VERSION ""

NS_ :

BS_:

BU_: ETH

BO_ 945 DAS_telemetryFurniture: 8 Vector__XXX
 SG_ DAS_TF_multiplexer M : 0|5@1+ (1,0) [0|0] "" Vector__XXX
 SG_ DAS_TF_furnitureIndex0 m0 : 5|8@1+ (1,0) [0|0] "" Vector__XXX
 SG_ DAS_TF_furnitureIndex1 m1 : 5|8@1+ (1,0) [0|0] "" Vector__XXX
 SG_ DAS_TF_furnitureIndex2 m2 : 5|8@1+ (1,0) [0|0] "" Vector__XXX
 SG_ DAS_TF_distTraveled m0 : 13|11@1+ (0.1,0) [0|0] "" Vector__XXX
 SG_ DAS_TF_juncStatus m2 : 13|4@1+ (1,0) [0|0] "" Vector__XXX
 SG_ DAS_TF_longitudinalDist m1 : 13|12@1+ (0.1,0) [0|0] "" Vector__XXX
 SG_ DAS_TF_juncDist m2 : 17|11@1+ (0.2,-20) [0|0] "" Vector__XXX
 SG_ DAS_TF_llType m0 : 24|3@1+ (1,0) [0|0] "" Vector__XXX
 SG_ DAS_TF_lateralDist m1 : 25|12@1+ (0.1,-204.8) [0|0] "" Vector__XXX
 SG_ DAS_TF_rlType m0 : 27|3@1+ (1,0) [0|0] "" Vector__XXX
 SG_ DAS_TF_stopLineDist m2 : 28|11@1+ (0.1,-10) [0|0] "" Vector__XXX
 SG_ DAS_TF_cipvDist m0 : 30|9@1+ (0.1,0) [0|0] "" Vector__XXX
 SG_ DAS_TF_height m1 : 37|12@1+ (0.05,0) [0|0] "" Vector__XXX
 SG_ DAS_TF_timeOfDay m0 : 39|3@1+ (1,0) [0|0] "" Vector__XXX
 SG_ DAS_TF_ttc m2 : 39|7@1+ (0.1,0) [0|0] "" Vector__XXX
 SG_ DAS_TF_furnitureType m0 : 42|3@1+ (1,0) [0|0] "" Vector__XXX
 SG_ DAS_TF_color m1 : 49|3@1+ (1,0) [0|0] "" Vector__XXX
 SG_ DAS_TF_shape m1 : 52|3@1+ (1,0) [0|0] "" Vector__XXX
 SG_ DAS_TF_orientation m1 : 55|2@1+ (1,0) [0|0] "" Vector__XXX
 SG_ DAS_TF_transmissionStatus m1 : 57|2@1+ (1,0) [0|0] "" Vector__XXX
 SG_ DAS_TF_isMain m1 : 59|1@1+ (1,0) [0|0] "" Vector__XXX
 SG_ DAS_TF_isTeslaMain m1 : 60|1@1+ (1,0) [0|0] "" Vector__XXX

BO_ 947 UI_vehicleControl2: 8 Vector__XXX
 SG_ UI_gloveboxRequest : 0|1@1+ (1,0) [0|0] "" Vector__XXX
 SG_ UI_trunkRequest : 1|1@1+ (1,0) [0|0] "" Vector__XXX
 SG_ UI_UMCUpdateInhibit : 2|1@1+ (1,0) [0|0] "" Vector__XXX
 SG_ UI_WCUpdateInhibit : 3|1@1+ (1,0) [0|0] "" Vector__XXX
 SG_ UI_soundHornOnLock : 4|1@1+ (1,0) [0|0] "" Vector__XXX
 SG_ UI_locksPanelActive : 5|1@1+ (1,0) [0|0] "" Vector__XXX
 SG_ UI_PINToDriveEnabled : 6|1@1+ (1,0) [0|0] "" Vector__XXX
 SG_ UI_PINToDrivePassed : 7|1@1+ (1,0) [0|0] "" Vector__XXX
 SG_ UI_disableMirrorAutoDim : 8|1@1+ (1,0) [0|0] "" Vector__XXX
 SG_ UI_lightSwitch : 9|3@1+ (1,0) [0|0] "" Vector__XXX
 SG_ UI_readyToAddKey : 12|1@1+ (1,0) [0|0] "" Vector__XXX
 SG_ UI_alarmTriggerRequest : 13|1@1+ (1,0) [0|0] "" Vector__XXX
 SG_ UI_VCSECFeature1 : 14|1@1+ (1,0) [0|0] "" Vector__XXX
 SG_ UI_VCLEFTFeature1 : 15|1@1+ (1,0) [0|0] "" Vector__XXX
 SG_ UI_summonState : 16|2@1+ (1,0) [0|0] "" Vector__XXX
 SG_ UI_displayOnForUser : 18|1@1+ (1,0) [0|0] "" Vector__XXX
 SG_ UI_freeRollModeRequest : 19|1@1+ (1,0) [0|0] "" Vector__XXX
 SG_ UI_BLEPushNotificationRequest : 20|1@1+ (1,0) [0|0] "" Vector__XXX
 SG_ UI_pairKeyQRCodeDisplaying : 21|1@1+ (1,0) [0|0] "" Vector__XXX
 SG_ UI_keepAutopilotAwake : 22|1@1+ (1,0) [0|0] "" Vector__XXX
 SG_ UI_batteryPreconditioningRequest : 23|1@1+ (1,0) [0|0] "" Vector__XXX
 SG_ UI_coastDownMode : 24|1@1+ (1,0) [0|0] "" Vector__XXX
 SG_ UI_autopilotPowerStateRequest : 25|2@1+ (1,0) [0|0] "" Vector__XXX
 SG_ UI_shorted12VCellTestMode : 27|2@1+ (1,0) [0|0] "" Vector__XXX
 SG_ UI_autoRollWindowsOnLockEnable : 29|1@1+ (1,0) [0|0] "" Vector__XXX
 SG_ UI_virtualPitchSensorOverrideOKForAim : 30|1@1+ (1,0) [0|0] "" Vector__XXX
 SG_ UI_conditionalLoggingEnabledVCSEC : 31|1@1+ (1,0) [0|0] "" Vector__XXX
 SG_ UI_WC3UpdateInhibit : 32|1@1+ (1,0) [0|0] "" Vector__XXX
 SG_ UI_steeringWheelHeatReq : 33|1@1+ (1,0) [0|0] "" Vector__XXX
 SG_ UI_disableHorn : 34|1@1+ (1,0) [0|0] "" Vector__XXX
 SG_ UI_frontRightSeatAutoClimateReq : 39|1@1+ (1,0) [0|0] "" Vector__XXX
 SG_ UI_sleepFeature1 : 51|1@1+ (1,0) [0|0] "" Vector__XXX
 SG_ UI_dcr12VThreshold : 52|4@1+ (1,0) [0|0] "" Vector__XXX
 SG_ UI_frontLeftSeatAutoClimateReq : 56|1@1+ (1,0) [0|0] "" Vector__XXX
 SG_ UI_wiperHeaterReq : 57|1@1+ (1,0) [0|0] "" Vector__XXX
 SG_ UI_tireSeason : 59|1@1+ (1,0) [0|0] "" Vector__XXX
 SG_ UI_saveTireConfigReq : 60|1@1+ (1,0) [0|0] "" Vector__XXX
 SG_ UI_silentAlarm : 61|1@1+ (1,0) [0|0] "" Vector__XXX
 SG_ UI_sleepFeature2 : 63|1@1+ (1,0) [0|0] "" Vector__XXX

BO_ 952 UI_tpmsRCPsetting: 8 Vector__XXX
 SG_ UI_setRCPFront : 16|8@1+ (0.025,0) [0|0] "" Vector__XXX
 SG_ UI_setRCPRear : 24|8@1+ (0.025,0) [0|0] "" Vector__XXX

BO_ 954 USM_alertMatrix: 8 Vector__XXX
 SG_ USM_matrixIndex M : 0|4@1+ (1,0) [0|0] "" Vector__XXX
 SG_ USM_a001_WatchdogReset m0 : 4|1@1+ (1,0) [0|0] "" Vector__XXX
 SG_ USM_a061_XCPConnected m1 : 4|1@1+ (1,0) [0|0] "" Vector__XXX
 SG_ USM_a181_s5Blocked m3 : 4|1@1+ (1,0) [0|0] "" Vector__XXX
 SG_ USM_a241_s2HwComErrDiagnostics m4 : 4|1@1+ (1,0) [0|0] "" Vector__XXX
 SG_ USM_a002_PowerLossReset m0 : 5|1@1+ (1,0) [0|0] "" Vector__XXX
 SG_ USM_a062_XCPWasConnected m1 : 5|1@1+ (1,0) [0|0] "" Vector__XXX
 SG_ USM_a182_s6Blocked m3 : 5|1@1+ (1,0) [0|0] "" Vector__XXX
 SG_ USM_a242_s3HwComErrDiagnostics m4 : 5|1@1+ (1,0) [0|0] "" Vector__XXX
 SG_ USM_a003_SWAssertion m0 : 6|1@1+ (1,0) [0|0] "" Vector__XXX
 SG_ USM_a063_SwitchFault m1 : 6|1@1+ (1,0) [0|0] "" Vector__XXX
 SG_ USM_a183_s7Blocked m3 : 6|1@1+ (1,0) [0|0] "" Vector__XXX
 SG_ USM_a243_s4HwComErrDiagnostics m4 : 6|1@1+ (1,0) [0|0] "" Vector__XXX
 SG_ USM_a064_busSleepReqTimeout m1 : 7|1@1+ (1,0) [0|0] "" Vector__XXX
 SG_ USM_a184_s8Blocked m3 : 7|1@1+ (1,0) [0|0] "" Vector__XXX
 SG_ USM_a244_s5HwComErrDiagnostics m4 : 7|1@1+ (1,0) [0|0] "" Vector__XXX
 SG_ USM_a005_CANTXError m0 : 8|1@1+ (1,0) [0|0] "" Vector__XXX
 SG_ USM_a185_s9Blocked m3 : 8|1@1+ (1,0) [0|0] "" Vector__XXX
 SG_ USM_a245_s6HwComErrDiagnostics m4 : 8|1@1+ (1,0) [0|0] "" Vector__XXX
 SG_ USM_a006_CANTX_cyclicError m0 : 9|1@1+ (1,0) [0|0] "" Vector__XXX
 SG_ USM_a186_s10Blocked m3 : 9|1@1+ (1,0) [0|0] "" Vector__XXX
 SG_ USM_a246_s7HwComErrDiagnostics m4 : 9|1@1+ (1,0) [0|0] "" Vector__XXX
 SG_ USM_a187_s11Blocked m3 : 10|1@1+ (1,0) [0|0] "" Vector__XXX
 SG_ USM_a247_s8HwComErrDiagnostics m4 : 10|1@1+ (1,0) [0|0] "" Vector__XXX
 SG_ USM_a188_s12Blocked m3 : 11|1@1+ (1,0) [0|0] "" Vector__XXX
 SG_ USM_a248_s9HwComErrDiagnostics m4 : 11|1@1+ (1,0) [0|0] "" Vector__XXX
 SG_ USM_a189_s1Disconnected m3 : 12|1@1+ (1,0) [0|0] "" Vector__XXX
 SG_ USM_a249_s10HwComErrDiagnostics m4 : 12|1@1+ (1,0) [0|0] "" Vector__XXX
 SG_ USM_a190_s2Disconnected m3 : 13|1@1+ (1,0) [0|0] "" Vector__XXX
 SG_ USM_a250_s11HwComErrDiagnostics m4 : 13|1@1+ (1,0) [0|0] "" Vector__XXX
 SG_ USM_a131_s1ComError m2 : 14|1@1+ (1,0) [0|0] "" Vector__XXX
 SG_ USM_a191_s3Disconnected m3 : 14|1@1+ (1,0) [0|0] "" Vector__XXX
 SG_ USM_a251_s12HwComErrDiagnostics m4 : 14|1@1+ (1,0) [0|0] "" Vector__XXX
 SG_ USM_a012_CPUReset m0 : 15|1@1+ (1,0) [0|0] "" Vector__XXX
 SG_ USM_a132_s2ComError m2 : 15|1@1+ (1,0) [0|0] "" Vector__XXX
 SG_ USM_a192_s4Disconnected m3 : 15|1@1+ (1,0) [0|0] "" Vector__XXX
 SG_ USM_a252_anyComErrorSet m4 : 15|1@1+ (1,0) [0|0] "" Vector__XXX
 SG_ USM_a013_AlertManagerFault m0 : 16|1@1+ (1,0) [0|0] "" Vector__XXX
 SG_ USM_a133_s3ComError m2 : 16|1@1+ (1,0) [0|0] "" Vector__XXX
 SG_ USM_a193_s5Disconnected m3 : 16|1@1+ (1,0) [0|0] "" Vector__XXX
 SG_ USM_a253_anyHwErrorSet m4 : 16|1@1+ (1,0) [0|0] "" Vector__XXX
 SG_ USM_a134_s4ComError m2 : 17|1@1+ (1,0) [0|0] "" Vector__XXX
 SG_ USM_a194_s6Disconnected m3 : 17|1@1+ (1,0) [0|0] "" Vector__XXX
 SG_ USM_a254_frontSensorsOvercurrent m4 : 17|1@1+ (1,0) [0|0] "" Vector__XXX
 SG_ USM_a015_NVMMError m0 : 18|1@1+ (1,0) [0|0] "" Vector__XXX
 SG_ USM_a135_s5ComError m2 : 18|1@1+ (1,0) [0|0] "" Vector__XXX
 SG_ USM_a195_s7Disconnected m3 : 18|1@1+ (1,0) [0|0] "" Vector__XXX
 SG_ USM_a255_rearSensorsOvercurrent m4 : 18|1@1+ (1,0) [0|0] "" Vector__XXX
 SG_ USM_a016_NVMMRecordError m0 : 19|1@1+ (1,0) [0|0] "" Vector__XXX
 SG_ USM_a136_s6ComError m2 : 19|1@1+ (1,0) [0|0] "" Vector__XXX
 SG_ USM_a196_s8Disconnected m3 : 19|1@1+ (1,0) [0|0] "" Vector__XXX
 SG_ USM_a137_s7ComError m2 : 20|1@1+ (1,0) [0|0] "" Vector__XXX
 SG_ USM_a197_s9Disconnected m3 : 20|1@1+ (1,0) [0|0] "" Vector__XXX
 SG_ USM_a138_s8ComError m2 : 21|1@1+ (1,0) [0|0] "" Vector__XXX
 SG_ USM_a198_s10Disconnected m3 : 21|1@1+ (1,0) [0|0] "" Vector__XXX
 SG_ USM_a139_s9ComError m2 : 22|1@1+ (1,0) [0|0] "" Vector__XXX
 SG_ USM_a199_s11Disconnected m3 : 22|1@1+ (1,0) [0|0] "" Vector__XXX
 SG_ USM_a140_s10ComError m2 : 23|1@1+ (1,0) [0|0] "" Vector__XXX
 SG_ USM_a200_s12Disconnected m3 : 23|1@1+ (1,0) [0|0] "" Vector__XXX
 SG_ USM_a021_TaskSchedulerError m0 : 24|1@1+ (1,0) [0|0] "" Vector__XXX
 SG_ USM_a141_s11ComError m2 : 24|1@1+ (1,0) [0|0] "" Vector__XXX
 SG_ USM_a201_e52142Fault m3 : 24|1@1+ (1,0) [0|0] "" Vector__XXX
 SG_ USM_a022_TaskInitError m0 : 25|1@1+ (1,0) [0|0] "" Vector__XXX
 SG_ USM_a082_VCRIGHT_IPC_MIA m1 : 25|1@1+ (1,0) [0|0] "" Vector__XXX
 SG_ USM_a142_s12ComError m2 : 25|1@1+ (1,0) [0|0] "" Vector__XXX
 SG_ USM_a202_e52417Fault m3 : 25|1@1+ (1,0) [0|0] "" Vector__XXX
 SG_ USM_a083_VCLEFT_IPC_MIA m1 : 26|1@1+ (1,0) [0|0] "" Vector__XXX
 SG_ USM_a143_s1HwError m2 : 26|1@1+ (1,0) [0|0] "" Vector__XXX
 SG_ USM_a203_s1NearFieldDetected m3 : 26|1@1+ (1,0) [0|0] "" Vector__XXX
 SG_ USM_a084_TPMS_MIA m1 : 27|1@1+ (1,0) [0|0] "" Vector__XXX
 SG_ USM_a144_s2HwError m2 : 27|1@1+ (1,0) [0|0] "" Vector__XXX
 SG_ USM_a204_s2NearFieldDetected m3 : 27|1@1+ (1,0) [0|0] "" Vector__XXX
 SG_ USM_a085_CCCM_MIA m1 : 28|1@1+ (1,0) [0|0] "" Vector__XXX
 SG_ USM_a145_s3HwError m2 : 28|1@1+ (1,0) [0|0] "" Vector__XXX
 SG_ USM_a205_s3NearFieldDetected m3 : 28|1@1+ (1,0) [0|0] "" Vector__XXX
 SG_ USM_a086_VCBATT_MIA m1 : 29|1@1+ (1,0) [0|0] "" Vector__XXX
 SG_ USM_a146_s4HwError m2 : 29|1@1+ (1,0) [0|0] "" Vector__XXX
 SG_ USM_a206_s4NearFieldDetected m3 : 29|1@1+ (1,0) [0|0] "" Vector__XXX
 SG_ USM_a087_DIREL_MIA m1 : 30|1@1+ (1,0) [0|0] "" Vector__XXX
 SG_ USM_a147_s5HwError m2 : 30|1@1+ (1,0) [0|0] "" Vector__XXX
 SG_ USM_a207_s5NearFieldDetected m3 : 30|1@1+ (1,0) [0|0] "" Vector__XXX
 SG_ USM_a088_DIRER_MIA m1 : 31|1@1+ (1,0) [0|0] "" Vector__XXX
 SG_ USM_a148_s6HwError m2 : 31|1@1+ (1,0) [0|0] "" Vector__XXX
 SG_ USM_a208_s6NearFieldDetected m3 : 31|1@1+ (1,0) [0|0] "" Vector__XXX
 SG_ USM_a029_CoreDump m0 : 32|1@1+ (1,0) [0|0] "" Vector__XXX
 SG_ USM_a089_IBST_MIA m1 : 32|1@1+ (1,0) [0|0] "" Vector__XXX
 SG_ USM_a149_s7HwError m2 : 32|1@1+ (1,0) [0|0] "" Vector__XXX
 SG_ USM_a209_s7NearFieldDetected m3 : 32|1@1+ (1,0) [0|0] "" Vector__XXX
 SG_ USM_a030_ECULogUploadRequest m0 : 33|1@1+ (1,0) [0|0] "" Vector__XXX
 SG_ USM_a090_APS_MIA m1 : 33|1@1+ (1,0) [0|0] "" Vector__XXX
 SG_ USM_a150_s8HwError m2 : 33|1@1+ (1,0) [0|0] "" Vector__XXX
 SG_ USM_a210_s8NearFieldDetected m3 : 33|1@1+ (1,0) [0|0] "" Vector__XXX
 SG_ USM_a031_UDSActive m0 : 34|1@1+ (1,0) [0|0] "" Vector__XXX
 SG_ USM_a091_CMPD_MIA m1 : 34|1@1+ (1,0) [0|0] "" Vector__XXX
 SG_ USM_a151_s9HwError m2 : 34|1@1+ (1,0) [0|0] "" Vector__XXX
 SG_ USM_a211_s9NearFieldDetected m3 : 34|1@1+ (1,0) [0|0] "" Vector__XXX
 SG_ USM_a092_VCSEATD_MIA m1 : 35|1@1+ (1,0) [0|0] "" Vector__XXX
 SG_ USM_a152_s10HwError m2 : 35|1@1+ (1,0) [0|0] "" Vector__XXX
 SG_ USM_a212_s10NearFieldDetected m3 : 35|1@1+ (1,0) [0|0] "" Vector__XXX
 SG_ USM_a093_VCSEATP_MIA m1 : 36|1@1+ (1,0) [0|0] "" Vector__XXX
 SG_ USM_a153_s11HwError m2 : 36|1@1+ (1,0) [0|0] "" Vector__XXX
 SG_ USM_a213_s11NearFieldDetected m3 : 36|1@1+ (1,0) [0|0] "" Vector__XXX
 SG_ USM_a094_EPAS3P_MIA m1 : 37|1@1+ (1,0) [0|0] "" Vector__XXX
 SG_ USM_a154_s12HwError m2 : 37|1@1+ (1,0) [0|0] "" Vector__XXX
 SG_ USM_a214_s12NearFieldDetected m3 : 37|1@1+ (1,0) [0|0] "" Vector__XXX
 SG_ USM_a095_CHG_MIA m1 : 38|1@1+ (1,0) [0|0] "" Vector__XXX
 SG_ USM_a155_s1OverTemp m2 : 38|1@1+ (1,0) [0|0] "" Vector__XXX
 SG_ USM_a215_s1DebugEepromInvalid m3 : 38|1@1+ (1,0) [0|0] "" Vector__XXX
 SG_ USM_a096_OCS1P_MIA m1 : 39|1@1+ (1,0) [0|0] "" Vector__XXX
 SG_ USM_a156_s2OverTemp m2 : 39|1@1+ (1,0) [0|0] "" Vector__XXX
 SG_ USM_a216_s2DebugEepromInvalid m3 : 39|1@1+ (1,0) [0|0] "" Vector__XXX
 SG_ USM_a097_CMP_MIA m1 : 40|1@1+ (1,0) [0|0] "" Vector__XXX
 SG_ USM_a157_s3OverTemp m2 : 40|1@1+ (1,0) [0|0] "" Vector__XXX
 SG_ USM_a217_s3DebugEepromInvalid m3 : 40|1@1+ (1,0) [0|0] "" Vector__XXX
 SG_ USM_a098_DIR_MIA m1 : 41|1@1+ (1,0) [0|0] "" Vector__XXX
 SG_ USM_a158_s4OverTemp m2 : 41|1@1+ (1,0) [0|0] "" Vector__XXX
 SG_ USM_a218_s4DebugEepromInvalid m3 : 41|1@1+ (1,0) [0|0] "" Vector__XXX
 SG_ USM_a099_PARK_MIA m1 : 42|1@1+ (1,0) [0|0] "" Vector__XXX
 SG_ USM_a159_s5OverTemp m2 : 42|1@1+ (1,0) [0|0] "" Vector__XXX
 SG_ USM_a219_s5DebugEepromInvalid m3 : 42|1@1+ (1,0) [0|0] "" Vector__XXX
 SG_ USM_a100_CANbus_MIA m1 : 43|1@1+ (1,0) [0|0] "" Vector__XXX
 SG_ USM_a160_s6OverTemp m2 : 43|1@1+ (1,0) [0|0] "" Vector__XXX
 SG_ USM_a220_s6DebugEepromInvalid m3 : 43|1@1+ (1,0) [0|0] "" Vector__XXX
 SG_ USM_a041_HighCPULoad m0 : 44|1@1+ (1,0) [0|0] "" Vector__XXX
 SG_ USM_a101_PM_MIA m1 : 44|1@1+ (1,0) [0|0] "" Vector__XXX
 SG_ USM_a161_s7OverTemp m2 : 44|1@1+ (1,0) [0|0] "" Vector__XXX
 SG_ USM_a221_s7DebugEepromInvalid m3 : 44|1@1+ (1,0) [0|0] "" Vector__XXX
 SG_ USM_a042_HighStackUsage m0 : 45|1@1+ (1,0) [0|0] "" Vector__XXX
 SG_ USM_a102_PTC_MIA m1 : 45|1@1+ (1,0) [0|0] "" Vector__XXX
 SG_ USM_a162_s8OverTemp m2 : 45|1@1+ (1,0) [0|0] "" Vector__XXX
 SG_ USM_a222_s8DebugEepromInvalid m3 : 45|1@1+ (1,0) [0|0] "" Vector__XXX
 SG_ USM_a043_Task1msError m0 : 46|1@1+ (1,0) [0|0] "" Vector__XXX
 SG_ USM_a103_CP_MIA m1 : 46|1@1+ (1,0) [0|0] "" Vector__XXX
 SG_ USM_a163_s9OverTemp m2 : 46|1@1+ (1,0) [0|0] "" Vector__XXX
 SG_ USM_a223_s9DebugEepromInvalid m3 : 46|1@1+ (1,0) [0|0] "" Vector__XXX
 SG_ USM_a044_Task10msError m0 : 47|1@1+ (1,0) [0|0] "" Vector__XXX
 SG_ USM_a104_DAS_MIA m1 : 47|1@1+ (1,0) [0|0] "" Vector__XXX
 SG_ USM_a164_s10OverTemp m2 : 47|1@1+ (1,0) [0|0] "" Vector__XXX
 SG_ USM_a224_s10DebugEepromInvalid m3 : 47|1@1+ (1,0) [0|0] "" Vector__XXX
 SG_ USM_a045_Task100msError m0 : 48|1@1+ (1,0) [0|0] "" Vector__XXX
 SG_ USM_a105_TAS_MIA m1 : 48|1@1+ (1,0) [0|0] "" Vector__XXX
 SG_ USM_a165_s11OverTemp m2 : 48|1@1+ (1,0) [0|0] "" Vector__XXX
 SG_ USM_a225_s11DebugEepromInvalid m3 : 48|1@1+ (1,0) [0|0] "" Vector__XXX
 SG_ USM_a046_Task1000msError m0 : 49|1@1+ (1,0) [0|0] "" Vector__XXX
 SG_ USM_a106_PCS_MIA m1 : 49|1@1+ (1,0) [0|0] "" Vector__XXX
 SG_ USM_a166_s12OverTemp m2 : 49|1@1+ (1,0) [0|0] "" Vector__XXX
 SG_ USM_a226_s12DebugEepromInvalid m3 : 49|1@1+ (1,0) [0|0] "" Vector__XXX
 SG_ USM_a107_BMS_MIA m1 : 50|1@1+ (1,0) [0|0] "" Vector__XXX
 SG_ USM_a227_s1InitError m3 : 50|1@1+ (1,0) [0|0] "" Vector__XXX
 SG_ USM_a108_DIF_MIA m1 : 51|1@1+ (1,0) [0|0] "" Vector__XXX
 SG_ USM_a228_s2InitError m3 : 51|1@1+ (1,0) [0|0] "" Vector__XXX
 SG_ USM_a109_RCM_MIA m1 : 52|1@1+ (1,0) [0|0] "" Vector__XXX
 SG_ USM_a229_s3InitError m3 : 52|1@1+ (1,0) [0|0] "" Vector__XXX
 SG_ USM_a110_GTW_MIA m1 : 53|1@1+ (1,0) [0|0] "" Vector__XXX
 SG_ USM_a230_s4InitError m3 : 53|1@1+ (1,0) [0|0] "" Vector__XXX
 SG_ USM_a111_EPBR_MIA m1 : 54|1@1+ (1,0) [0|0] "" Vector__XXX
 SG_ USM_a231_s5InitError m3 : 54|1@1+ (1,0) [0|0] "" Vector__XXX
 SG_ USM_a112_EPBL_MIA m1 : 55|1@1+ (1,0) [0|0] "" Vector__XXX
 SG_ USM_a232_s6InitError m3 : 55|1@1+ (1,0) [0|0] "" Vector__XXX
 SG_ USM_a113_UI_MIA m1 : 56|1@1+ (1,0) [0|0] "" Vector__XXX
 SG_ USM_a233_s7InitError m3 : 56|1@1+ (1,0) [0|0] "" Vector__XXX
 SG_ USM_a114_ESP_MIA m1 : 57|1@1+ (1,0) [0|0] "" Vector__XXX
 SG_ USM_a234_s8InitError m3 : 57|1@1+ (1,0) [0|0] "" Vector__XXX
 SG_ USM_a115_VCSEC_MIA m1 : 58|1@1+ (1,0) [0|0] "" Vector__XXX
 SG_ USM_a235_s9InitError m3 : 58|1@1+ (1,0) [0|0] "" Vector__XXX
 SG_ USM_a116_VCRIGHT_MIA m1 : 59|1@1+ (1,0) [0|0] "" Vector__XXX
 SG_ USM_a236_s10InitError m3 : 59|1@1+ (1,0) [0|0] "" Vector__XXX
 SG_ USM_a057_HVP_MIA m0 : 60|1@1+ (1,0) [0|0] "" Vector__XXX
 SG_ USM_a117_VCLEFT_MIA m1 : 60|1@1+ (1,0) [0|0] "" Vector__XXX
 SG_ USM_a177_s1Blocked m2 : 60|1@1+ (1,0) [0|0] "" Vector__XXX
 SG_ USM_a237_s11InitError m3 : 60|1@1+ (1,0) [0|0] "" Vector__XXX
 SG_ USM_a058_inputRHighSyncDebug m0 : 61|1@1+ (1,0) [0|0] "" Vector__XXX
 SG_ USM_a118_VCFRONT_MIA m1 : 61|1@1+ (1,0) [0|0] "" Vector__XXX
 SG_ USM_a178_s2Blocked m2 : 61|1@1+ (1,0) [0|0] "" Vector__XXX
 SG_ USM_a238_s12InitError m3 : 61|1@1+ (1,0) [0|0] "" Vector__XXX
 SG_ USM_a059_inputResistanceHigh m0 : 62|1@1+ (1,0) [0|0] "" Vector__XXX
 SG_ USM_a119_SCCM_MIA m1 : 62|1@1+ (1,0) [0|0] "" Vector__XXX
 SG_ USM_a179_s3Blocked m2 : 62|1@1+ (1,0) [0|0] "" Vector__XXX
 SG_ USM_a060_engineeringBuild m0 : 63|1@1+ (1,0) [0|0] "" Vector__XXX
 SG_ USM_a120_DI_DRIVE_MIA m1 : 63|1@1+ (1,0) [0|0] "" Vector__XXX
 SG_ USM_a180_s4Blocked m2 : 63|1@1+ (1,0) [0|0] "" Vector__XXX
 SG_ USM_a240_s1HwComErrDiagnostics m3 : 63|1@1+ (1,0) [0|0] "" Vector__XXX

BO_ 962 VCLEFT_switchStatus: 8 Vector__XXX
 SG_ VCLEFT_switchStatusIndex M : 0|1@1+ (1,0) [0|0] "" Vector__XXX
 SG_ VCLEFT_hornSwitchPressed m0 : 2|1@1+ (1,0) [0|0] "" Vector__XXX
 SG_ VCLEFT_isAlcoholInterlockSet m1 : 2|1@1+ (1,0) [0|0] "" Vector__XXX
 SG_ VCLEFT_hazardButtonPressed m0 : 3|1@1+ (1,0) [0|0] "" Vector__XXX
 SG_ VCLEFT_swcLeftTiltRight m1 : 3|2@1+ (1,0) [0|0] "" Vector__XXX
 SG_ VCLEFT_brakeSwitchPressed m0 : 4|1@1+ (1,0) [0|0] "" Vector__XXX
 SG_ VCLEFT_rightMirrorTilt m0 : 5|3@1+ (1,0) [0|0] "" Vector__XXX
 SG_ VCLEFT_swcLeftPressed m1 : 5|2@1+ (1,0) [0|0] "" Vector__XXX
 SG_ VCLEFT_frontSeatTrackBack m0 : 8|2@1+ (1,0) [0|0] "" Vector__XXX
 SG_ VCLEFT_swcRightTiltLeft m1 : 8|2@1+ (1,0) [0|0] "" Vector__XXX
 SG_ VCLEFT_frontSeatTrackForward m0 : 10|2@1+ (1,0) [0|0] "" Vector__XXX
 SG_ VCLEFT_swcRightTiltRight m1 : 10|2@1+ (1,0) [0|0] "" Vector__XXX
 SG_ VCLEFT_frontSeatTiltDown m0 : 12|2@1+ (1,0) [0|0] "" Vector__XXX
 SG_ VCLEFT_swcRightPressed m1 : 12|2@1+ (1,0) [0|0] "" Vector__XXX
 SG_ VCLEFT_frontSeatTiltUp m0 : 14|2@1+ (1,0) [0|0] "" Vector__XXX
 SG_ VCLEFT_swcLeftTiltLeft m1 : 14|2@1+ (1,0) [0|0] "" Vector__XXX
 SG_ VCLEFT_frontSeatLiftDown m0 : 16|2@1+ (1,0) [0|0] "" Vector__XXX
 SG_ VCLEFT_swcLeftScrollTicks m1 : 16|6@1- (1,0) [0|0] "" Vector__XXX
 SG_ VCLEFT_frontSeatLiftUp m0 : 18|2@1+ (1,0) [0|0] "" Vector__XXX
 SG_ VCLEFT_frontSeatBackrestBack m0 : 20|2@1+ (1,0) [0|0] "" Vector__XXX
 SG_ VCLEFT_frontSeatBackrestForward m0 : 22|2@1+ (1,0) [0|0] "" Vector__XXX
 SG_ VCLEFT_frontSeatLumbarDown m0 : 24|2@1+ (1,0) [0|0] "" Vector__XXX
 SG_ VCLEFT_swcRightScrollTicks m1 : 24|6@1- (1,0) [0|0] "" Vector__XXX
 SG_ VCLEFT_frontSeatLumbarUp m0 : 26|2@1+ (1,0) [0|0] "" Vector__XXX
 SG_ VCLEFT_frontSeatLumbarIn m0 : 28|2@1+ (1,0) [0|0] "" Vector__XXX
 SG_ VCLEFT_frontSeatLumbarOut m0 : 30|2@1+ (1,0) [0|0] "" Vector__XXX
 SG_ VCLEFT_btnWindowSwPackUpLF m0 : 32|1@1+ (1,0) [0|0] "" Vector__XXX
 SG_ VCLEFT_btnWindowUpLR m1 : 32|1@1+ (1,0) [0|0] "" Vector__XXX
 SG_ VCLEFT_btnWindowAutoUpLR m1 : 33|1@1+ (1,0) [0|0] "" Vector__XXX
 SG_ VCLEFT_btnWindowSwPackAutoUpLF m0 : 33|1@1+ (1,0) [0|0] "" Vector__XXX
 SG_ VCLEFT_btnWindowDownLR m1 : 34|1@1+ (1,0) [0|0] "" Vector__XXX
 SG_ VCLEFT_btnWindowSwPackDownLF m0 : 34|1@1+ (1,0) [0|0] "" Vector__XXX
 SG_ VCLEFT_btnWindowAutoDownLR m1 : 35|1@1+ (1,0) [0|0] "" Vector__XXX
 SG_ VCLEFT_btnWindowSwPackAutoDownLF m0 : 35|1@1+ (1,0) [0|0] "" Vector__XXX
 SG_ VCLEFT_2RowSeatReclineSwitch m1 : 36|1@1+ (1,0) [0|0] "" Vector__XXX
 SG_ VCLEFT_btnWindowSwPackUpLR m0 : 36|1@1+ (1,0) [0|0] "" Vector__XXX
 SG_ VCLEFT_2RowSeatCenterSwitch m1 : 37|1@1+ (1,0) [0|0] "" Vector__XXX
 SG_ VCLEFT_btnWindowSwPackAutoUpLR m0 : 37|1@1+ (1,0) [0|0] "" Vector__XXX
 SG_ VCLEFT_2RowSeatLeftFoldFlatSwitch m1 : 38|1@1+ (1,0) [0|0] "" Vector__XXX
 SG_ VCLEFT_btnWindowSwPackDownLR m0 : 38|1@1+ (1,0) [0|0] "" Vector__XXX
 SG_ VCLEFT_2RowSeatRightFoldFlatSwitch m1 : 39|1@1+ (1,0) [0|0] "" Vector__XXX
 SG_ VCLEFT_btnWindowSwPackAutoDownLR m0 : 39|1@1+ (1,0) [0|0] "" Vector__XXX
 SG_ VCLEFT_2RowSeatBothFoldFlatSwitch m1 : 40|1@1+ (1,0) [0|0] "" Vector__XXX
 SG_ VCLEFT_btnWindowSwPackUpRF m0 : 40|1@1+ (1,0) [0|0] "" Vector__XXX
 SG_ VCLEFT_btnWindowSwPackAutoUpRF m0 : 41|1@1+ (1,0) [0|0] "" Vector__XXX
 SG_ VCLEFT_swcLeftDoublePress m1 : 41|1@1+ (1,0) [0|0] "" Vector__XXX
 SG_ VCLEFT_btnWindowSwPackDownRF m0 : 42|1@1+ (1,0) [0|0] "" Vector__XXX
 SG_ VCLEFT_swcRightDoublePress m1 : 42|1@1+ (1,0) [0|0] "" Vector__XXX
 SG_ VCLEFT_2RowSeatBackrestFoldSwitch m1 : 43|1@1+ (1,0) [0|0] "" Vector__XXX
 SG_ VCLEFT_btnWindowSwPackAutoDownRF m0 : 43|1@1+ (1,0) [0|0] "" Vector__XXX
 SG_ VCLEFT_btnWindowSwPackUpRR m0 : 44|1@1+ (1,0) [0|0] "" Vector__XXX
 SG_ VCLEFT_btnWindowSwPackAutoUpRR m0 : 45|1@1+ (1,0) [0|0] "" Vector__XXX
 SG_ VCLEFT_btnWindowSwPackDownRR m0 : 46|1@1+ (1,0) [0|0] "" Vector__XXX
 SG_ VCLEFT_btnWindowSwPackAutoDownRR m0 : 47|1@1+ (1,0) [0|0] "" Vector__XXX
 SG_ VCLEFT_frontBuckleSwitch m0 : 48|2@1+ (1,0) [0|0] "" Vector__XXX
 SG_ VCLEFT_frontOccupancySwitch m0 : 50|2@1+ (1,0) [0|0] "" Vector__XXX
 SG_ VCLEFT_rearLeftBuckleSwitch m0 : 52|2@1+ (1,0) [0|0] "" Vector__XXX
 SG_ VCLEFT_rearCenterOccupancySwitch m0 : 54|2@1+ (1,0) [0|0] "" Vector__XXX
 SG_ VCLEFT_rearLeftOccupancySwitch m0 : 56|2@1+ (1,0) [0|0] "" Vector__XXX
 SG_ VCLEFT_rearRightOccupancySwitch m0 : 58|2@1+ (1,0) [0|0] "" Vector__XXX
 SG_ VCLEFT_brakePressed m0 : 60|1@1+ (1,0) [0|0] "" Vector__XXX
 SG_ VCLEFT_rearHVACButtonPressed m0 : 61|1@1+ (1,0) [0|0] "" Vector__XXX
 SG_ VCLEFT_frontSeatResistiveOccupancy m1 : 62|2@1+ (1,0) [0|0] "" Vector__XXX
 SG_ VCLEFT_rearCenterBuckleSwitch m0 : 62|2@1+ (1,0) [0|0] "" Vector__XXX

BO_ 963 VCRIGHT_switchStatus: 8 Vector__XXX
 SG_ VCRIGHT_switchStatusIndex M : 0|1@1+ (1,0) [0|0] "" Vector__XXX
 SG_ VCRIGHT_trunkExtReleasePressedPersist m1 : 1|1@1+ (1,0) [0|0] "" Vector__XXX
 SG_ VCRIGHT_frontSeatTrackBack m1 : 2|2@1+ (1,0) [0|0] "" Vector__XXX
 SG_ VCRIGHT_frontSeatTrackForward m1 : 4|2@1+ (1,0) [0|0] "" Vector__XXX
 SG_ VCRIGHT_frontSeatTiltDown m1 : 6|2@1+ (1,0) [0|0] "" Vector__XXX
 SG_ VCRIGHT_frontSeatTiltUp m1 : 8|2@1+ (1,0) [0|0] "" Vector__XXX
 SG_ VCRIGHT_frontSeatLiftDown m1 : 10|2@1+ (1,0) [0|0] "" Vector__XXX
 SG_ VCRIGHT_frontSeatLiftUp m1 : 12|2@1+ (1,0) [0|0] "" Vector__XXX
 SG_ VCRIGHT_frontSeatBackrestBack m1 : 14|2@1+ (1,0) [0|0] "" Vector__XXX
 SG_ VCRIGHT_frontSeatBackrestForward m1 : 16|2@1+ (1,0) [0|0] "" Vector__XXX
 SG_ VCRIGHT_frontSeatLumbarDown m1 : 18|2@1+ (1,0) [0|0] "" Vector__XXX
 SG_ VCRIGHT_frontSeatLumbarUp m1 : 20|2@1+ (1,0) [0|0] "" Vector__XXX
 SG_ VCRIGHT_frontSeatLumbarIn m1 : 22|2@1+ (1,0) [0|0] "" Vector__XXX
 SG_ VCRIGHT_btnWindowUpRF m0 : 24|1@1+ (1,0) [0|0] "" Vector__XXX
 SG_ VCRIGHT_frontSeatLumbarOut m1 : 24|2@1+ (1,0) [0|0] "" Vector__XXX
 SG_ VCRIGHT_btnWindowAutoUpRF m0 : 25|1@1+ (1,0) [0|0] "" Vector__XXX
 SG_ VCRIGHT_2RowSeatReclineSwitch m1 : 26|1@1+ (1,0) [0|0] "" Vector__XXX
 SG_ VCRIGHT_btnWindowDownRF m0 : 26|1@1+ (1,0) [0|0] "" Vector__XXX
 SG_ VCRIGHT_2RowSeatBackrestFoldSwitch m1 : 27|1@1+ (1,0) [0|0] "" Vector__XXX
 SG_ VCRIGHT_btnWindowAutoDownRF m0 : 27|1@1+ (1,0) [0|0] "" Vector__XXX
 SG_ VCRIGHT_btnWindowUpRR m0 : 28|1@1+ (1,0) [0|0] "" Vector__XXX
 SG_ VCRIGHT_btnWindowAutoUpRR m0 : 29|1@1+ (1,0) [0|0] "" Vector__XXX
 SG_ VCRIGHT_btnWindowDownRR m0 : 30|1@1+ (1,0) [0|0] "" Vector__XXX
 SG_ VCRIGHT_btnWindowAutoDownRR m0 : 31|1@1+ (1,0) [0|0] "" Vector__XXX
 SG_ VCRIGHT_btnWindowSwPackUpLF m0 : 32|1@1+ (1,0) [0|0] "" Vector__XXX
 SG_ VCRIGHT_frontHandlePWM m1 : 32|7@1+ (1,0) [0|0] "" Vector__XXX
 SG_ VCRIGHT_btnWindowSwPackAutoUpLF m0 : 33|1@1+ (1,0) [0|0] "" Vector__XXX
 SG_ VCRIGHT_btnWindowSwPackDownLF m0 : 34|1@1+ (1,0) [0|0] "" Vector__XXX
 SG_ VCRIGHT_btnWindowSwPackAutoDwnLF m0 : 35|1@1+ (1,0) [0|0] "" Vector__XXX
 SG_ VCRIGHT_btnWindowSwPackUpLR m0 : 36|1@1+ (1,0) [0|0] "" Vector__XXX
 SG_ VCRIGHT_btnWindowSwPackAutoUpLR m0 : 37|1@1+ (1,0) [0|0] "" Vector__XXX
 SG_ VCRIGHT_btnWindowSwPackDownLR m0 : 38|1@1+ (1,0) [0|0] "" Vector__XXX
 SG_ VCRIGHT_btnWindowSwPackAutoDwnLR m0 : 39|1@1+ (1,0) [0|0] "" Vector__XXX
 SG_ VCRIGHT_hvacHeatingAllowedLeft m1 : 39|1@1+ (1,0) [0|0] "" Vector__XXX
 SG_ VCRIGHT_frontBuckleSwitch m0 : 40|2@1+ (1,0) [0|0] "" Vector__XXX
 SG_ VCRIGHT_rearHandlePWM m1 : 40|7@1+ (1,0) [0|0] "" Vector__XXX
 SG_ VCRIGHT_frontOccupancySwitch m0 : 42|2@1+ (1,0) [0|0] "" Vector__XXX
 SG_ VCRIGHT_rearCenterBuckleSwitch m0 : 44|2@1+ (1,0) [0|0] "" Vector__XXX
 SG_ VCRIGHT_rearRightBuckleSwitch m0 : 46|2@1+ (1,0) [0|0] "" Vector__XXX
 SG_ VCRIGHT_gloveboxLightCurrent m1 : 47|5@1+ (2,0) [0|0] "" Vector__XXX
 SG_ VCRIGHT_trunkExtReleasePressed m0 : 48|1@1+ (1,0) [0|0] "" Vector__XXX
 SG_ VCRIGHT_btnWindowSwPackUpRR m0 : 49|1@1+ (1,0) [0|0] "" Vector__XXX
 SG_ VCRIGHT_btnWindowSwPackAutoUpRR m0 : 50|1@1+ (1,0) [0|0] "" Vector__XXX
 SG_ VCRIGHT_btnWindowSwPackDownRR m0 : 51|1@1+ (1,0) [0|0] "" Vector__XXX
 SG_ VCRIGHT_btnWindowSwPackAutoDwnRR m0 : 52|1@1+ (1,0) [0|0] "" Vector__XXX
 SG_ VCRIGHT_liftgateShutfaceSwitchPressed m0 : 53|1@1+ (1,0) [0|0] "" Vector__XXX
 SG_ VCRIGHT_frontSeatResistiveOccupancy m1 : 54|2@1+ (1,0) [0|0] "" Vector__XXX
 SG_ VCRIGHT_rearRightOccupancySwitch m0 : 54|2@1+ (1,0) [0|0] "" Vector__XXX
 SG_ VCRIGHT_3RowLeftOccupancySwitch m0 : 56|2@1+ (1,0) [0|0] "" Vector__XXX
 SG_ VCRIGHT_3RowRightOccupancySwitch m0 : 58|2@1+ (1,0) [0|0] "" Vector__XXX
 SG_ VCRIGHT_hvacHeatingAllowedRight m1 : 59|1@1+ (1,0) [0|0] "" Vector__XXX
 SG_ VCRIGHT_3RowLeftBuckleSwitch m0 : 60|2@1+ (1,0) [0|0] "" Vector__XXX
 SG_ VCRIGHT_3RowRightBuckleSwitch m0 : 62|2@1+ (1,0) [0|0] "" Vector__XXX

BO_ 969 APS_status: 8 Vector__XXX
 SG_ APS_appStatusMonitorState : 0|3@1+ (1,0) [0|0] "" Vector__XXX
 SG_ APS_vehBehaviorState : 4|4@1+ (1,0) [0|0] "" Vector__XXX
 SG_ APS_canMaster : 8|2@1+ (1,0) [0|0] "" Vector__XXX
 SG_ APS_appGpioState : 10|2@1+ (1,0) [0|0] "" Vector__XXX
 SG_ APS_eacInternalState : 12|3@1+ (1,0) [0|0] "" Vector__XXX
 SG_ APS_switchState : 15|1@1+ (1,0) [0|0] "" Vector__XXX
 SG_ APS_apbStatusMonitorState : 16|3@1+ (1,0) [0|0] "" Vector__XXX
 SG_ APS_apbGpioState : 20|2@1+ (1,0) [0|0] "" Vector__XXX
 SG_ APS_statusCounter : 22|4@1+ (1,0) [0|0] "" Vector__XXX
 SG_ APS_locLimitReason : 26|3@1+ (1,0) [0|0] "" Vector__XXX
 SG_ APS_appPowerStateRequest : 29|2@1+ (1,0) [0|0] "" Vector__XXX
 SG_ APS_appPowerStateReason : 31|4@1+ (1,0) [0|0] "" Vector__XXX
 SG_ APS_apbPowerStateRequest : 35|2@1+ (1,0) [0|0] "" Vector__XXX
 SG_ APS_apbPowerStateReason : 37|4@1+ (1,0) [0|0] "" Vector__XXX
 SG_ APS_heaterStateDebug : 41|3@1+ (1,0) [0|0] "" Vector__XXX
 SG_ APS_autosummonCounter : 44|3@1+ (1,0) [0|0] "" Vector__XXX
 SG_ APS_autosummonAlert : 47|1@1+ (1,0) [0|0] "" Vector__XXX
 SG_ APS_gpsAntennaState : 48|2@1+ (1,0) [0|0] "" Vector__XXX
 SG_ APS_arbState : 50|3@1+ (1,0) [0|0] "" Vector__XXX
 SG_ APS_socPowerOperatingMode : 53|2@1+ (1,0) [0|0] "" Vector__XXX
 SG_ APS_otherArbState : 55|3@1+ (1,0) [0|0] "" Vector__XXX
 SG_ APS_appActivePlannerType : 58|3@1+ (1,0) [0|0] "" Vector__XXX
 SG_ APS_apbActivePlannerType : 61|3@1+ (1,0) [0|0] "" Vector__XXX

BO_ 970 DAS_gpsStatus: 8 Vector__XXX
 SG_ DAS_gpsStatusMultiplexer M : 0|4@1+ (1,0) [0|0] "" Vector__XXX
 SG_ DAS_gnssMaxInstantaneousCnorGps m2 : 4|6@1+ (1,0) [0|0] "" Vector__XXX
 SG_ DAS_gnssNumSatsGps m3 : 4|4@1+ (1,0) [0|0] "" Vector__XXX
 SG_ DAS_gpsRxmRawxMia m1 : 4|1@1+ (1,0) [0|0] "" Vector__XXX
 SG_ DAS_gpsTransportModeState m0 : 4|1@1+ (1,0) [0|0] "" Vector__XXX
 SG_ DAS_gpsRxmSfrbxMia m1 : 5|1@1+ (1,0) [0|0] "" Vector__XXX
 SG_ DAS_gpsSatsInUseHardware m0 : 5|4@1+ (1,0) [0|0] "" Vector__XXX
 SG_ DAS_gpsEsfMeasMia m1 : 6|1@1+ (1,0) [0|0] "" Vector__XXX
 SG_ DAS_gpsEsfRawMia m1 : 7|1@1+ (1,0) [0|0] "" Vector__XXX
 SG_ DAS_gnssNumSatsGal m3 : 8|4@1+ (1,0) [0|0] "" Vector__XXX
 SG_ DAS_gpsNavStatusMia m1 : 8|1@1+ (1,0) [0|0] "" Vector__XXX
 SG_ DAS_gpsSoftwareConfigured m1 : 9|1@1+ (1,0) [0|0] "" Vector__XXX
 SG_ DAS_gpsWheeltickCounter m0 : 9|16@1+ (1,0) [0|0] "" Vector__XXX
 SG_ DAS_gnssMaxInstantaneousCnorGal m2 : 10|6@1+ (1,0) [0|0] "" Vector__XXX
 SG_ DAS_gpsSoftwareUsed m1 : 10|1@1+ (1,0) [0|0] "" Vector__XXX
 SG_ DAS_gpsSoftwareFastStartReady m1 : 11|1@1+ (1,0) [0|0] "" Vector__XXX
 SG_ DAS_gnssNumSatsBds m3 : 12|4@1+ (1,0) [0|0] "" Vector__XXX
 SG_ DAS_gpsSatsInUseSoftware m1 : 12|4@1+ (1,0) [0|0] "" Vector__XXX
 SG_ DAS_gnssAvgInstantaneousCnorGps m3 : 16|6@1+ (1,0) [0|0] "" Vector__XXX
 SG_ DAS_gnssMaxInstantaneousCnorBds m2 : 16|6@1+ (1,0) [0|0] "" Vector__XXX
 SG_ DAS_gpsFixTypeSoftware m1 : 16|3@1+ (1,0) [0|0] "" Vector__XXX
 SG_ DAS_gpsCWJammingInidcator m1 : 19|5@1+ (8,0) [0|0] "" Vector__XXX
 SG_ DAS_gnssAvgInstantaneousCnorGal m3 : 22|6@1+ (1,0) [0|0] "" Vector__XXX
 SG_ DAS_gpsResetReason m2 : 22|4@1+ (1,0) [0|0] "" Vector__XXX
 SG_ DAS_gpsJammingState m1 : 24|2@1+ (1,0) [0|0] "" Vector__XXX
 SG_ DAS_gpsWheeltickPulsePeriod m0 : 25|32@1+ (1,0) [0|0] "" Vector__XXX
 SG_ DAS_gpsAccuracyHorizontal m2 : 26|6@1+ (1,0) [0|0] "" Vector__XXX
 SG_ DAS_gpsSpoofDetectorState m1 : 26|2@1+ (1,0) [0|0] "" Vector__XXX
 SG_ DAS_gnssAvgInstantaneousCnorBds m3 : 28|6@1+ (1,0) [0|0] "" Vector__XXX
 SG_ DAS_gpsInvalidMsgPercentage m1 : 28|4@1+ (6,0) [0|0] "" Vector__XXX
 SG_ DAS_gnssConstellationsState m1 : 32|2@1+ (1,0) [0|0] "" Vector__XXX
 SG_ DAS_gpsAccuracyVertical m2 : 32|6@1+ (1,0) [0|0] "" Vector__XXX
 SG_ DAS_gnssAvgInstantCnorGpsSocB m3 : 34|6@1+ (1,0) [0|0] "" Vector__XXX
 SG_ DAS_gpsReceiverNoiseLevel m1 : 34|6@1+ (8,0) [0|0] "" Vector__XXX
 SG_ DAS_gpsSolutionFallback m2 : 38|1@1+ (1,0) [0|0] "" Vector__XXX
 SG_ DAS_gpsToMcuSource m2 : 39|3@1+ (1,0) [0|0] "" Vector__XXX
 SG_ DAS_gnssAvgInstantCnorBdsSocB m3 : 40|6@1+ (1,0) [0|0] "" Vector__XXX
 SG_ DAS_gpsAutomaticGainControl m1 : 40|8@1+ (32,0) [0|0] "" Vector__XXX
 SG_ DAS_gpsSolutionSoc m2 : 42|2@1+ (1,0) [0|0] "" Vector__XXX
 SG_ DAS_gpsRedundancyActive m2 : 44|1@1+ (1,0) [0|0] "" Vector__XXX
 SG_ DAS_gpsFixTypeSoftwareSocB m2 : 45|3@1+ (1,0) [0|0] "" Vector__XXX
 SG_ DAS_gnssAvgInstantaneousCnorGpsLowBand m3 : 46|6@1+ (1,0) [0|0] "" Vector__XXX
 SG_ DAS_gpsPreviousPositionDeltaHw m1 : 48|6@1+ (3,0) [0|0] "" Vector__XXX
 SG_ DAS_gpsSatsInUseSoftwareSocB m2 : 48|4@1+ (1,0) [0|0] "" Vector__XXX
 SG_ DAS_gnssAvgInstantaneousCnorGalLowBand m3 : 52|6@1+ (1,0) [0|0] "" Vector__XXX
 SG_ DAS_gpsPreviousPositionDeltaSw m1 : 54|6@1+ (3,0) [0|0] "" Vector__XXX
 SG_ DAS_gpsRejectingSatData m0 : 57|1@1+ (1,0) [0|0] "" Vector__XXX
 SG_ DAS_gnssAvgInstantaneousCnorBdsLowBand m3 : 58|6@1+ (1,0) [0|0] "" Vector__XXX
 SG_ DAS_gpsWheelsOffMotionDetected m0 : 58|1@1+ (1,0) [0|0] "" Vector__XXX
 SG_ DAS_gpsFixTypeHardware m0 : 59|3@1+ (1,0) [0|0] "" Vector__XXX
 SG_ DAS_gpsNmeaDispatchFailureCount m1 : 60|4@1+ (5,0) [0|0] "" Vector__XXX
 SG_ DAS_gpsRawxEnabled m0 : 62|1@1+ (1,0) [0|0] "" Vector__XXX

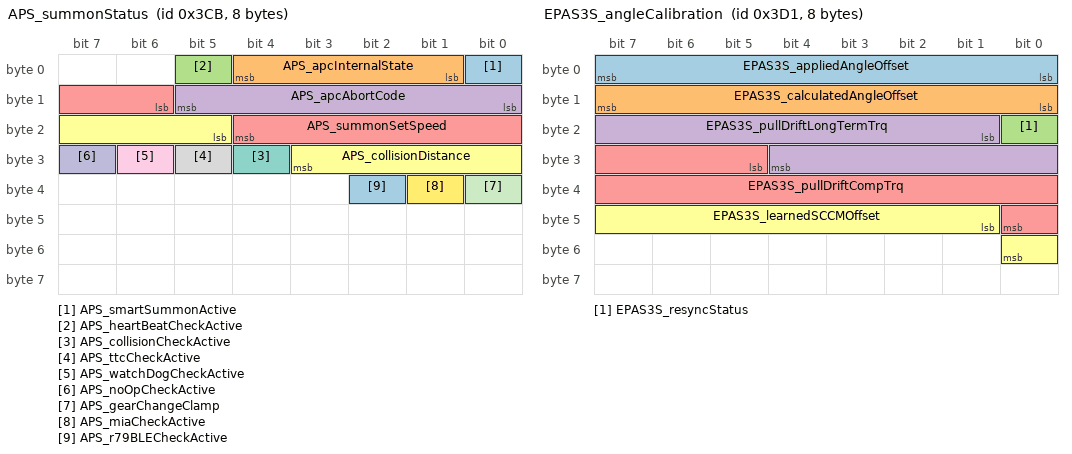
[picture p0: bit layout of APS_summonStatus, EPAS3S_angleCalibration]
BO_ 971 APS_summonStatus: 8 Vector__XXX
 SG_ APS_smartSummonActive : 0|1@1+ (1,0) [0|0] "" Vector__XXX
 SG_ APS_apcInternalState : 1|4@1+ (1,0) [0|0] "" Vector__XXX
 SG_ APS_heartBeatCheckActive : 5|1@1+ (1,0) [0|0] "" Vector__XXX
 SG_ APS_apcAbortCode : 8|6@1+ (1,0) [0|0] "" Vector__XXX
 SG_ APS_summonSetSpeed : 14|7@1+ (0.1,0) [0|0] "" Vector__XXX
 SG_ APS_collisionDistance : 21|7@1+ (0.05,0) [0|0] "" Vector__XXX
 SG_ APS_collisionCheckActive : 28|1@1+ (1,0) [0|0] "" Vector__XXX
 SG_ APS_ttcCheckActive : 29|1@1+ (1,0) [0|0] "" Vector__XXX
 SG_ APS_watchDogCheckActive : 30|1@1+ (1,0) [0|0] "" Vector__XXX
 SG_ APS_noOpCheckActive : 31|1@1+ (1,0) [0|0] "" Vector__XXX
 SG_ APS_gearChangeClamp : 32|1@1+ (1,0) [0|0] "" Vector__XXX
 SG_ APS_miaCheckActive : 33|1@1+ (1,0) [0|0] "" Vector__XXX
 SG_ APS_r79BLECheckActive : 34|1@1+ (1,0) [0|0] "" Vector__XXX

BO_ 977 EPAS3S_angleCalibration: 8 Vector__XXX
 SG_ EPAS3S_appliedAngleOffset : 0|8@1+ (0.1,-12.8) [0|0] "" Vector__XXX
 SG_ EPAS3S_calculatedAngleOffset : 8|8@1+ (0.1,-12.8) [0|0] "" Vector__XXX
 SG_ EPAS3S_resyncStatus : 16|1@1+ (1,0) [0|0] "" Vector__XXX
 SG_ EPAS3S_pullDriftLongTermTrq : 17|12@1+ (0.01,-10) [0|0] "" Vector__XXX
 SG_ EPAS3S_pullDriftCompTrq : 29|12@1+ (0.01,-10) [0|0] "" Vector__XXX
 SG_ EPAS3S_learnedSCCMOffset : 41|8@1+ (0.1,-12.8) [0|0] "" Vector__XXX

BO_ 981 ESP_alertMatrix: 8 Vector__XXX
 SG_ ESP_matrixIndex M : 0|4@1+ (1,0) [0|0] "" Vector__XXX
 SG_ ESP_a001_ecuGenericFault m0 : 4|1@1+ (1,0) [0|0] "" Vector__XXX
 SG_ ESP_a061_ReLWSSSignalNoise m1 : 4|1@1+ (1,0) [0|0] "" Vector__XXX
 SG_ ESP_a121_regenTcActive m2 : 4|1@1+ (1,0) [0|0] "" Vector__XXX
 SG_ ESP_a181_IBSTparty2DLC m3 : 4|1@1+ (1,0) [0|0] "" Vector__XXX
 SG_ ESP_a241_LVPowerStateChecksum m4 : 4|1@1+ (1,0) [0|0] "" Vector__XXX
 SG_ ESP_a301_PEPSstatusCounter m5 : 4|1@1+ (1,0) [0|0] "" Vector__XXX
 SG_ ESP_a002_valvesGenericFault m0 : 5|1@1+ (1,0) [0|0] "" Vector__XXX
 SG_ ESP_a062_ReLWSSVDiffFault m1 : 5|1@1+ (1,0) [0|0] "" Vector__XXX
 SG_ ESP_a122_bdwActive m2 : 5|1@1+ (1,0) [0|0] "" Vector__XXX
 SG_ ESP_a182_IBSTparty2Counter m3 : 5|1@1+ (1,0) [0|0] "" Vector__XXX
 SG_ ESP_a242_LVPowerStateDLC m4 : 5|1@1+ (1,0) [0|0] "" Vector__XXX
 SG_ ESP_a302_rearRoadWheelAngleHealthDegraded m5 : 5|1@1+ (1,0) [0|0] "" Vector__XXX
 SG_ ESP_a003_outletValvesFault m0 : 6|1@1+ (1,0) [0|0] "" Vector__XXX
 SG_ ESP_a063_ReLWSSDirectionFault m1 : 6|1@1+ (1,0) [0|0] "" Vector__XXX
 SG_ ESP_a123_ebrActive m2 : 6|1@1+ (1,0) [0|0] "" Vector__XXX
 SG_ ESP_a183_IBSTStatusOff m3 : 6|1@1+ (1,0) [0|0] "" Vector__XXX
 SG_ ESP_a243_LVPowerStateCounter m4 : 6|1@1+ (1,0) [0|0] "" Vector__XXX
 SG_ ESP_a303_rearRoadWheelAngleHealthFaulted m5 : 6|1@1+ (1,0) [0|0] "" Vector__XXX
 SG_ ESP_a004_inletValvesFault m0 : 7|1@1+ (1,0) [0|0] "" Vector__XXX
 SG_ ESP_a064_ReLWSSLargeAirGap m1 : 7|1@1+ (1,0) [0|0] "" Vector__XXX
 SG_ ESP_a124_ebrSkidActive m2 : 7|1@1+ (1,0) [0|0] "" Vector__XXX
 SG_ ESP_a184_IBSTpRunoutInvalid m3 : 7|1@1+ (1,0) [0|0] "" Vector__XXX
 SG_ ESP_a244_LVOffStateInvalid m4 : 7|1@1+ (1,0) [0|0] "" Vector__XXX
 SG_ ESP_a304_rearVCLVPowerStateTimeout m5 : 7|1@1+ (1,0) [0|0] "" Vector__XXX
 SG_ ESP_a005_HSVValvesFault m0 : 8|1@1+ (1,0) [0|0] "" Vector__XXX
 SG_ ESP_a065_ReLWSSSupplyShortToGnd m1 : 8|1@1+ (1,0) [0|0] "" Vector__XXX
 SG_ ESP_a125_reserved125 m2 : 8|1@1+ (1,0) [0|0] "" Vector__XXX
 SG_ ESP_a185_IBSTFeedforwardBackup m3 : 8|1@1+ (1,0) [0|0] "" Vector__XXX
 SG_ ESP_a245_LVGoingDownStateInvalid m4 : 8|1@1+ (1,0) [0|0] "" Vector__XXX
 SG_ ESP_a305_rearVCLVPowerStateDLC m5 : 8|1@1+ (1,0) [0|0] "" Vector__XXX
 SG_ ESP_a006_USVValvesFault m0 : 9|1@1+ (1,0) [0|0] "" Vector__XXX
 SG_ ESP_a066_ReLWSSGeneralFault m1 : 9|1@1+ (1,0) [0|0] "" Vector__XXX
 SG_ ESP_a126_reserved126 m2 : 9|1@1+ (1,0) [0|0] "" Vector__XXX
 SG_ ESP_a186_IBSTBrakeAppliedInvalid m3 : 9|1@1+ (1,0) [0|0] "" Vector__XXX
 SG_ ESP_a246_VCFRONTsensorTimeout m4 : 9|1@1+ (1,0) [0|0] "" Vector__XXX
 SG_ ESP_a306_rearVCLVPowerStateChecksum m5 : 9|1@1+ (1,0) [0|0] "" Vector__XXX
 SG_ ESP_a007_pumpMotorFault m0 : 10|1@1+ (1,0) [0|0] "" Vector__XXX
 SG_ ESP_a067_ReRWSSOpenOrShortToGnd m1 : 10|1@1+ (1,0) [0|0] "" Vector__XXX
 SG_ ESP_a127_reserved127 m2 : 10|1@1+ (1,0) [0|0] "" Vector__XXX
 SG_ ESP_a187_DIbtcRequestTimeout m3 : 10|1@1+ (1,0) [0|0] "" Vector__XXX
 SG_ ESP_a247_VCFRONTsensorDLC m4 : 10|1@1+ (1,0) [0|0] "" Vector__XXX
 SG_ ESP_a307_rearVCLVPowerStateCounter m5 : 10|1@1+ (1,0) [0|0] "" Vector__XXX
 SG_ ESP_a008_pumpMotor12VsupplyLow m0 : 11|1@1+ (1,0) [0|0] "" Vector__XXX
 SG_ ESP_a068_ReRWSSShortTo12V m1 : 11|1@1+ (1,0) [0|0] "" Vector__XXX
 SG_ ESP_a128_reserved128 m2 : 11|1@1+ (1,0) [0|0] "" Vector__XXX
 SG_ ESP_a188_DIbtcRequestDLC m3 : 11|1@1+ (1,0) [0|0] "" Vector__XXX
 SG_ ESP_a248_vdcBrkeTrqTarFrLInvalid m4 : 11|1@1+ (1,0) [0|0] "" Vector__XXX
 SG_ ESP_a308_evacFillNotComplete m5 : 11|1@1+ (1,0) [0|0] "" Vector__XXX
 SG_ ESP_a009_12VHardUndervoltage m0 : 12|1@1+ (1,0) [0|0] "" Vector__XXX
 SG_ ESP_a069_ReRWSSLineInterruption m1 : 12|1@1+ (1,0) [0|0] "" Vector__XXX
 SG_ ESP_a129_reserved129 m2 : 12|1@1+ (1,0) [0|0] "" Vector__XXX
 SG_ ESP_a189_DIbtcRequestChecksum m3 : 12|1@1+ (1,0) [0|0] "" Vector__XXX
 SG_ ESP_a249_vdcBrkeTrqTarFrRInvalid m4 : 12|1@1+ (1,0) [0|0] "" Vector__XXX
 SG_ ESP_a309_factoryModeActive m5 : 12|1@1+ (1,0) [0|0] "" Vector__XXX
 SG_ ESP_a010_12VUndervoltage m0 : 13|1@1+ (1,0) [0|0] "" Vector__XXX
 SG_ ESP_a070_ReRWSSMaxSpeedExceeded m1 : 13|1@1+ (1,0) [0|0] "" Vector__XXX
 SG_ ESP_a130_EPAS3PsysStatusTimeout m2 : 13|1@1+ (1,0) [0|0] "" Vector__XXX
 SG_ ESP_a190_DIbtcRequestCounter m3 : 13|1@1+ (1,0) [0|0] "" Vector__XXX
 SG_ ESP_a250_vdcBrkeTrqTarReLInvalid m4 : 13|1@1+ (1,0) [0|0] "" Vector__XXX
 SG_ ESP_a310_brakeLatencyReductionActive m5 : 13|1@1+ (1,0) [0|0] "" Vector__XXX
 SG_ ESP_a011_12VSystemUndervoltage m0 : 14|1@1+ (1,0) [0|0] "" Vector__XXX
 SG_ ESP_a071_ReRWSSTooManyPulses m1 : 14|1@1+ (1,0) [0|0] "" Vector__XXX
 SG_ ESP_a131_EPAS3PsysStatusDLC m2 : 14|1@1+ (1,0) [0|0] "" Vector__XXX
 SG_ ESP_a191_DIchassisControlTimeout m3 : 14|1@1+ (1,0) [0|0] "" Vector__XXX
 SG_ ESP_a251_vdcBrkeTrqTarReRInvalid m4 : 14|1@1+ (1,0) [0|0] "" Vector__XXX
 SG_ ESP_a311_aesActive m5 : 14|1@1+ (1,0) [0|0] "" Vector__XXX
 SG_ ESP_a012_netUndervoltage m0 : 15|1@1+ (1,0) [0|0] "" Vector__XXX
 SG_ ESP_a072_ReRWSSLostSignal m1 : 15|1@1+ (1,0) [0|0] "" Vector__XXX
 SG_ ESP_a132_EPAS3PsysStatusChecksum m2 : 15|1@1+ (1,0) [0|0] "" Vector__XXX
 SG_ ESP_a192_DIchassisControlDLC m3 : 15|1@1+ (1,0) [0|0] "" Vector__XXX
 SG_ ESP_a252_vdcWhlSlipLimFrLInvalid m4 : 15|1@1+ (1,0) [0|0] "" Vector__XXX
 SG_ ESP_a312_undefinedAlertDetected m5 : 15|1@1+ (1,0) [0|0] "" Vector__XXX
 SG_ ESP_a013_valveRelayUndervoltage m0 : 16|1@1+ (1,0) [0|0] "" Vector__XXX
 SG_ ESP_a073_ReRWSSNoPulsesDetected m1 : 16|1@1+ (1,0) [0|0] "" Vector__XXX
 SG_ ESP_a133_EPAS3PsysStatusCounter m2 : 16|1@1+ (1,0) [0|0] "" Vector__XXX
 SG_ ESP_a193_DIchassisControlChecksum m3 : 16|1@1+ (1,0) [0|0] "" Vector__XXX
 SG_ ESP_a253_vdcWhlSlipLimFrRInvalid m4 : 16|1@1+ (1,0) [0|0] "" Vector__XXX
 SG_ ESP_a313_cdpRequestStateInvalid m5 : 16|1@1+ (1,0) [0|0] "" Vector__XXX
 SG_ ESP_a014_WSSSupplyUndervoltage m0 : 17|1@1+ (1,0) [0|0] "" Vector__XXX
 SG_ ESP_a074_ReRWSSWrongSensorType m1 : 17|1@1+ (1,0) [0|0] "" Vector__XXX
 SG_ ESP_a134_steeringAngleInvalid m2 : 17|1@1+ (1,0) [0|0] "" Vector__XXX
 SG_ ESP_a194_DIchassisControlCounter m3 : 17|1@1+ (1,0) [0|0] "" Vector__XXX
 SG_ ESP_a254_vdcWhlSlipLimReLInvalid m4 : 17|1@1+ (1,0) [0|0] "" Vector__XXX
 SG_ ESP_a314_aesFault m5 : 17|1@1+ (1,0) [0|0] "" Vector__XXX
 SG_ ESP_a015_12VSupplyOvervoltage m0 : 18|1@1+ (1,0) [0|0] "" Vector__XXX
 SG_ ESP_a075_ReRWSSSignalNoise m1 : 18|1@1+ (1,0) [0|0] "" Vector__XXX
 SG_ ESP_a135_steeringAngleNoCenter m2 : 18|1@1+ (1,0) [0|0] "" Vector__XXX
 SG_ ESP_a195_ptcStateInvalid m3 : 18|1@1+ (1,0) [0|0] "" Vector__XXX
 SG_ ESP_a255_vdcWhlSlipLimReRInvalid m4 : 18|1@1+ (1,0) [0|0] "" Vector__XXX
 SG_ ESP_a315_EMCBackup11Timeout m5 : 18|1@1+ (1,0) [0|0] "" Vector__XXX
 SG_ ESP_a016_12VSystemOvervoltage m0 : 19|1@1+ (1,0) [0|0] "" Vector__XXX
 SG_ ESP_a076_ReRWSSVDiffFault m1 : 19|1@1+ (1,0) [0|0] "" Vector__XXX
 SG_ ESP_a136_steeringAngleFrozen m2 : 19|1@1+ (1,0) [0|0] "" Vector__XXX
 SG_ ESP_a196_DIsystemStatusTimeout m3 : 19|1@1+ (1,0) [0|0] "" Vector__XXX
 SG_ ESP_a256_epbmStatusTimeout m4 : 19|1@1+ (1,0) [0|0] "" Vector__XXX
 SG_ ESP_a316_EMCBackup11DLC m5 : 19|1@1+ (1,0) [0|0] "" Vector__XXX
 SG_ ESP_a017_netOvervoltage m0 : 20|1@1+ (1,0) [0|0] "" Vector__XXX
 SG_ ESP_a077_ReRWSSDirectionFault m1 : 20|1@1+ (1,0) [0|0] "" Vector__XXX
 SG_ ESP_a137_steeringOffsetTooLarge m2 : 20|1@1+ (1,0) [0|0] "" Vector__XXX
 SG_ ESP_a197_DIsystemStatusDLC m3 : 20|1@1+ (1,0) [0|0] "" Vector__XXX
 SG_ ESP_a257_epbmStatusChecksum m4 : 20|1@1+ (1,0) [0|0] "" Vector__XXX
 SG_ ESP_a317_EMCBackup11Checksum m5 : 20|1@1+ (1,0) [0|0] "" Vector__XXX
 SG_ ESP_a018_WSSSignFrontAxle m0 : 21|1@1+ (1,0) [0|0] "" Vector__XXX
 SG_ ESP_a078_ReRWSSLargeAirGap m1 : 21|1@1+ (1,0) [0|0] "" Vector__XXX
 SG_ ESP_a138_steeringAngleImplaus m2 : 21|1@1+ (1,0) [0|0] "" Vector__XXX
 SG_ ESP_a198_DIsystemStatusChecksum m3 : 21|1@1+ (1,0) [0|0] "" Vector__XXX
 SG_ ESP_a258_epbmStatusDLC m4 : 21|1@1+ (1,0) [0|0] "" Vector__XXX
 SG_ ESP_a318_EMCBackup11Counter m5 : 21|1@1+ (1,0) [0|0] "" Vector__XXX
 SG_ ESP_a019_WSSSignRearAxle m0 : 22|1@1+ (1,0) [0|0] "" Vector__XXX
 SG_ ESP_a079_ReRWSSSupplyShortToGnd m1 : 22|1@1+ (1,0) [0|0] "" Vector__XXX
 SG_ ESP_a139_steeringAngleWrongSign m2 : 22|1@1+ (1,0) [0|0] "" Vector__XXX
 SG_ ESP_a199_DIsystemStatusCounter m3 : 22|1@1+ (1,0) [0|0] "" Vector__XXX
 SG_ ESP_a259_epbmStatusCounter m4 : 22|1@1+ (1,0) [0|0] "" Vector__XXX
 SG_ ESP_a319_AES_BackupActuatorActive m5 : 22|1@1+ (1,0) [0|0] "" Vector__XXX
 SG_ ESP_a020_WSSGenericTempFault m0 : 23|1@1+ (1,0) [0|0] "" Vector__XXX
 SG_ ESP_a080_ReRWSSGeneralFault m1 : 23|1@1+ (1,0) [0|0] "" Vector__XXX
 SG_ ESP_a140_RCMInertial1Timeout m2 : 23|1@1+ (1,0) [0|0] "" Vector__XXX
 SG_ ESP_a200_reverseGearStuckHigh m3 : 23|1@1+ (1,0) [0|0] "" Vector__XXX
 SG_ ESP_a260_epblStatusTimeout m4 : 23|1@1+ (1,0) [0|0] "" Vector__XXX
 SG_ ESP_a021_WSSGeneralVDiffFault m0 : 24|1@1+ (1,0) [0|0] "" Vector__XXX
 SG_ ESP_a081_PressureSensorShort m1 : 24|1@1+ (1,0) [0|0] "" Vector__XXX
 SG_ ESP_a141_RCMInertial1DLC m2 : 24|1@1+ (1,0) [0|0] "" Vector__XXX
 SG_ ESP_a201_reverseGearStuckLow m3 : 24|1@1+ (1,0) [0|0] "" Vector__XXX
 SG_ ESP_a261_epblStatusChecksum m4 : 24|1@1+ (1,0) [0|0] "" Vector__XXX
 SG_ ESP_a022_WSSDirectionFault m0 : 25|1@1+ (1,0) [0|0] "" Vector__XXX
 SG_ ESP_a082_PMCSensorOffsetHigh m1 : 25|1@1+ (1,0) [0|0] "" Vector__XXX
 SG_ ESP_a142_RCMInertial1Checksum m2 : 25|1@1+ (1,0) [0|0] "" Vector__XXX
 SG_ ESP_a202_accelPedalInvalid m3 : 25|1@1+ (1,0) [0|0] "" Vector__XXX
 SG_ ESP_a262_epblStatusDLC m4 : 25|1@1+ (1,0) [0|0] "" Vector__XXX
 SG_ ESP_a023_WSSSeveralSuspected m0 : 26|1@1+ (1,0) [0|0] "" Vector__XXX
 SG_ ESP_a083_PMCSensorFault m1 : 26|1@1+ (1,0) [0|0] "" Vector__XXX
 SG_ ESP_a143_RCMInertial1Counter m2 : 26|1@1+ (1,0) [0|0] "" Vector__XXX
 SG_ ESP_a203_DItorqueTimeout m3 : 26|1@1+ (1,0) [0|0] "" Vector__XXX
 SG_ ESP_a263_epblStatusCounter m4 : 26|1@1+ (1,0) [0|0] "" Vector__XXX
 SG_ ESP_a024_WSSReverseCurrent m0 : 27|1@1+ (1,0) [0|0] "" Vector__XXX
 SG_ ESP_a084_BrakeFluidReservoirLow m1 : 27|1@1+ (1,0) [0|0] "" Vector__XXX
 SG_ ESP_a144_yawMaxLatency m2 : 27|1@1+ (1,0) [0|0] "" Vector__XXX
 SG_ ESP_a204_DItorqueDLC m3 : 27|1@1+ (1,0) [0|0] "" Vector__XXX
 SG_ ESP_a264_pumpSpeedLimitInvalid m4 : 27|1@1+ (1,0) [0|0] "" Vector__XXX
 SG_ ESP_a025_FrLWSSOpenOrShortToGnd m0 : 28|1@1+ (1,0) [0|0] "" Vector__XXX
 SG_ ESP_a085_BrakeSwitchStuckHigh m1 : 28|1@1+ (1,0) [0|0] "" Vector__XXX
 SG_ ESP_a145_yawInitFault m2 : 28|1@1+ (1,0) [0|0] "" Vector__XXX
 SG_ ESP_a205_DItorqueChecksum m3 : 28|1@1+ (1,0) [0|0] "" Vector__XXX
 SG_ ESP_a265_DIRELtorqueTimeout m4 : 28|1@1+ (1,0) [0|0] "" Vector__XXX
 SG_ ESP_a026_FrLWSSShortTo12V m0 : 29|1@1+ (1,0) [0|0] "" Vector__XXX
 SG_ ESP_a086_BrakeSwitchImplausible1 m1 : 29|1@1+ (1,0) [0|0] "" Vector__XXX
 SG_ ESP_a146_yawInvalidValue m2 : 29|1@1+ (1,0) [0|0] "" Vector__XXX
 SG_ ESP_a206_DItorqueCounter m3 : 29|1@1+ (1,0) [0|0] "" Vector__XXX
 SG_ ESP_a266_DIRELtorqueDLC m4 : 29|1@1+ (1,0) [0|0] "" Vector__XXX
 SG_ ESP_a027_FrLWSSLineInterruption m0 : 30|1@1+ (1,0) [0|0] "" Vector__XXX
 SG_ ESP_a087_BrakeSwitchImplausible3 m1 : 30|1@1+ (1,0) [0|0] "" Vector__XXX
 SG_ ESP_a147_yawSensorNotAvailable m2 : 30|1@1+ (1,0) [0|0] "" Vector__XXX
 SG_ ESP_a207_DITorqueCommandInvalid m3 : 30|1@1+ (1,0) [0|0] "" Vector__XXX
 SG_ ESP_a267_DIRELtorqueChecksum m4 : 30|1@1+ (1,0) [0|0] "" Vector__XXX
 SG_ ESP_a028_FrLWSSMaxSpeedExceeded m0 : 31|1@1+ (1,0) [0|0] "" Vector__XXX
 SG_ ESP_a088_absContinuousControl m1 : 31|1@1+ (1,0) [0|0] "" Vector__XXX
 SG_ ESP_a148_yawSignalFault m2 : 31|1@1+ (1,0) [0|0] "" Vector__XXX
 SG_ ESP_a208_DIRPMInvalid m3 : 31|1@1+ (1,0) [0|0] "" Vector__XXX
 SG_ ESP_a268_DIRELtorqueCounter m4 : 31|1@1+ (1,0) [0|0] "" Vector__XXX
 SG_ ESP_a029_FrLWSSTooManyPulses m0 : 32|1@1+ (1,0) [0|0] "" Vector__XXX
 SG_ ESP_a089_absNoPressureIncrease m1 : 32|1@1+ (1,0) [0|0] "" Vector__XXX
 SG_ ESP_a149_yawInvalidSign m2 : 32|1@1+ (1,0) [0|0] "" Vector__XXX
 SG_ ESP_a209_DITorqueActualInvalid m3 : 32|1@1+ (1,0) [0|0] "" Vector__XXX
 SG_ ESP_a269_DIRELTorqueCommandInvalid m4 : 32|1@1+ (1,0) [0|0] "" Vector__XXX
 SG_ ESP_a030_FrLWSSLostSignal m0 : 33|1@1+ (1,0) [0|0] "" Vector__XXX
 SG_ ESP_a090_vdcContinuousControl m1 : 33|1@1+ (1,0) [0|0] "" Vector__XXX
 SG_ ESP_a150_yawImplausible m2 : 33|1@1+ (1,0) [0|0] "" Vector__XXX
 SG_ ESP_a210_DIStorqueTimeout m3 : 33|1@1+ (1,0) [0|0] "" Vector__XXX
 SG_ ESP_a270_DIRELRPMInvalid m4 : 33|1@1+ (1,0) [0|0] "" Vector__XXX
 SG_ ESP_a031_FrLWSSNoPulsesDetected m0 : 34|1@1+ (1,0) [0|0] "" Vector__XXX
 SG_ ESP_a091_CANUndervoltage m1 : 34|1@1+ (1,0) [0|0] "" Vector__XXX
 SG_ ESP_a151_RCMInertial2Timeout m2 : 34|1@1+ (1,0) [0|0] "" Vector__XXX
 SG_ ESP_a211_DIStorqueDLC m3 : 34|1@1+ (1,0) [0|0] "" Vector__XXX
 SG_ ESP_a271_DIRELTorqueActualInvalid m4 : 34|1@1+ (1,0) [0|0] "" Vector__XXX
 SG_ ESP_a032_FrLWSSWrongSensorType m0 : 35|1@1+ (1,0) [0|0] "" Vector__XXX
 SG_ ESP_a092_CANOvervoltage m1 : 35|1@1+ (1,0) [0|0] "" Vector__XXX
 SG_ ESP_a152_RCMInertial2DLC m2 : 35|1@1+ (1,0) [0|0] "" Vector__XXX
 SG_ ESP_a212_DIStorqueChecksum m3 : 35|1@1+ (1,0) [0|0] "" Vector__XXX
 SG_ ESP_a272_DIRERtorqueTimeout m4 : 35|1@1+ (1,0) [0|0] "" Vector__XXX
 SG_ ESP_a033_FrLWSSSignalNoise m0 : 36|1@1+ (1,0) [0|0] "" Vector__XXX
 SG_ ESP_a093_partyBusOff m1 : 36|1@1+ (1,0) [0|0] "" Vector__XXX
 SG_ ESP_a153_RCMInertial2Checksum m2 : 36|1@1+ (1,0) [0|0] "" Vector__XXX
 SG_ ESP_a213_DIStorqueCounter m3 : 36|1@1+ (1,0) [0|0] "" Vector__XXX
 SG_ ESP_a273_DIRERtorqueDLC m4 : 36|1@1+ (1,0) [0|0] "" Vector__XXX
 SG_ ESP_a034_FrLWSSVDiffFault m0 : 37|1@1+ (1,0) [0|0] "" Vector__XXX
 SG_ ESP_a094_partyBusPassive m1 : 37|1@1+ (1,0) [0|0] "" Vector__XXX
 SG_ ESP_a154_RCMInertial2Counter m2 : 37|1@1+ (1,0) [0|0] "" Vector__XXX
 SG_ ESP_a214_DISTorqueCommandInvalid m3 : 37|1@1+ (1,0) [0|0] "" Vector__XXX
 SG_ ESP_a274_DIRERtorqueChecksum m4 : 37|1@1+ (1,0) [0|0] "" Vector__XXX
 SG_ ESP_a035_FrLWSSDirectionFault m0 : 38|1@1+ (1,0) [0|0] "" Vector__XXX
 SG_ ESP_a095_chassisBusOff m1 : 38|1@1+ (1,0) [0|0] "" Vector__XXX
 SG_ ESP_a155_ayMaxLatency m2 : 38|1@1+ (1,0) [0|0] "" Vector__XXX
 SG_ ESP_a215_DISRPMInvalid m3 : 38|1@1+ (1,0) [0|0] "" Vector__XXX
 SG_ ESP_a275_DIRERtorqueCounter m4 : 38|1@1+ (1,0) [0|0] "" Vector__XXX
 SG_ ESP_a036_FrLWSSLargeAirGap m0 : 39|1@1+ (1,0) [0|0] "" Vector__XXX
 SG_ ESP_a096_chassisBusPassive m1 : 39|1@1+ (1,0) [0|0] "" Vector__XXX
 SG_ ESP_a156_ayInitFault m2 : 39|1@1+ (1,0) [0|0] "" Vector__XXX
 SG_ ESP_a216_DISTorqueActualInvalid m3 : 39|1@1+ (1,0) [0|0] "" Vector__XXX
 SG_ ESP_a276_DIRERTorqueCommandInvalid m4 : 39|1@1+ (1,0) [0|0] "" Vector__XXX
 SG_ ESP_a037_FrLWSSSupplyShortToGnd m0 : 40|1@1+ (1,0) [0|0] "" Vector__XXX
 SG_ ESP_a097_tcsRefSpeedNotInit m1 : 40|1@1+ (1,0) [0|0] "" Vector__XXX
 SG_ ESP_a157_ayInvalidValue m2 : 40|1@1+ (1,0) [0|0] "" Vector__XXX
 SG_ ESP_a217_DIvdcLeftTimeout m3 : 40|1@1+ (1,0) [0|0] "" Vector__XXX
 SG_ ESP_a277_DIRERRPMInvalid m4 : 40|1@1+ (1,0) [0|0] "" Vector__XXX
 SG_ ESP_a038_FrLWSSGeneralFault m0 : 41|1@1+ (1,0) [0|0] "" Vector__XXX
 SG_ ESP_a098_vdcRefSpeedNotInit m1 : 41|1@1+ (1,0) [0|0] "" Vector__XXX
 SG_ ESP_a158_aySensorNotAvailable m2 : 41|1@1+ (1,0) [0|0] "" Vector__XXX
 SG_ ESP_a218_DIvdcLeftDLC m3 : 41|1@1+ (1,0) [0|0] "" Vector__XXX
 SG_ ESP_a278_DIRERTorqueActualInvalid m4 : 41|1@1+ (1,0) [0|0] "" Vector__XXX
 SG_ ESP_a039_FrRWSSOpenOrShortToGnd m0 : 42|1@1+ (1,0) [0|0] "" Vector__XXX
 SG_ ESP_a099_brakeTempModelOverheat m1 : 42|1@1+ (1,0) [0|0] "" Vector__XXX
 SG_ ESP_a159_aySignalFault m2 : 42|1@1+ (1,0) [0|0] "" Vector__XXX
 SG_ ESP_a219_DIvdcLeftChecksum m3 : 42|1@1+ (1,0) [0|0] "" Vector__XXX
 SG_ ESP_a279_lifetimeManagementOverrun m4 : 42|1@1+ (1,0) [0|0] "" Vector__XXX
 SG_ ESP_a040_FrRWSSShortTo12V m0 : 43|1@1+ (1,0) [0|0] "" Vector__XXX
 SG_ ESP_a100_brakeTempModelDisabled m1 : 43|1@1+ (1,0) [0|0] "" Vector__XXX
 SG_ ESP_a160_ayRangeExceeded m2 : 43|1@1+ (1,0) [0|0] "" Vector__XXX
 SG_ ESP_a220_DIvdcLeftCounter m3 : 43|1@1+ (1,0) [0|0] "" Vector__XXX
 SG_ ESP_a280_trackModeABSEnabled m4 : 43|1@1+ (1,0) [0|0] "" Vector__XXX
 SG_ ESP_a041_FrRWSSLineInterruption m0 : 44|1@1+ (1,0) [0|0] "" Vector__XXX
 SG_ ESP_a101_ebdFault m1 : 44|1@1+ (1,0) [0|0] "" Vector__XXX
 SG_ ESP_a161_ayOffsetExceeded m2 : 44|1@1+ (1,0) [0|0] "" Vector__XXX
 SG_ ESP_a221_DIvdcRightTimeout m3 : 44|1@1+ (1,0) [0|0] "" Vector__XXX
 SG_ ESP_a281_trackModeABSdisabled m4 : 44|1@1+ (1,0) [0|0] "" Vector__XXX
 SG_ ESP_a042_FrRWSSMaxSpeedExceeded m0 : 45|1@1+ (1,0) [0|0] "" Vector__XXX
 SG_ ESP_a102_absFault m1 : 45|1@1+ (1,0) [0|0] "" Vector__XXX
 SG_ ESP_a162_ayImplausible m2 : 45|1@1+ (1,0) [0|0] "" Vector__XXX
 SG_ ESP_a222_DIvdcRightDLC m3 : 45|1@1+ (1,0) [0|0] "" Vector__XXX
 SG_ ESP_a282_trackModeABSRequestInvalid m4 : 45|1@1+ (1,0) [0|0] "" Vector__XXX
 SG_ ESP_a043_FrRWSSTooManyPulses m0 : 46|1@1+ (1,0) [0|0] "" Vector__XXX
 SG_ ESP_a103_stabilityControlFault m1 : 46|1@1+ (1,0) [0|0] "" Vector__XXX
 SG_ ESP_a163_axMaxLatency m2 : 46|1@1+ (1,0) [0|0] "" Vector__XXX
 SG_ ESP_a223_DIvdcRightChecksum m3 : 46|1@1+ (1,0) [0|0] "" Vector__XXX
 SG_ ESP_a283_secondaryCollisionMitigationActive m4 : 46|1@1+ (1,0) [0|0] "" Vector__XXX
 SG_ ESP_a044_FrRWSSLostSignal m0 : 47|1@1+ (1,0) [0|0] "" Vector__XXX
 SG_ ESP_a104_hbcEnabled m1 : 47|1@1+ (1,0) [0|0] "" Vector__XXX
 SG_ ESP_a164_axInitFault m2 : 47|1@1+ (1,0) [0|0] "" Vector__XXX
 SG_ ESP_a224_DIvdcRightCounter m3 : 47|1@1+ (1,0) [0|0] "" Vector__XXX
 SG_ ESP_a284_scmRequestInvalidChecksum m4 : 47|1@1+ (1,0) [0|0] "" Vector__XXX
 SG_ ESP_a045_FrRWSSNoPulsesDetected m0 : 48|1@1+ (1,0) [0|0] "" Vector__XXX
 SG_ ESP_a105_ebrFault m1 : 48|1@1+ (1,0) [0|0] "" Vector__XXX
 SG_ ESP_a165_axInvalidValue m2 : 48|1@1+ (1,0) [0|0] "" Vector__XXX
 SG_ ESP_a225_configMismatch m3 : 48|1@1+ (1,0) [0|0] "" Vector__XXX
 SG_ ESP_a285_scmRequestDLC m4 : 48|1@1+ (1,0) [0|0] "" Vector__XXX
 SG_ ESP_a046_FrRWSSWrongSensorType m0 : 49|1@1+ (1,0) [0|0] "" Vector__XXX
 SG_ ESP_a106_vdcActuatorFault m1 : 49|1@1+ (1,0) [0|0] "" Vector__XXX
 SG_ ESP_a166_axSensorNotAvailable m2 : 49|1@1+ (1,0) [0|0] "" Vector__XXX
 SG_ ESP_a226_bdwRequestInvalid m3 : 49|1@1+ (1,0) [0|0] "" Vector__XXX
 SG_ ESP_a286_hydroplaneDetected m4 : 49|1@1+ (1,0) [0|0] "" Vector__XXX
 SG_ ESP_a047_FrRWSSSignalNoise m0 : 50|1@1+ (1,0) [0|0] "" Vector__XXX
 SG_ ESP_a107_reserved107 m1 : 50|1@1+ (1,0) [0|0] "" Vector__XXX
 SG_ ESP_a167_axSignalFault m2 : 50|1@1+ (1,0) [0|0] "" Vector__XXX
 SG_ ESP_a227_bdwRequestActiveInvalid m3 : 50|1@1+ (1,0) [0|0] "" Vector__XXX
 SG_ ESP_a287_failedBrakeCircuitDetected m4 : 50|1@1+ (1,0) [0|0] "" Vector__XXX
 SG_ ESP_a048_FrRWSSVDiffFault m0 : 51|1@1+ (1,0) [0|0] "" Vector__XXX
 SG_ ESP_a108_reserved108 m1 : 51|1@1+ (1,0) [0|0] "" Vector__XXX
 SG_ ESP_a168_axRangeExceeded m2 : 51|1@1+ (1,0) [0|0] "" Vector__XXX
 SG_ ESP_a228_GTWvinTimeout m3 : 51|1@1+ (1,0) [0|0] "" Vector__XXX
 SG_ ESP_a288_leftBusOff m4 : 51|1@1+ (1,0) [0|0] "" Vector__XXX
 SG_ ESP_a049_FrRWSSDirectionFault m0 : 52|1@1+ (1,0) [0|0] "" Vector__XXX
 SG_ ESP_a109_reserved109 m1 : 52|1@1+ (1,0) [0|0] "" Vector__XXX
 SG_ ESP_a169_axOffsetExceeded m2 : 52|1@1+ (1,0) [0|0] "" Vector__XXX
 SG_ ESP_a229_GTWvinDLC m3 : 52|1@1+ (1,0) [0|0] "" Vector__XXX
 SG_ ESP_a289_leftBusPassive m4 : 52|1@1+ (1,0) [0|0] "" Vector__XXX
 SG_ ESP_a050_FrRWSSLargeAirGap m0 : 53|1@1+ (1,0) [0|0] "" Vector__XXX
 SG_ ESP_a110_rollerBenchActive m1 : 53|1@1+ (1,0) [0|0] "" Vector__XXX
 SG_ ESP_a170_axSignalFrozen m2 : 53|1@1+ (1,0) [0|0] "" Vector__XXX
 SG_ ESP_a230_vinNotLearned m3 : 53|1@1+ (1,0) [0|0] "" Vector__XXX
 SG_ ESP_a290_brakeBusOff m4 : 53|1@1+ (1,0) [0|0] "" Vector__XXX
 SG_ ESP_a051_FrRWSSSupplyShortToGnd m0 : 54|1@1+ (1,0) [0|0] "" Vector__XXX
 SG_ ESP_a111_absActive m1 : 54|1@1+ (1,0) [0|0] "" Vector__XXX
 SG_ ESP_a171_axImplausible m2 : 54|1@1+ (1,0) [0|0] "" Vector__XXX
 SG_ ESP_a231_storedVINMismatch m3 : 54|1@1+ (1,0) [0|0] "" Vector__XXX
 SG_ ESP_a291_brakeBusPassive m4 : 54|1@1+ (1,0) [0|0] "" Vector__XXX
 SG_ ESP_a052_FrRWSSGeneralFault m0 : 55|1@1+ (1,0) [0|0] "" Vector__XXX
 SG_ ESP_a112_espActive m1 : 55|1@1+ (1,0) [0|0] "" Vector__XXX
 SG_ ESP_a172_IBSTparty1Timeout m2 : 55|1@1+ (1,0) [0|0] "" Vector__XXX
 SG_ ESP_a232_PMstate2Timeout m3 : 55|1@1+ (1,0) [0|0] "" Vector__XXX
 SG_ ESP_a292_PEPSstatusTimeout m4 : 55|1@1+ (1,0) [0|0] "" Vector__XXX
 SG_ ESP_a053_ReLWSSOpenOrShortToGnd m0 : 56|1@1+ (1,0) [0|0] "" Vector__XXX
 SG_ ESP_a113_btcActive m1 : 56|1@1+ (1,0) [0|0] "" Vector__XXX
 SG_ ESP_a173_IBSTparty1DLC m2 : 56|1@1+ (1,0) [0|0] "" Vector__XXX
 SG_ ESP_a233_PMstate2Checksum m3 : 56|1@1+ (1,0) [0|0] "" Vector__XXX
 SG_ ESP_a293_PEPSstatusDLC m4 : 56|1@1+ (1,0) [0|0] "" Vector__XXX
 SG_ ESP_a054_ReLWSSShortTo12V m0 : 57|1@1+ (1,0) [0|0] "" Vector__XXX
 SG_ ESP_a114_tvdcActive m1 : 57|1@1+ (1,0) [0|0] "" Vector__XXX
 SG_ ESP_a174_IBSTparty1Checksum m2 : 57|1@1+ (1,0) [0|0] "" Vector__XXX
 SG_ ESP_a234_PMstate2DLC m3 : 57|1@1+ (1,0) [0|0] "" Vector__XXX
 SG_ ESP_a294_PEPSstatusChecksum m4 : 57|1@1+ (1,0) [0|0] "" Vector__XXX
 SG_ ESP_a055_ReLWSSLineInterruption m0 : 58|1@1+ (1,0) [0|0] "" Vector__XXX
 SG_ ESP_a115_ebdActive m1 : 58|1@1+ (1,0) [0|0] "" Vector__XXX
 SG_ ESP_a175_IBSTparty1Counter m2 : 58|1@1+ (1,0) [0|0] "" Vector__XXX
 SG_ ESP_a235_PMstate2Counter m3 : 58|1@1+ (1,0) [0|0] "" Vector__XXX
 SG_ ESP_a295_PEPSstatusCounter m4 : 58|1@1+ (1,0) [0|0] "" Vector__XXX
 SG_ ESP_a056_ReLWSSMaxSpeedExceeded m0 : 59|1@1+ (1,0) [0|0] "" Vector__XXX
 SG_ ESP_a116_tsmActive m1 : 59|1@1+ (1,0) [0|0] "" Vector__XXX
 SG_ ESP_a176_IBSTEBRNotAvailable m2 : 59|1@1+ (1,0) [0|0] "" Vector__XXX
 SG_ ESP_a236_ebrCommandStateInvalid m3 : 59|1@1+ (1,0) [0|0] "" Vector__XXX
 SG_ ESP_a296_roadWheelAngleHealthDegraded m4 : 59|1@1+ (1,0) [0|0] "" Vector__XXX
 SG_ ESP_a057_ReLWSSTooManyPulses m0 : 60|1@1+ (1,0) [0|0] "" Vector__XXX
 SG_ ESP_a117_hbaActive m1 : 60|1@1+ (1,0) [0|0] "" Vector__XXX
 SG_ ESP_a177_IBSTOutputRodDrvInvalid m2 : 60|1@1+ (1,0) [0|0] "" Vector__XXX
 SG_ ESP_a237_vdcCommandStateInvalid m3 : 60|1@1+ (1,0) [0|0] "" Vector__XXX
 SG_ ESP_a297_roadWheelAngleHealthFaulted m4 : 60|1@1+ (1,0) [0|0] "" Vector__XXX
 SG_ ESP_a058_ReLWSSLostSignal m0 : 61|1@1+ (1,0) [0|0] "" Vector__XXX
 SG_ ESP_a118_hfcActive m1 : 61|1@1+ (1,0) [0|0] "" Vector__XXX
 SG_ ESP_a178_IBSTOutputRodActInvalid m2 : 61|1@1+ (1,0) [0|0] "" Vector__XXX
 SG_ ESP_a238_UIodoTimeout m3 : 61|1@1+ (1,0) [0|0] "" Vector__XXX
 SG_ ESP_a298_RSArearSteerStatusTimeout m4 : 61|1@1+ (1,0) [0|0] "" Vector__XXX
 SG_ ESP_a059_ReLWSSNoPulsesDetected m0 : 62|1@1+ (1,0) [0|0] "" Vector__XXX
 SG_ ESP_a119_hbbActive m1 : 62|1@1+ (1,0) [0|0] "" Vector__XXX
 SG_ ESP_a179_IBSTparty2Timeout m2 : 62|1@1+ (1,0) [0|0] "" Vector__XXX
 SG_ ESP_a239_UIodoDLC m3 : 62|1@1+ (1,0) [0|0] "" Vector__XXX
 SG_ ESP_a299_RSArearSteerStatusDLC m4 : 62|1@1+ (1,0) [0|0] "" Vector__XXX
 SG_ ESP_a060_ReLWSSWrongSensorType m0 : 63|1@1+ (1,0) [0|0] "" Vector__XXX
 SG_ ESP_a120_rmiActive m1 : 63|1@1+ (1,0) [0|0] "" Vector__XXX
 SG_ ESP_a180_IBSTparty2Checksum m2 : 63|1@1+ (1,0) [0|0] "" Vector__XXX
 SG_ ESP_a240_LVPowerStateTimeout m3 : 63|1@1+ (1,0) [0|0] "" Vector__XXX
 SG_ ESP_a300_RSArearSteerStatusChecksum m4 : 63|1@1+ (1,0) [0|0] "" Vector__XXX

BO_ 985 UI_locationOffset: 8 Vector__XXX
 SG_ UI_latitudeOffset : 0|28@1- (1e-06,0) [0|0] "" Vector__XXX
 SG_ UI_longitudeOffset : 28|29@1- (1e-06,0) [0|0] "" Vector__XXX

BO_ 986 DAS_telemetryEvent: 8 Vector__XXX
 SG_ DAS_TE_multiplexer M : 0|5@1+ (1,0) [0|0] "" Vector__XXX
 SG_ DAS_TE_accCounter m6 : 5|3@1+ (1,0) [0|0] "" Vector__XXX
 SG_ DAS_TE_counter m0 : 5|3@1+ (1,0) [0|0] "" Vector__XXX
 SG_ DAS_TE_fcmCounter m7 : 5|3@1+ (1,0) [0|0] "" Vector__XXX
 SG_ DAS_TE_hppCounter m3 : 5|3@1+ (1,0) [0|0] "" Vector__XXX
 SG_ DAS_TE_ipsoCounter m8 : 5|3@1+ (1,0) [0|0] "" Vector__XXX
 SG_ DAS_TE_llCounter m1 : 5|3@1+ (1,0) [0|0] "" Vector__XXX
 SG_ DAS_TE_navCounter m4 : 5|3@1+ (1,0) [0|0] "" Vector__XXX
 SG_ DAS_TE_rlCounter m2 : 5|3@1+ (1,0) [0|0] "" Vector__XXX
 SG_ DAS_TE_robCounter m9 : 5|3@1+ (1,0) [0|0] "" Vector__XXX
 SG_ DAS_TE_vlCounter m5 : 5|3@1+ (1,0) [0|0] "" Vector__XXX
 SG_ DAS_TE_accTargetDx m6 : 8|6@1+ (2,0) [0|0] "" Vector__XXX
 SG_ DAS_TE_eventID m0 : 8|16@1+ (1,0) [0|0] "" Vector__XXX
 SG_ DAS_TE_fcmTargetDx m7 : 8|8@1+ (0.25,0) [0|0] "" Vector__XXX
 SG_ DAS_TE_hppC0 m3 : 8|10@1- (0.02,0) [0|0] "" Vector__XXX
 SG_ DAS_TE_ipsoValid m8 : 8|1@1+ (1,0) [0|0] "" Vector__XXX
 SG_ DAS_TE_llC0 m1 : 8|10@1- (0.02,0) [0|0] "" Vector__XXX
 SG_ DAS_TE_navC0 m4 : 8|10@1- (0.02,0) [0|0] "" Vector__XXX
 SG_ DAS_TE_rlC0 m2 : 8|10@1- (0.02,0) [0|0] "" Vector__XXX
 SG_ DAS_TE_vlC0 m5 : 8|10@1- (0.02,0) [0|0] "" Vector__XXX
 SG_ DAS_TE_ipsoConfidence m8 : 9|7@1+ (1,0) [0|0] "" Vector__XXX
 SG_ DAS_TE_accTargetDy m6 : 14|6@1+ (0.2,-6.4) [0|0] "" Vector__XXX
 SG_ DAS_TE_fcmTargetDy m7 : 16|5@1+ (0.2,-3.2) [0|0] "" Vector__XXX
 SG_ DAS_TE_ipsoDx m8 : 16|6@1+ (2,0) [0|0] "" Vector__XXX
 SG_ DAS_TE_robExceptionStart m9 : 16|8@1+ (1,-95) [0|0] "" Vector__XXX
 SG_ DAS_TE_hppC1 m3 : 18|9@1- (0.001953125,0) [0|0] "" Vector__XXX
 SG_ DAS_TE_llC1 m1 : 18|9@1- (0.001953125,0) [0|0] "" Vector__XXX
 SG_ DAS_TE_navC1 m4 : 18|9@1- (0.001953125,0) [0|0] "" Vector__XXX
 SG_ DAS_TE_rlC1 m2 : 18|9@1- (0.001953125,0) [0|0] "" Vector__XXX
 SG_ DAS_TE_vlC1 m5 : 18|9@1- (0.001953125,0) [0|0] "" Vector__XXX
 SG_ DAS_TE_accTargetRelVel m6 : 20|7@1- (0.25,-15.75) [0|0] "" Vector__XXX
 SG_ DAS_TE_fcmTargetVRel m7 : 21|7@1+ (0.25,-31.75) [0|0] "" Vector__XXX
 SG_ DAS_TE_ipsoDy m8 : 22|6@1+ (0.1,-3.2) [0|0] "" Vector__XXX
 SG_ DAS_TE_eventType m0 : 24|6@1+ (1,0) [0|0] "" Vector__XXX
 SG_ DAS_TE_robExceptionEnd m9 : 24|8@1+ (1,0) [0|0] "" Vector__XXX
 SG_ DAS_TE_accTargetRelA m6 : 27|5@1- (0.5,-7.5) [0|0] "" Vector__XXX
 SG_ DAS_TE_hppC2 m3 : 27|14@1- (4e-06,0) [0|0] "" Vector__XXX
 SG_ DAS_TE_llC2 m1 : 27|14@1- (4e-06,0) [0|0] "" Vector__XXX
 SG_ DAS_TE_navC2 m4 : 27|14@1- (4e-06,0) [0|0] "" Vector__XXX
 SG_ DAS_TE_rlC2 m2 : 27|14@1- (4e-06,0) [0|0] "" Vector__XXX
 SG_ DAS_TE_vlC2 m5 : 27|14@1- (4e-06,0) [0|0] "" Vector__XXX
 SG_ DAS_TE_fcmTargetAccel m7 : 28|5@1+ (0.5,-15.5) [0|0] "" Vector__XXX
 SG_ DAS_TE_vlDyAtIpsoDx m8 : 28|6@1+ (0.1,-3.2) [0|0] "" Vector__XXX
 SG_ DAS_TE_accMinAccel m6 : 32|5@1- (0.5,-7.5) [0|0] "" Vector__XXX
 SG_ DAS_TE_lcAbortReason m0 : 32|5@1+ (1,0) [0|0] "" Vector__XXX
 SG_ DAS_TE_robDistanceEllipse m9 : 32|8@1+ (0.5,0) [0|0] "" Vector__XXX
 SG_ DAS_TE_fcmTargetProb m7 : 33|5@1+ (5,0) [0|0] "" Vector__XXX
 SG_ DAS_TE_swaProjection m8 : 34|6@1+ (0.1,-3.2) [0|0] "" Vector__XXX
 SG_ DAS_TE_accMinJ m6 : 37|5@1- (0.5,-7.5) [0|0] "" Vector__XXX
 SG_ DAS_TE_fcmDecelReqInstant m7 : 38|7@1- (0.1,-6.3) [0|0] "" Vector__XXX
 SG_ DAS_TE_ipsoIsTarget1 m8 : 40|1@1+ (1,0) [0|0] "" Vector__XXX
 SG_ DAS_TE_robEllipseOverlap m9 : 40|8@1+ (0.1,-12.5) [0|0] "" Vector__XXX
 SG_ DAS_TE_hppC3 m3 : 41|14@1- (1.6e-08,0) [0|0] "" Vector__XXX
 SG_ DAS_TE_ipsoIsTarget5 m8 : 41|1@1+ (1,0) [0|0] "" Vector__XXX
 SG_ DAS_TE_llC3 m1 : 41|14@1- (1.6e-08,0) [0|0] "" Vector__XXX
 SG_ DAS_TE_navC3 m4 : 41|14@1- (1.6e-08,0) [0|0] "" Vector__XXX
 SG_ DAS_TE_rlC3 m2 : 41|14@1- (1.6e-08,0) [0|0] "" Vector__XXX
 SG_ DAS_TE_vlC3 m5 : 41|14@1- (1.6e-08,0) [0|0] "" Vector__XXX
 SG_ DAS_TE_restrictedAccess m8 : 42|1@1+ (1,0) [0|0] "" Vector__XXX
 SG_ DAS_TE_csaOfframpValid m8 : 43|1@1+ (1,0) [0|0] "" Vector__XXX
 SG_ DAS_TE_accControlType m8 : 44|4@1+ (1,0) [0|0] "" Vector__XXX
 SG_ DAS_TE_fcmDecelReqAeb m7 : 45|7@1- (0.1,-6.3) [0|0] "" Vector__XXX
 SG_ DAS_TE_brakeCapacityWarning m8 : 48|1@1+ (1,0) [0|0] "" Vector__XXX
 SG_ DAS_TE_robEllipseAge m9 : 48|3@1+ (1,0) [0|0] "" Vector__XXX
 SG_ DAS_TE_emergencyBrake m8 : 49|1@1+ (1,0) [0|0] "" Vector__XXX
 SG_ DAS_TE_extendedAccLimits m8 : 50|1@1+ (1,0) [0|0] "" Vector__XXX
 SG_ DAS_TE_crashFront m8 : 51|1@1+ (1,0) [0|0] "" Vector__XXX
 SG_ DAS_TE_robInfrastructure m9 : 51|1@1+ (1,0) [0|0] "" Vector__XXX
 SG_ DAS_TE_crashLeft m8 : 52|1@1+ (1,0) [0|0] "" Vector__XXX
 SG_ DAS_TE_meAebFlag m7 : 52|1@1+ (1,0) [0|0] "" Vector__XXX
 SG_ DAS_TE_robTrustRadarMap m9 : 52|1@1+ (1,0) [0|0] "" Vector__XXX
 SG_ DAS_TE_crashRear m8 : 53|1@1+ (1,0) [0|0] "" Vector__XXX
 SG_ DAS_TE_robActiveBraking m9 : 53|1@1+ (1,0) [0|0] "" Vector__XXX
 SG_ DAS_TE_crashRight m8 : 54|1@1+ (1,0) [0|0] "" Vector__XXX
 SG_ DAS_TE_crashRollover m8 : 55|1@1+ (1,0) [0|0] "" Vector__XXX
 SG_ DAS_TE_hppQlty m3 : 55|1@1+ (1,0) [0|0] "" Vector__XXX
 SG_ DAS_TE_llQlty m1 : 55|1@1+ (1,0) [0|0] "" Vector__XXX
 SG_ DAS_TE_navQlty m4 : 55|1@1+ (1,0) [0|0] "" Vector__XXX
 SG_ DAS_TE_rlQlty m2 : 55|1@1+ (1,0) [0|0] "" Vector__XXX
 SG_ DAS_TE_vlQlty m5 : 55|1@1+ (1,0) [0|0] "" Vector__XXX
 SG_ DAS_TE_crashPedPro m8 : 56|1@1+ (1,0) [0|0] "" Vector__XXX
 SG_ DAS_TE_hppRange m3 : 56|7@1+ (1,0) [0|0] "" Vector__XXX
 SG_ DAS_TE_llRange m1 : 56|7@1+ (1,0) [0|0] "" Vector__XXX
 SG_ DAS_TE_navRange m4 : 56|7@1+ (1,0) [0|0] "" Vector__XXX
 SG_ DAS_TE_rlRange m2 : 56|7@1+ (1,0) [0|0] "" Vector__XXX
 SG_ DAS_TE_vlRange m5 : 56|7@1+ (1,0) [0|0] "" Vector__XXX
 SG_ DAS_TE_meIpsoValid m8 : 57|1@1+ (1,0) [0|0] "" Vector__XXX
 SG_ DAS_TE_hppFuse m3 : 63|1@1+ (1,0) [0|0] "" Vector__XXX
 SG_ DAS_TE_llFuse m1 : 63|1@1+ (1,0) [0|0] "" Vector__XXX
 SG_ DAS_TE_navFuse m4 : 63|1@1+ (1,0) [0|0] "" Vector__XXX
 SG_ DAS_TE_rlFuse m2 : 63|1@1+ (1,0) [0|0] "" Vector__XXX
 SG_ DAS_TE_vlFuse m5 : 63|1@1+ (1,0) [0|0] "" Vector__XXX

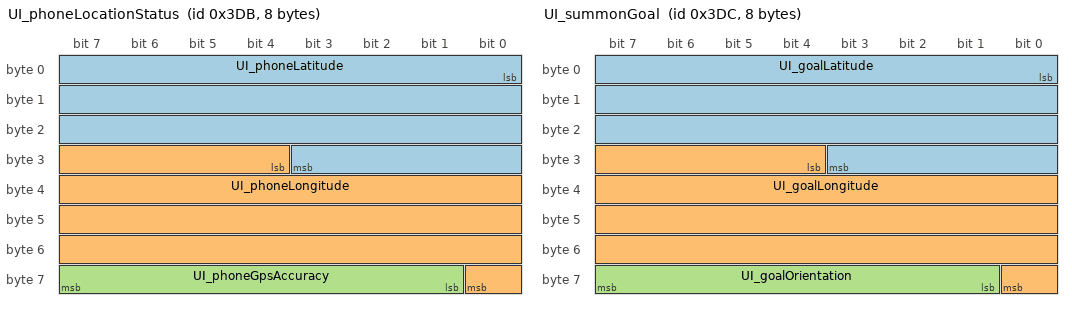
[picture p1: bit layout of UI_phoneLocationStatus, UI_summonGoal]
BO_ 987 UI_phoneLocationStatus: 8 Vector__XXX
 SG_ UI_phoneLatitude : 0|28@1- (1e-06,0) [0|0] "" Vector__XXX
 SG_ UI_phoneLongitude : 28|29@1- (1e-06,0) [0|0] "" Vector__XXX
 SG_ UI_phoneGpsAccuracy : 57|7@1+ (0.5,0) [0|0] "" Vector__XXX

BO_ 988 UI_summonGoal: 8 Vector__XXX
 SG_ UI_goalLatitude : 0|28@1- (1e-06,0) [0|0] "" Vector__XXX
 SG_ UI_goalLongitude : 28|29@1- (1e-06,0) [0|0] "" Vector__XXX
 SG_ UI_goalOrientation : 57|7@1+ (2.8125,0) [0|0] "" Vector__XXX

BO_ 991 UI_status2: 8 Vector__XXX
 SG_ UI_mobileAppStepCount : 0|16@1+ (1,0) [0|0] "" Vector__XXX
 SG_ UI_userRequestSnapshot : 16|1@1+ (1,0) [0|0] "" Vector__XXX
 SG_ UI_touchDetected : 17|1@1+ (1,0) [0|0] "" Vector__XXX
 SG_ UI_validDeviceForEUSummon : 18|1@1+ (1,0) [0|0] "" Vector__XXX
 SG_ UI_locatedAtHome : 19|1@1+ (1,0) [0|0] "" Vector__XXX
 SG_ UI_locatedAtWork : 20|1@1+ (1,0) [0|0] "" Vector__XXX
 SG_ UI_locatedAtFavorite : 21|1@1+ (1,0) [0|0] "" Vector__XXX
 SG_ UI_displayInDarkMode : 22|1@1+ (1,0) [0|0] "" Vector__XXX
 SG_ UI_userActivity : 23|1@1+ (1,0) [0|0] "" Vector__XXX
 SG_ UI_activeTouchPoints : 24|8@1+ (1,0) [0|0] "" Vector__XXX
 SG_ UI_linkState : 32|2@1+ (1,0) [0|0] "" Vector__XXX
 SG_ UI_sentryModeState : 34|3@1+ (1,0) [0|0] "" Vector__XXX
 SG_ UI_autopilotSentryRequest : 37|1@1+ (1,0) [0|0] "" Vector__XXX
 SG_ UI_mobileAppConnected : 38|1@1+ (1,0) [0|0] "" Vector__XXX
 SG_ UI_phoneLeftInCabin : 39|1@1+ (1,0) [0|0] "" Vector__XXX
 SG_ UI_autoshiftDRState : 40|3@1+ (1,0) [0|0] "" Vector__XXX
 SG_ UI_wifiBtModuleType : 43|3@1+ (1,0) [0|0] "" Vector__XXX
 SG_ UI_sohHealthStatus : 46|2@1+ (1,0) [0|0] "" Vector__XXX
 SG_ UI_selfParkState : 48|8@1+ (1,0) [0|0] "" Vector__XXX
 SG_ UI_summonDeviceIndex : 56|2@1+ (1,0) [0|0] "" Vector__XXX
 SG_ UI_fullScreenMode : 58|1@1+ (1,0) [0|0] "" Vector__XXX
 SG_ UI_sentryModeCameraDetection : 59|1@1+ (1,0) [0|0] "" Vector__XXX
 SG_ UI_wakeOnIPActive : 60|1@1+ (1,0) [0|0] "" Vector__XXX
 SG_ UI_sapActive : 61|1@1+ (1,0) [0|0] "" Vector__XXX
 SG_ UI_sapClients : 62|1@1+ (1,0) [0|0] "" Vector__XXX
 SG_ UI_connectivityStandbyActive : 63|1@1+ (1,0) [0|0] "" Vector__XXX

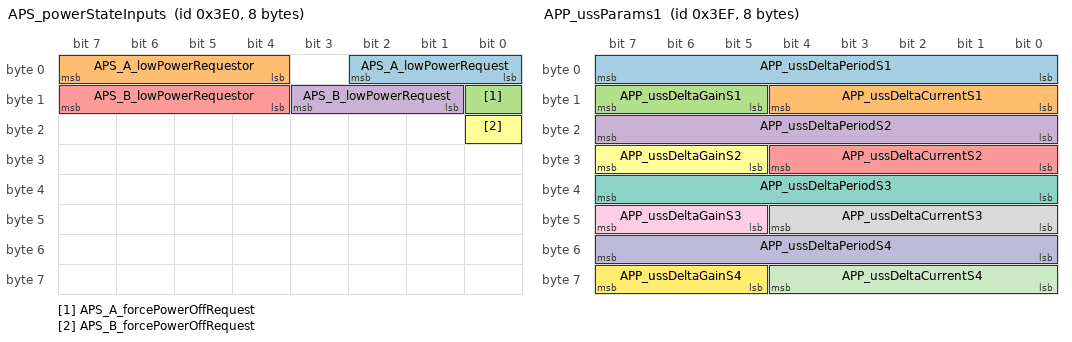
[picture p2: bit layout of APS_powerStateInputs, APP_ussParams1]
BO_ 992 APS_powerStateInputs: 8 Vector__XXX
 SG_ APS_A_lowPowerRequest : 0|3@1+ (1,0) [0|0] "" Vector__XXX
 SG_ APS_A_lowPowerRequestor : 4|4@1+ (1,0) [0|0] "" Vector__XXX
 SG_ APS_A_forcePowerOffRequest : 8|1@1+ (1,0) [0|0] "" Vector__XXX
 SG_ APS_B_lowPowerRequest : 9|3@1+ (1,0) [0|0] "" Vector__XXX
 SG_ APS_B_lowPowerRequestor : 12|4@1+ (1,0) [0|0] "" Vector__XXX
 SG_ APS_B_forcePowerOffRequest : 16|1@1+ (1,0) [0|0] "" Vector__XXX

BO_ 1000 APS_sysHealth2: 8 Vector__XXX
 SG_ APS_A_sysHealth : 0|1@1+ (1,0) [0|0] "" Vector__XXX
 SG_ APS_B_sysHealth : 1|1@1+ (1,0) [0|0] "" Vector__XXX
 SG_ APS_A_apsHealth : 2|1@1+ (1,0) [0|0] "" Vector__XXX
 SG_ APS_B_apsHealth : 3|1@1+ (1,0) [0|0] "" Vector__XXX
 SG_ APS_A_camPwrIssue : 4|1@1+ (1,0) [0|0] "" Vector__XXX
 SG_ APS_B_camPwrIssue : 5|1@1+ (1,0) [0|0] "" Vector__XXX
 SG_ APS_A_canFaulted : 6|1@1+ (1,0) [0|0] "" Vector__XXX
 SG_ APS_B_canFaulted : 7|1@1+ (1,0) [0|0] "" Vector__XXX
 SG_ APS_A_vrmFaulted : 8|1@1+ (1,0) [0|0] "" Vector__XXX
 SG_ APS_B_vrmFaulted : 9|1@1+ (1,0) [0|0] "" Vector__XXX
 SG_ APS_A_imemFaulted : 10|1@1+ (1,0) [0|0] "" Vector__XXX
 SG_ APS_B_imemFaulted : 11|1@1+ (1,0) [0|0] "" Vector__XXX
 SG_ APS_A_pmicFaulted : 12|1@1+ (1,0) [0|0] "" Vector__XXX
 SG_ APS_B_pmicFaulted : 13|1@1+ (1,0) [0|0] "" Vector__XXX
 SG_ APS_A_eplannerHasNoValidTrajectory : 14|1@1+ (1,0) [0|0] "" Vector__XXX
 SG_ APS_B_eplannerHasNoValidTrajectory : 15|1@1+ (1,0) [0|0] "" Vector__XXX
 SG_ APS_ethBridgeDown : 16|1@1+ (1,0) [0|0] "" Vector__XXX
 SG_ APS_sysHealth2Counter : 60|4@1+ (1,0) [0|0] "" Vector__XXX

BO_ 1007 APP_ussParams1: 8 Vector__XXX
 SG_ APP_ussDeltaPeriodS1 : 0|8@1- (1,0) [0|0] "" Vector__XXX
 SG_ APP_ussDeltaCurrentS1 : 8|5@1- (1,0) [0|0] "" Vector__XXX
 SG_ APP_ussDeltaGainS1 : 13|3@1- (1,0) [0|0] "" Vector__XXX
 SG_ APP_ussDeltaPeriodS2 : 16|8@1- (1,0) [0|0] "" Vector__XXX
 SG_ APP_ussDeltaCurrentS2 : 24|5@1- (1,0) [0|0] "" Vector__XXX
 SG_ APP_ussDeltaGainS2 : 29|3@1- (1,0) [0|0] "" Vector__XXX
 SG_ APP_ussDeltaPeriodS3 : 32|8@1- (1,0) [0|0] "" Vector__XXX
 SG_ APP_ussDeltaCurrentS3 : 40|5@1- (1,0) [0|0] "" Vector__XXX
 SG_ APP_ussDeltaGainS3 : 45|3@1- (1,0) [0|0] "" Vector__XXX
 SG_ APP_ussDeltaPeriodS4 : 48|8@1- (1,0) [0|0] "" Vector__XXX
 SG_ APP_ussDeltaCurrentS4 : 56|5@1- (1,0) [0|0] "" Vector__XXX
 SG_ APP_ussDeltaGainS4 : 61|3@1- (1,0) [0|0] "" Vector__XXX

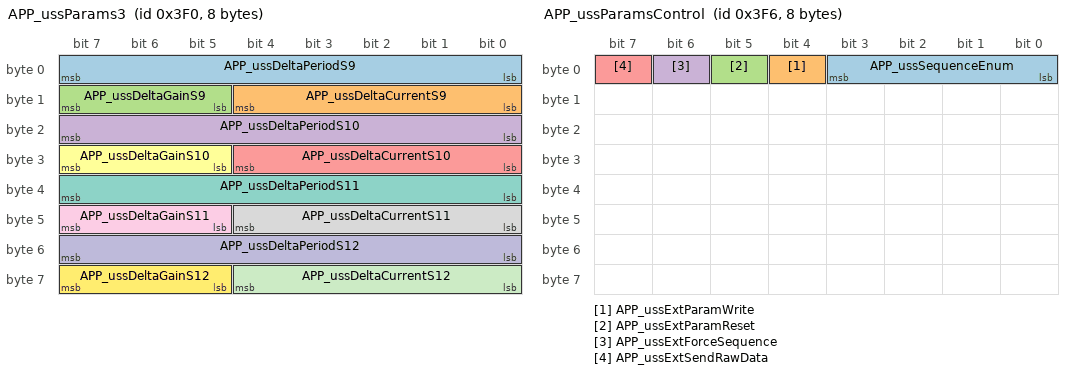
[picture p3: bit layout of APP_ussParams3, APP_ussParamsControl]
BO_ 1008 APP_ussParams3: 8 Vector__XXX
 SG_ APP_ussDeltaPeriodS9 : 0|8@1- (1,0) [0|0] "" Vector__XXX
 SG_ APP_ussDeltaCurrentS9 : 8|5@1- (1,0) [0|0] "" Vector__XXX
 SG_ APP_ussDeltaGainS9 : 13|3@1- (1,0) [0|0] "" Vector__XXX
 SG_ APP_ussDeltaPeriodS10 : 16|8@1- (1,0) [0|0] "" Vector__XXX
 SG_ APP_ussDeltaCurrentS10 : 24|5@1- (1,0) [0|0] "" Vector__XXX
 SG_ APP_ussDeltaGainS10 : 29|3@1- (1,0) [0|0] "" Vector__XXX
 SG_ APP_ussDeltaPeriodS11 : 32|8@1- (1,0) [0|0] "" Vector__XXX
 SG_ APP_ussDeltaCurrentS11 : 40|5@1- (1,0) [0|0] "" Vector__XXX
 SG_ APP_ussDeltaGainS11 : 45|3@1- (1,0) [0|0] "" Vector__XXX
 SG_ APP_ussDeltaPeriodS12 : 48|8@1- (1,0) [0|0] "" Vector__XXX
 SG_ APP_ussDeltaCurrentS12 : 56|5@1- (1,0) [0|0] "" Vector__XXX
 SG_ APP_ussDeltaGainS12 : 61|3@1- (1,0) [0|0] "" Vector__XXX

BO_ 1009 RCM2_alertMatrix: 8 Vector__XXX
 SG_ RCM2_matrixIndex M : 0|4@1+ (1,0) [0|0] "" Vector__XXX
 SG_ RCM2_a000_crashDetected m0 : 4|1@1+ (1,0) [0|0] "" Vector__XXX
 SG_ RCM2_a089_pretenShldRightShort m1 : 4|1@1+ (1,0) [0|0] "" Vector__XXX
 SG_ RCM2_a149_curABLeftShort m2 : 4|1@1+ (1,0) [0|0] "" Vector__XXX
 SG_ RCM2_a209_sideAB2ndRowLShort m3 : 4|1@1+ (1,0) [0|0] "" Vector__XXX
 SG_ RCM2_a303_imuAccYHgMonChlTemp m4 : 4|1@1+ (1,0) [0|0] "" Vector__XXX
 SG_ RCM2_a393_sideAccelBPilLCLosCoup m5 : 4|1@1+ (1,0) [0|0] "" Vector__XXX
 SG_ RCM2_a457_presPedProLDefect m6 : 4|1@1+ (1,0) [0|0] "" Vector__XXX
 SG_ RCM2_a521_sideAccelDPilRCrssCoup m7 : 4|1@1+ (1,0) [0|0] "" Vector__XXX
 SG_ RCM2_a609_comDItorque1ChkSm m8 : 4|1@1+ (1,0) [0|0] "" Vector__XXX
 SG_ RCM2_a669_comEPBLstatusMIA m9 : 4|1@1+ (1,0) [0|0] "" Vector__XXX
 SG_ RCM2_a825_upFrntPedProMRSht2Bat m10 : 4|1@1+ (1,0) [0|0] "" Vector__XXX
 SG_ RCM2_a001_nearDeploy m0 : 5|1@1+ (1,0) [0|0] "" Vector__XXX
 SG_ RCM2_a090_pretenShldRightCrssCou m1 : 5|1@1+ (1,0) [0|0] "" Vector__XXX
 SG_ RCM2_a150_curABLeftCrssCoup m2 : 5|1@1+ (1,0) [0|0] "" Vector__XXX
 SG_ RCM2_a210_sideAB2ndRowLCrssCoup m3 : 5|1@1+ (1,0) [0|0] "" Vector__XXX
 SG_ RCM2_a304_imuYawR8SnsrPermBG m4 : 5|1@1+ (1,0) [0|0] "" Vector__XXX
 SG_ RCM2_a394_sideAccelBPilLCommErr m5 : 5|1@1+ (1,0) [0|0] "" Vector__XXX
 SG_ RCM2_a458_presPedProLSigMon m6 : 5|1@1+ (1,0) [0|0] "" Vector__XXX
 SG_ RCM2_a522_sideAccelDPilRCommErr m7 : 5|1@1+ (1,0) [0|0] "" Vector__XXX
 SG_ RCM2_a610_comDItorque1Cntr m8 : 5|1@1+ (1,0) [0|0] "" Vector__XXX
 SG_ RCM2_a670_comEPBLstatusChkSm m9 : 5|1@1+ (1,0) [0|0] "" Vector__XXX
 SG_ RCM2_a826_upFrntPedProMROpen m10 : 5|1@1+ (1,0) [0|0] "" Vector__XXX
 SG_ RCM2_a002_airbagsUnArmed m0 : 6|1@1+ (1,0) [0|0] "" Vector__XXX
 SG_ RCM2_a091_pretenShldRightConfig m1 : 6|1@1+ (1,0) [0|0] "" Vector__XXX
 SG_ RCM2_a151_curABLeftConfig m2 : 6|1@1+ (1,0) [0|0] "" Vector__XXX
 SG_ RCM2_a211_sideAB2ndRowLConfig m3 : 6|1@1+ (1,0) [0|0] "" Vector__XXX
 SG_ RCM2_a305_imuYawR8SnsrPermInit m4 : 6|1@1+ (1,0) [0|0] "" Vector__XXX
 SG_ RCM2_a395_sideAccelBPilLInitTyp m5 : 6|1@1+ (1,0) [0|0] "" Vector__XXX
 SG_ RCM2_a460_presPedProRSht2Gnd m6 : 6|1@1+ (1,0) [0|0] "" Vector__XXX
 SG_ RCM2_a523_sideAccelDPilRInitTyp m7 : 6|1@1+ (1,0) [0|0] "" Vector__XXX
 SG_ RCM2_a611_comDItorque2MIA m8 : 6|1@1+ (1,0) [0|0] "" Vector__XXX
 SG_ RCM2_a671_comEPBLstatusCntr m9 : 6|1@1+ (1,0) [0|0] "" Vector__XXX
 SG_ RCM2_a827_upFrntPedProMRCrssCoup m10 : 6|1@1+ (1,0) [0|0] "" Vector__XXX
 SG_ RCM2_a003_warningIndicator m0 : 7|1@1+ (1,0) [0|0] "" Vector__XXX
 SG_ RCM2_a092_pretenLapLeftSht2Gnd m1 : 7|1@1+ (1,0) [0|0] "" Vector__XXX
 SG_ RCM2_a152_curABRightSht2Gnd m2 : 7|1@1+ (1,0) [0|0] "" Vector__XXX
 SG_ RCM2_a212_sideAB2ndRowRSht2Gnd m3 : 7|1@1+ (1,0) [0|0] "" Vector__XXX
 SG_ RCM2_a306_imuYawR8SnsrPermLF m4 : 7|1@1+ (1,0) [0|0] "" Vector__XXX
 SG_ RCM2_a396_sideAccelBPilLConfig m5 : 7|1@1+ (1,0) [0|0] "" Vector__XXX
 SG_ RCM2_a461_presPedProRSht2Bat m6 : 7|1@1+ (1,0) [0|0] "" Vector__XXX
 SG_ RCM2_a524_sideAccelDPilRConfig m7 : 7|1@1+ (1,0) [0|0] "" Vector__XXX
 SG_ RCM2_a612_comDItorque2ChkSm m8 : 7|1@1+ (1,0) [0|0] "" Vector__XXX
 SG_ RCM2_a672_comEPBRstatusMIA m9 : 7|1@1+ (1,0) [0|0] "" Vector__XXX
 SG_ RCM2_a828_upFrntPedProMRCommErr m10 : 7|1@1+ (1,0) [0|0] "" Vector__XXX
 SG_ RCM2_a004_crashAlgoWakeup m0 : 8|1@1+ (1,0) [0|0] "" Vector__XXX
 SG_ RCM2_a093_pretenLapLeftSht2Bat m1 : 8|1@1+ (1,0) [0|0] "" Vector__XXX
 SG_ RCM2_a153_curABRightSht2Bat m2 : 8|1@1+ (1,0) [0|0] "" Vector__XXX
 SG_ RCM2_a213_sideAB2ndRowRSht2Bat m3 : 8|1@1+ (1,0) [0|0] "" Vector__XXX
 SG_ RCM2_a307_imuYawR8ChnlMonTmpLF m4 : 8|1@1+ (1,0) [0|0] "" Vector__XXX
 SG_ RCM2_a397_sideAccelBPilLDefect m5 : 8|1@1+ (1,0) [0|0] "" Vector__XXX
 SG_ RCM2_a462_presPedProROpen m6 : 8|1@1+ (1,0) [0|0] "" Vector__XXX
 SG_ RCM2_a525_sideAccelDPilRDefect m7 : 8|1@1+ (1,0) [0|0] "" Vector__XXX
 SG_ RCM2_a613_comDItorque2Cntr m8 : 8|1@1+ (1,0) [0|0] "" Vector__XXX
 SG_ RCM2_a673_comEPBRstatusChkSm m9 : 8|1@1+ (1,0) [0|0] "" Vector__XXX
 SG_ RCM2_a829_upFrntPedProMRIntTyp m10 : 8|1@1+ (1,0) [0|0] "" Vector__XXX
 SG_ RCM2_a005_abuseImmunityThrshold m0 : 9|1@1+ (1,0) [0|0] "" Vector__XXX
 SG_ RCM2_a094_pretenLapLeftOpen m1 : 9|1@1+ (1,0) [0|0] "" Vector__XXX
 SG_ RCM2_a154_curABRightOpen m2 : 9|1@1+ (1,0) [0|0] "" Vector__XXX
 SG_ RCM2_a214_sideAB2ndRowROpen m3 : 9|1@1+ (1,0) [0|0] "" Vector__XXX
 SG_ RCM2_a308_imuPitchR8SnsrPermBG m4 : 9|1@1+ (1,0) [0|0] "" Vector__XXX
 SG_ RCM2_a398_sideAccelBPilLSigMon m5 : 9|1@1+ (1,0) [0|0] "" Vector__XXX
 SG_ RCM2_a463_presPedProRCrssCoup m6 : 9|1@1+ (1,0) [0|0] "" Vector__XXX
 SG_ RCM2_a526_sideAccelDPilRSigMon m7 : 9|1@1+ (1,0) [0|0] "" Vector__XXX
 SG_ RCM2_a614_comESP135MIA m8 : 9|1@1+ (1,0) [0|0] "" Vector__XXX
 SG_ RCM2_a674_comEPBRstatusCntr m9 : 9|1@1+ (1,0) [0|0] "" Vector__XXX
 SG_ RCM2_a830_upFrntPedProMRConfig m10 : 9|1@1+ (1,0) [0|0] "" Vector__XXX
 SG_ RCM2_a006_supplierDiagEnabled m0 : 10|1@1+ (1,0) [0|0] "" Vector__XXX
 SG_ RCM2_a095_pretenLapLeftShort m1 : 10|1@1+ (1,0) [0|0] "" Vector__XXX
 SG_ RCM2_a155_curABRightShort m2 : 10|1@1+ (1,0) [0|0] "" Vector__XXX
 SG_ RCM2_a215_sideAB2ndRowRShort m3 : 10|1@1+ (1,0) [0|0] "" Vector__XXX
 SG_ RCM2_a309_imuPitchR8SnsrPermInit m4 : 10|1@1+ (1,0) [0|0] "" Vector__XXX
 SG_ RCM2_a400_sideAccelBPilRSht2Gnd m5 : 10|1@1+ (1,0) [0|0] "" Vector__XXX
 SG_ RCM2_a464_presPedProRCommErr m6 : 10|1@1+ (1,0) [0|0] "" Vector__XXX
 SG_ RCM2_a527_upFrntSnsrCSht2Gnd m7 : 10|1@1+ (1,0) [0|0] "" Vector__XXX
 SG_ RCM2_a615_comESP135ChkSm m8 : 10|1@1+ (1,0) [0|0] "" Vector__XXX
 SG_ RCM2_a675_comUIodoMIA m9 : 10|1@1+ (1,0) [0|0] "" Vector__XXX
 SG_ RCM2_a831_upFrntPedProMRDefect m10 : 10|1@1+ (1,0) [0|0] "" Vector__XXX
 SG_ RCM2_a007_pedProCrashDetected m0 : 11|1@1+ (1,0) [0|0] "" Vector__XXX
 SG_ RCM2_a096_pretenLapLeftCrssCoup m1 : 11|1@1+ (1,0) [0|0] "" Vector__XXX
 SG_ RCM2_a156_curABRightCrssCoup m2 : 11|1@1+ (1,0) [0|0] "" Vector__XXX
 SG_ RCM2_a216_sideAB2ndRowRCrssCoup m3 : 11|1@1+ (1,0) [0|0] "" Vector__XXX
 SG_ RCM2_a310_imuPitchR8SnsrPermLF m4 : 11|1@1+ (1,0) [0|0] "" Vector__XXX
 SG_ RCM2_a401_sideAccelBPilRSht2Bat m5 : 11|1@1+ (1,0) [0|0] "" Vector__XXX
 SG_ RCM2_a465_presPedProRInitTyp m6 : 11|1@1+ (1,0) [0|0] "" Vector__XXX
 SG_ RCM2_a528_upFrntSnsrCSht2Bat m7 : 11|1@1+ (1,0) [0|0] "" Vector__XXX
 SG_ RCM2_a616_comESP135Cntr m8 : 11|1@1+ (1,0) [0|0] "" Vector__XXX
 SG_ RCM2_a676_comEPAS3PsysMIA m9 : 11|1@1+ (1,0) [0|0] "" Vector__XXX
 SG_ RCM2_a832_upFrntPedProMRSigMon m10 : 11|1@1+ (1,0) [0|0] "" Vector__XXX
 SG_ RCM2_a008_factoryMode m0 : 12|1@1+ (1,0) [0|0] "" Vector__XXX
 SG_ RCM2_a097_pretenLapLeftConfig m1 : 12|1@1+ (1,0) [0|0] "" Vector__XXX
 SG_ RCM2_a157_curABRightConfig m2 : 12|1@1+ (1,0) [0|0] "" Vector__XXX
 SG_ RCM2_a217_sideAB2ndRowRConfig m3 : 12|1@1+ (1,0) [0|0] "" Vector__XXX
 SG_ RCM2_a311_imuPitchR8ChnlMonTmpLF m4 : 12|1@1+ (1,0) [0|0] "" Vector__XXX
 SG_ RCM2_a402_sideAccelBPilROpen m5 : 12|1@1+ (1,0) [0|0] "" Vector__XXX
 SG_ RCM2_a466_presPedProRConfig m6 : 12|1@1+ (1,0) [0|0] "" Vector__XXX
 SG_ RCM2_a529_upFrntSnsrCOpen m7 : 12|1@1+ (1,0) [0|0] "" Vector__XXX
 SG_ RCM2_a617_comESP145MIA m8 : 12|1@1+ (1,0) [0|0] "" Vector__XXX
 SG_ RCM2_a677_comEPAS3PsysChkSm m9 : 12|1@1+ (1,0) [0|0] "" Vector__XXX
 SG_ RCM2_a833_pretenShldCSht2Gnd m10 : 12|1@1+ (1,0) [0|0] "" Vector__XXX
 SG_ RCM2_a009_edrDataAreaLocked m0 : 13|1@1+ (1,0) [0|0] "" Vector__XXX
 SG_ RCM2_a098_pretenLapRightSht2Gnd m1 : 13|1@1+ (1,0) [0|0] "" Vector__XXX
 SG_ RCM2_a158_preten2ndRowLSht2Gnd m2 : 13|1@1+ (1,0) [0|0] "" Vector__XXX
 SG_ RCM2_a250_ens1Sht2Bat m3 : 13|1@1+ (1,0) [0|0] "" Vector__XXX
 SG_ RCM2_a312_imuRollR8SnsrPermBG m4 : 13|1@1+ (1,0) [0|0] "" Vector__XXX
 SG_ RCM2_a403_sideAccelBPilRCrssCoup m5 : 13|1@1+ (1,0) [0|0] "" Vector__XXX
 SG_ RCM2_a467_presPedProRDefect m6 : 13|1@1+ (1,0) [0|0] "" Vector__XXX
 SG_ RCM2_a530_upFrntSnsrCCrssCoup m7 : 13|1@1+ (1,0) [0|0] "" Vector__XXX
 SG_ RCM2_a618_comESP145ChkSm m8 : 13|1@1+ (1,0) [0|0] "" Vector__XXX
 SG_ RCM2_a678_comEPAS3PsysCntr m9 : 13|1@1+ (1,0) [0|0] "" Vector__XXX
 SG_ RCM2_a834_pretenShldCSht2Bat m10 : 13|1@1+ (1,0) [0|0] "" Vector__XXX
 SG_ RCM2_a010_pedProEDRDataLocked m0 : 14|1@1+ (1,0) [0|0] "" Vector__XXX
 SG_ RCM2_a099_pretenLapRightSht2Bat m1 : 14|1@1+ (1,0) [0|0] "" Vector__XXX
 SG_ RCM2_a159_preten2ndRowLSht2Bat m2 : 14|1@1+ (1,0) [0|0] "" Vector__XXX
 SG_ RCM2_a251_ens1Sht2Gnd m3 : 14|1@1+ (1,0) [0|0] "" Vector__XXX
 SG_ RCM2_a313_imuRollR8SnsrPermInit m4 : 14|1@1+ (1,0) [0|0] "" Vector__XXX
 SG_ RCM2_a404_sideAccelBPilRCommErr m5 : 14|1@1+ (1,0) [0|0] "" Vector__XXX
 SG_ RCM2_a468_presPedProRSigMon m6 : 14|1@1+ (1,0) [0|0] "" Vector__XXX
 SG_ RCM2_a531_upFrntSnsrCCommErr m7 : 14|1@1+ (1,0) [0|0] "" Vector__XXX
 SG_ RCM2_a619_comESP145Cntr m8 : 14|1@1+ (1,0) [0|0] "" Vector__XXX
 SG_ RCM2_a679_comESPwheelSpeedsMIA m9 : 14|1@1+ (1,0) [0|0] "" Vector__XXX
 SG_ RCM2_a835_pretenShldCOpen m10 : 14|1@1+ (1,0) [0|0] "" Vector__XXX
 SG_ RCM2_a011_placeholder0 m0 : 15|1@1+ (1,0) [0|0] "" Vector__XXX
 SG_ RCM2_a100_pretenLapRightOpen m1 : 15|1@1+ (1,0) [0|0] "" Vector__XXX
 SG_ RCM2_a160_preten2ndRowLOpen m2 : 15|1@1+ (1,0) [0|0] "" Vector__XXX
 SG_ RCM2_a252_ens1Config m3 : 15|1@1+ (1,0) [0|0] "" Vector__XXX
 SG_ RCM2_a314_imuRollR8SnsrPermLF m4 : 15|1@1+ (1,0) [0|0] "" Vector__XXX
 SG_ RCM2_a405_sideAccelBPilRInitTyp m5 : 15|1@1+ (1,0) [0|0] "" Vector__XXX
 SG_ RCM2_a469_presPedProAbsolute m6 : 15|1@1+ (1,0) [0|0] "" Vector__XXX
 SG_ RCM2_a532_upFrntSnsrCInitTyp m7 : 15|1@1+ (1,0) [0|0] "" Vector__XXX
 SG_ RCM2_a620_comInvalidVehicleSpeed m8 : 15|1@1+ (1,0) [0|0] "" Vector__XXX
 SG_ RCM2_a680_comESPwheelSpeedsChkSm m9 : 15|1@1+ (1,0) [0|0] "" Vector__XXX
 SG_ RCM2_a836_pretenShldCShort m10 : 15|1@1+ (1,0) [0|0] "" Vector__XXX
 SG_ RCM2_a012_placeholder1 m0 : 16|1@1+ (1,0) [0|0] "" Vector__XXX
 SG_ RCM2_a101_pretenLapRightShort m1 : 16|1@1+ (1,0) [0|0] "" Vector__XXX
 SG_ RCM2_a161_preten2ndRowLShort m2 : 16|1@1+ (1,0) [0|0] "" Vector__XXX
 SG_ RCM2_a253_ens2Sht2Bat m3 : 16|1@1+ (1,0) [0|0] "" Vector__XXX
 SG_ RCM2_a315_imuRollR8ChnlMonTmpLF m4 : 16|1@1+ (1,0) [0|0] "" Vector__XXX
 SG_ RCM2_a406_sideAccelBPilRConfig m5 : 16|1@1+ (1,0) [0|0] "" Vector__XXX
 SG_ RCM2_a470_upFrntPedProLSht2Gnd m6 : 16|1@1+ (1,0) [0|0] "" Vector__XXX
 SG_ RCM2_a533_upFrntSnsrCConfig m7 : 16|1@1+ (1,0) [0|0] "" Vector__XXX
 SG_ RCM2_a621_comESPBMIA m8 : 16|1@1+ (1,0) [0|0] "" Vector__XXX
 SG_ RCM2_a681_comESPwheelSpeedsCntr m9 : 16|1@1+ (1,0) [0|0] "" Vector__XXX
 SG_ RCM2_a837_pretenShldCCrossC m10 : 16|1@1+ (1,0) [0|0] "" Vector__XXX
 SG_ RCM2_a013_placeholder2 m0 : 17|1@1+ (1,0) [0|0] "" Vector__XXX
 SG_ RCM2_a102_pretenLapRightCrssCoup m1 : 17|1@1+ (1,0) [0|0] "" Vector__XXX
 SG_ RCM2_a162_preten2ndRowLCrssCoup m2 : 17|1@1+ (1,0) [0|0] "" Vector__XXX
 SG_ RCM2_a254_ens2Sht2Gnd m3 : 17|1@1+ (1,0) [0|0] "" Vector__XXX
 SG_ RCM2_a316_imuAccXLgMonChlPerm m4 : 17|1@1+ (1,0) [0|0] "" Vector__XXX
 SG_ RCM2_a407_sideAccelBPilRDefect m5 : 17|1@1+ (1,0) [0|0] "" Vector__XXX
 SG_ RCM2_a471_upFrntPedProLSht2Bat m6 : 17|1@1+ (1,0) [0|0] "" Vector__XXX
 SG_ RCM2_a534_upFrntSnsrCDefect m7 : 17|1@1+ (1,0) [0|0] "" Vector__XXX
 SG_ RCM2_a622_comESPBChkSm m8 : 17|1@1+ (1,0) [0|0] "" Vector__XXX
 SG_ RCM2_a682_comDIspeedMIA m9 : 17|1@1+ (1,0) [0|0] "" Vector__XXX
 SG_ RCM2_a838_pretenShldCConfig m10 : 17|1@1+ (1,0) [0|0] "" Vector__XXX
 SG_ RCM2_a014_pedProNearDeploy m0 : 18|1@1+ (1,0) [0|0] "" Vector__XXX
 SG_ RCM2_a103_pretenLapRightConfig m1 : 18|1@1+ (1,0) [0|0] "" Vector__XXX
 SG_ RCM2_a163_preten2ndRowLCgf m2 : 18|1@1+ (1,0) [0|0] "" Vector__XXX
 SG_ RCM2_a255_ens2Config m3 : 18|1@1+ (1,0) [0|0] "" Vector__XXX
 SG_ RCM2_a317_imuAccXLgMonChlTemp m4 : 18|1@1+ (1,0) [0|0] "" Vector__XXX
 SG_ RCM2_a408_sideAccelBPilRSigMon m5 : 18|1@1+ (1,0) [0|0] "" Vector__XXX
 SG_ RCM2_a472_upFrntPedProLOpen m6 : 18|1@1+ (1,0) [0|0] "" Vector__XXX
 SG_ RCM2_a535_upFrntSnsrCSigMon m7 : 18|1@1+ (1,0) [0|0] "" Vector__XXX
 SG_ RCM2_a623_comESPBCntr m8 : 18|1@1+ (1,0) [0|0] "" Vector__XXX
 SG_ RCM2_a683_comDIspeedChkSm m9 : 18|1@1+ (1,0) [0|0] "" Vector__XXX
 SG_ RCM2_a839_preten2ndRowCSht2Gnd m10 : 18|1@1+ (1,0) [0|0] "" Vector__XXX
 SG_ RCM2_a015_noDeployCrashCal m0 : 19|1@1+ (1,0) [0|0] "" Vector__XXX
 SG_ RCM2_a104_loadLimLeftSht2Gnd m1 : 19|1@1+ (1,0) [0|0] "" Vector__XXX
 SG_ RCM2_a164_preten2ndRowRSht2Gnd m2 : 19|1@1+ (1,0) [0|0] "" Vector__XXX
 SG_ RCM2_a256_ens3Sht2Bat m3 : 19|1@1+ (1,0) [0|0] "" Vector__XXX
 SG_ RCM2_a318_imuAccYLgMonChlPerm m4 : 19|1@1+ (1,0) [0|0] "" Vector__XXX
 SG_ RCM2_a410_sideAccelCPilLSht2Gnd m5 : 19|1@1+ (1,0) [0|0] "" Vector__XXX
 SG_ RCM2_a473_upFrntPedProLCrssCoup m6 : 19|1@1+ (1,0) [0|0] "" Vector__XXX
 SG_ RCM2_a550_bucklHallLeftSht2Gnd m7 : 19|1@1+ (1,0) [0|0] "" Vector__XXX
 SG_ RCM2_a624_comESPCMIA m8 : 19|1@1+ (1,0) [0|0] "" Vector__XXX
 SG_ RCM2_a684_comDIspeedCntr m9 : 19|1@1+ (1,0) [0|0] "" Vector__XXX
 SG_ RCM2_a840_preten2ndRowCSht2Bat m10 : 19|1@1+ (1,0) [0|0] "" Vector__XXX
 SG_ RCM2_a016_noDeployPedProCal m0 : 20|1@1+ (1,0) [0|0] "" Vector__XXX
 SG_ RCM2_a105_loadLimLeftSht2Bat m1 : 20|1@1+ (1,0) [0|0] "" Vector__XXX
 SG_ RCM2_a165_preten2ndRowRSht2Bat m2 : 20|1@1+ (1,0) [0|0] "" Vector__XXX
 SG_ RCM2_a257_ens3Sht2Gnd m3 : 20|1@1+ (1,0) [0|0] "" Vector__XXX
 SG_ RCM2_a319_imuAccYLgMonChlTemp m4 : 20|1@1+ (1,0) [0|0] "" Vector__XXX
 SG_ RCM2_a411_sideAccelCPilLSht2Bat m5 : 20|1@1+ (1,0) [0|0] "" Vector__XXX
 SG_ RCM2_a474_upFrntPedProLCommErr m6 : 20|1@1+ (1,0) [0|0] "" Vector__XXX
 SG_ RCM2_a551_bucklHallLeftSht2Bat m7 : 20|1@1+ (1,0) [0|0] "" Vector__XXX
 SG_ RCM2_a625_comESPCChkSm m8 : 20|1@1+ (1,0) [0|0] "" Vector__XXX
 SG_ RCM2_a685_comDIchassControlMIA m9 : 20|1@1+ (1,0) [0|0] "" Vector__XXX
 SG_ RCM2_a841_preten2ndRowCOpen m10 : 20|1@1+ (1,0) [0|0] "" Vector__XXX
 SG_ RCM2_a017_ecuLogAvailable m0 : 21|1@1+ (1,0) [0|0] "" Vector__XXX
 SG_ RCM2_a106_loadLimLeftOpen m1 : 21|1@1+ (1,0) [0|0] "" Vector__XXX
 SG_ RCM2_a166_preten2ndRowROpen m2 : 21|1@1+ (1,0) [0|0] "" Vector__XXX
 SG_ RCM2_a258_ens3Config m3 : 21|1@1+ (1,0) [0|0] "" Vector__XXX
 SG_ RCM2_a320_imuAccZLgMonChlPerm m4 : 21|1@1+ (1,0) [0|0] "" Vector__XXX
 SG_ RCM2_a412_sideAccelCPilLOpen m5 : 21|1@1+ (1,0) [0|0] "" Vector__XXX
 SG_ RCM2_a475_upFrntPedProLIntTyp m6 : 21|1@1+ (1,0) [0|0] "" Vector__XXX
 SG_ RCM2_a552_bucklHallLeftOpen m7 : 21|1@1+ (1,0) [0|0] "" Vector__XXX
 SG_ RCM2_a626_comESPCCntr m8 : 21|1@1+ (1,0) [0|0] "" Vector__XXX
 SG_ RCM2_a686_comDIchassControlChkSm m9 : 21|1@1+ (1,0) [0|0] "" Vector__XXX
 SG_ RCM2_a842_preten2ndRowCShort m10 : 21|1@1+ (1,0) [0|0] "" Vector__XXX
 SG_ RCM2_a047_batteryESRhigh m0 : 22|1@1+ (1,0) [0|0] "" Vector__XXX
 SG_ RCM2_a107_loadLimLeftShort m1 : 22|1@1+ (1,0) [0|0] "" Vector__XXX
 SG_ RCM2_a167_preten2ndRowRShort m2 : 22|1@1+ (1,0) [0|0] "" Vector__XXX
 SG_ RCM2_a259_ens4Sht2Bat m3 : 22|1@1+ (1,0) [0|0] "" Vector__XXX
 SG_ RCM2_a321_imuAccZLgMonChlTemp m4 : 22|1@1+ (1,0) [0|0] "" Vector__XXX
 SG_ RCM2_a413_sideAccelCPilLCrssCoup m5 : 22|1@1+ (1,0) [0|0] "" Vector__XXX
 SG_ RCM2_a476_upFrntPedProLConfig m6 : 22|1@1+ (1,0) [0|0] "" Vector__XXX
 SG_ RCM2_a553_bucklHallLeftUndef m7 : 22|1@1+ (1,0) [0|0] "" Vector__XXX
 SG_ RCM2_a627_comEPBStatusMIA m8 : 22|1@1+ (1,0) [0|0] "" Vector__XXX
 SG_ RCM2_a687_comDIchassControlCntr m9 : 22|1@1+ (1,0) [0|0] "" Vector__XXX
 SG_ RCM2_a843_preten2ndRowCCrssCoup m10 : 22|1@1+ (1,0) [0|0] "" Vector__XXX
 SG_ RCM2_a048_batteryVoltageTooHigh m0 : 23|1@1+ (1,0) [0|0] "" Vector__XXX
 SG_ RCM2_a108_loadLimLeftCrssCoup m1 : 23|1@1+ (1,0) [0|0] "" Vector__XXX
 SG_ RCM2_a168_preten2ndRowRCrssCoup m2 : 23|1@1+ (1,0) [0|0] "" Vector__XXX
 SG_ RCM2_a260_ens4Sht2Gnd m3 : 23|1@1+ (1,0) [0|0] "" Vector__XXX
 SG_ RCM2_a322_imuCalibrationFailed m4 : 23|1@1+ (1,0) [0|0] "" Vector__XXX
 SG_ RCM2_a414_sideAccelCPilLCommErr m5 : 23|1@1+ (1,0) [0|0] "" Vector__XXX
 SG_ RCM2_a477_upFrntPedProLDefect m6 : 23|1@1+ (1,0) [0|0] "" Vector__XXX
 SG_ RCM2_a554_bucklHallLeftCrssCoup m7 : 23|1@1+ (1,0) [0|0] "" Vector__XXX
 SG_ RCM2_a628_comEPBStatusChkSm m8 : 23|1@1+ (1,0) [0|0] "" Vector__XXX
 SG_ RCM2_a688_comVCLEFTrestMIA m9 : 23|1@1+ (1,0) [0|0] "" Vector__XXX
 SG_ RCM2_a844_preten2ndRowCConfig m10 : 23|1@1+ (1,0) [0|0] "" Vector__XXX
 SG_ RCM2_a049_batteryVoltageTooLow m0 : 24|1@1+ (1,0) [0|0] "" Vector__XXX
 SG_ RCM2_a109_loadLimLeftConfig m1 : 24|1@1+ (1,0) [0|0] "" Vector__XXX
 SG_ RCM2_a169_preten2ndRowRCgf m2 : 24|1@1+ (1,0) [0|0] "" Vector__XXX
 SG_ RCM2_a261_ens4Config m3 : 24|1@1+ (1,0) [0|0] "" Vector__XXX
 SG_ RCM2_a323_imuCalibrationNotDone m4 : 24|1@1+ (1,0) [0|0] "" Vector__XXX
 SG_ RCM2_a415_sideAccelCPilLInitTyp m5 : 24|1@1+ (1,0) [0|0] "" Vector__XXX
 SG_ RCM2_a478_upFrntPedProLSigMon m6 : 24|1@1+ (1,0) [0|0] "" Vector__XXX
 SG_ RCM2_a555_bucklHallLeftConfig m7 : 24|1@1+ (1,0) [0|0] "" Vector__XXX
 SG_ RCM2_a629_comEPBStatusCntr m8 : 24|1@1+ (1,0) [0|0] "" Vector__XXX
 SG_ RCM2_a689_comVCLEFTrestChkSm m9 : 24|1@1+ (1,0) [0|0] "" Vector__XXX
 SG_ RCM2_a845_comUIchassisControlMIA m10 : 24|1@1+ (1,0) [0|0] "" Vector__XXX
 SG_ RCM2_a050_driverABStg1Sht2Gnd m0 : 25|1@1+ (1,0) [0|0] "" Vector__XXX
 SG_ RCM2_a110_loadLimRightSht2Gnd m1 : 25|1@1+ (1,0) [0|0] "" Vector__XXX
 SG_ RCM2_a170_curAB2ndRowLSht2Gnd m2 : 25|1@1+ (1,0) [0|0] "" Vector__XXX
 SG_ RCM2_a264_imuYawR8OffCompPosLife m3 : 25|1@1+ (1,0) [0|0] "" Vector__XXX
 SG_ RCM2_a350_upFrntSnsrLSht2Gnd m4 : 25|1@1+ (1,0) [0|0] "" Vector__XXX
 SG_ RCM2_a416_sideAccelCPilLConfig m5 : 25|1@1+ (1,0) [0|0] "" Vector__XXX
 SG_ RCM2_a480_upFrntPedProRSht2Gnd m6 : 25|1@1+ (1,0) [0|0] "" Vector__XXX
 SG_ RCM2_a556_bucklHallRightSht2Gnd m7 : 25|1@1+ (1,0) [0|0] "" Vector__XXX
 SG_ RCM2_a630_comGTWACSMIA m8 : 25|1@1+ (1,0) [0|0] "" Vector__XXX
 SG_ RCM2_a690_comVCLEFTrestCntr m9 : 25|1@1+ (1,0) [0|0] "" Vector__XXX
 SG_ RCM2_a846_comSCCMstrAnglSnsMIA m10 : 25|1@1+ (1,0) [0|0] "" Vector__XXX
 SG_ RCM2_a051_driverABStg1Sht2Bat m0 : 26|1@1+ (1,0) [0|0] "" Vector__XXX
 SG_ RCM2_a111_loadLimRightSht2Bat m1 : 26|1@1+ (1,0) [0|0] "" Vector__XXX
 SG_ RCM2_a171_curAB2ndRowLSht2Bat m2 : 26|1@1+ (1,0) [0|0] "" Vector__XXX
 SG_ RCM2_a265_imuYawR8OffCompNegLife m3 : 26|1@1+ (1,0) [0|0] "" Vector__XXX
 SG_ RCM2_a351_upFrntSnsrLSht2Bat m4 : 26|1@1+ (1,0) [0|0] "" Vector__XXX
 SG_ RCM2_a417_sideAccelCPilLDefect m5 : 26|1@1+ (1,0) [0|0] "" Vector__XXX
 SG_ RCM2_a481_upFrntPedProRSht2Bat m6 : 26|1@1+ (1,0) [0|0] "" Vector__XXX
 SG_ RCM2_a557_bucklHallRightSht2Bat m7 : 26|1@1+ (1,0) [0|0] "" Vector__XXX
 SG_ RCM2_a631_comGTWACSChkSm m8 : 26|1@1+ (1,0) [0|0] "" Vector__XXX
 SG_ RCM2_a691_comVCLEFT1rLBuckle m9 : 26|1@1+ (1,0) [0|0] "" Vector__XXX
 SG_ RCM2_a847_comDASctrlMIA m10 : 26|1@1+ (1,0) [0|0] "" Vector__XXX
 SG_ RCM2_a052_driverABStg1Open m0 : 27|1@1+ (1,0) [0|0] "" Vector__XXX
 SG_ RCM2_a112_loadLimRightOpen m1 : 27|1@1+ (1,0) [0|0] "" Vector__XXX
 SG_ RCM2_a172_curAB2ndRowLOpen m2 : 27|1@1+ (1,0) [0|0] "" Vector__XXX
 SG_ RCM2_a266_imuYawR8OffCompPosFLDC m3 : 27|1@1+ (1,0) [0|0] "" Vector__XXX
 SG_ RCM2_a352_upFrntSnsrLOpen m4 : 27|1@1+ (1,0) [0|0] "" Vector__XXX
 SG_ RCM2_a418_sideAccelCPilLSigMon m5 : 27|1@1+ (1,0) [0|0] "" Vector__XXX
 SG_ RCM2_a482_upFrntPedProROpen m6 : 27|1@1+ (1,0) [0|0] "" Vector__XXX
 SG_ RCM2_a558_bucklHallRightOpen m7 : 27|1@1+ (1,0) [0|0] "" Vector__XXX
 SG_ RCM2_a632_comGTWACSCntr m8 : 27|1@1+ (1,0) [0|0] "" Vector__XXX
 SG_ RCM2_a692_comVCLEFT2rLBuckle m9 : 27|1@1+ (1,0) [0|0] "" Vector__XXX
 SG_ RCM2_a848_comDIlocStatMIA m10 : 27|1@1+ (1,0) [0|0] "" Vector__XXX
 SG_ RCM2_a053_driverABStg1Short m0 : 28|1@1+ (1,0) [0|0] "" Vector__XXX
 SG_ RCM2_a113_loadLimRightShort m1 : 28|1@1+ (1,0) [0|0] "" Vector__XXX
 SG_ RCM2_a173_curAB2ndRowLShort m2 : 28|1@1+ (1,0) [0|0] "" Vector__XXX
 SG_ RCM2_a267_imuYawR8OffCompNegFLDC m3 : 28|1@1+ (1,0) [0|0] "" Vector__XXX
 SG_ RCM2_a353_upFrntSnsrLCrssCoup m4 : 28|1@1+ (1,0) [0|0] "" Vector__XXX
 SG_ RCM2_a420_sideAccelCPilRSht2Gnd m5 : 28|1@1+ (1,0) [0|0] "" Vector__XXX
 SG_ RCM2_a483_upFrntPedProRCrssCoup m6 : 28|1@1+ (1,0) [0|0] "" Vector__XXX
 SG_ RCM2_a559_bucklHallRightUndef m7 : 28|1@1+ (1,0) [0|0] "" Vector__XXX
 SG_ RCM2_a633_comOCS1PMIA m8 : 28|1@1+ (1,0) [0|0] "" Vector__XXX
 SG_ RCM2_a693_comVCLEFT1rLSTPS m9 : 28|1@1+ (1,0) [0|0] "" Vector__XXX
 SG_ RCM2_a849_comIBSTparty1MIA m10 : 28|1@1+ (1,0) [0|0] "" Vector__XXX
 SG_ RCM2_a054_driverABStg1CrssCoup m0 : 29|1@1+ (1,0) [0|0] "" Vector__XXX
 SG_ RCM2_a114_loadLimRightCrssCoup m1 : 29|1@1+ (1,0) [0|0] "" Vector__XXX
 SG_ RCM2_a174_curAB2ndRowLCrssCoup m2 : 29|1@1+ (1,0) [0|0] "" Vector__XXX
 SG_ RCM2_a268_imuYawR8OffCompPosSLDC m3 : 29|1@1+ (1,0) [0|0] "" Vector__XXX
 SG_ RCM2_a354_upFrntSnsrLCommErr m4 : 29|1@1+ (1,0) [0|0] "" Vector__XXX
 SG_ RCM2_a421_sideAccelCPilRSht2Bat m5 : 29|1@1+ (1,0) [0|0] "" Vector__XXX
 SG_ RCM2_a484_upFrntPedProRCommErr m6 : 29|1@1+ (1,0) [0|0] "" Vector__XXX
 SG_ RCM2_a560_bucklHallRightCrssCoup m7 : 29|1@1+ (1,0) [0|0] "" Vector__XXX
 SG_ RCM2_a634_comOCS1PChkSm m8 : 29|1@1+ (1,0) [0|0] "" Vector__XXX
 SG_ RCM2_a694_comVCRIGHTrestMIA m9 : 29|1@1+ (1,0) [0|0] "" Vector__XXX
 SG_ RCM2_a850_comVCFRONTlightingMIA m10 : 29|1@1+ (1,0) [0|0] "" Vector__XXX
 SG_ RCM2_a055_driverABStg1Config m0 : 30|1@1+ (1,0) [0|0] "" Vector__XXX
 SG_ RCM2_a115_loadLimRightConfig m1 : 30|1@1+ (1,0) [0|0] "" Vector__XXX
 SG_ RCM2_a175_curAB2ndRowLConfig m2 : 30|1@1+ (1,0) [0|0] "" Vector__XXX
 SG_ RCM2_a269_imuYawR8OffCompNegSLDC m3 : 30|1@1+ (1,0) [0|0] "" Vector__XXX
 SG_ RCM2_a355_upFrntSnsrLInitTyp m4 : 30|1@1+ (1,0) [0|0] "" Vector__XXX
 SG_ RCM2_a422_sideAccelCPilROpen m5 : 30|1@1+ (1,0) [0|0] "" Vector__XXX
 SG_ RCM2_a485_upFrntPedProRIntTyp m6 : 30|1@1+ (1,0) [0|0] "" Vector__XXX
 SG_ RCM2_a561_bucklHallRightConfig m7 : 30|1@1+ (1,0) [0|0] "" Vector__XXX
 SG_ RCM2_a635_comOCS1PCntr m8 : 30|1@1+ (1,0) [0|0] "" Vector__XXX
 SG_ RCM2_a695_comVCRIGHTrestChkSm m9 : 30|1@1+ (1,0) [0|0] "" Vector__XXX
 SG_ RCM2_a851_internalFaultTemp m10 : 30|1@1+ (1,0) [0|0] "" Vector__XXX
 SG_ RCM2_a056_driverABStg2Sht2Gnd m0 : 31|1@1+ (1,0) [0|0] "" Vector__XXX
 SG_ RCM2_a116_kneeABDrvrSht2Gnd m1 : 31|1@1+ (1,0) [0|0] "" Vector__XXX
 SG_ RCM2_a176_curAB2ndRowRSht2Gnd m2 : 31|1@1+ (1,0) [0|0] "" Vector__XXX
 SG_ RCM2_a270_imuPtchR8OffCompPosLife m3 : 31|1@1+ (1,0) [0|0] "" Vector__XXX
 SG_ RCM2_a356_upFrntSnsrLConfig m4 : 31|1@1+ (1,0) [0|0] "" Vector__XXX
 SG_ RCM2_a423_sideAccelCPilRCrssCoup m5 : 31|1@1+ (1,0) [0|0] "" Vector__XXX
 SG_ RCM2_a486_upFrntPedProRConfig m6 : 31|1@1+ (1,0) [0|0] "" Vector__XXX
 SG_ RCM2_a562_seaTrkPosLeftSht2Gnd m7 : 31|1@1+ (1,0) [0|0] "" Vector__XXX
 SG_ RCM2_a636_ocsFaulted m8 : 31|1@1+ (1,0) [0|0] "" Vector__XXX
 SG_ RCM2_a696_comVCRIGHTrestCntr m9 : 31|1@1+ (1,0) [0|0] "" Vector__XXX
 SG_ RCM2_a852_autarkyEvent m10 : 31|1@1+ (1,0) [0|0] "" Vector__XXX
 SG_ RCM2_a057_driverABStg2Sht2Bat m0 : 32|1@1+ (1,0) [0|0] "" Vector__XXX
 SG_ RCM2_a117_kneeABDrvrSht2Bat m1 : 32|1@1+ (1,0) [0|0] "" Vector__XXX
 SG_ RCM2_a177_curAB2ndRowRSht2Bat m2 : 32|1@1+ (1,0) [0|0] "" Vector__XXX
 SG_ RCM2_a271_imuPtchR8OffCompNegLife m3 : 32|1@1+ (1,0) [0|0] "" Vector__XXX
 SG_ RCM2_a357_upFrntSnsrLDefect m4 : 32|1@1+ (1,0) [0|0] "" Vector__XXX
 SG_ RCM2_a424_sideAccelCPilRCommErr m5 : 32|1@1+ (1,0) [0|0] "" Vector__XXX
 SG_ RCM2_a487_upFrntPedProRDefect m6 : 32|1@1+ (1,0) [0|0] "" Vector__XXX
 SG_ RCM2_a563_seaTrkPosLeftShtBat m7 : 32|1@1+ (1,0) [0|0] "" Vector__XXX
 SG_ RCM2_a637_ocsUnknown m8 : 32|1@1+ (1,0) [0|0] "" Vector__XXX
 SG_ RCM2_a697_comVCRIGHT1rRBuckle m9 : 32|1@1+ (1,0) [0|0] "" Vector__XXX
 SG_ RCM2_a853_ConfigParametersInconsistent m10 : 32|1@1+ (1,0) [0|0] "" Vector__XXX
 SG_ RCM2_a058_driverABStg2Open m0 : 33|1@1+ (1,0) [0|0] "" Vector__XXX
 SG_ RCM2_a118_kneeABDrvrOpen m1 : 33|1@1+ (1,0) [0|0] "" Vector__XXX
 SG_ RCM2_a178_curAB2ndRowROpen m2 : 33|1@1+ (1,0) [0|0] "" Vector__XXX
 SG_ RCM2_a272_imuPtchR8OffCompPosFLDC m3 : 33|1@1+ (1,0) [0|0] "" Vector__XXX
 SG_ RCM2_a358_upFrntSnsrLSigMon m4 : 33|1@1+ (1,0) [0|0] "" Vector__XXX
 SG_ RCM2_a425_sideAccelCPilRInitTyp m5 : 33|1@1+ (1,0) [0|0] "" Vector__XXX
 SG_ RCM2_a488_upFrntPedProRSigMon m6 : 33|1@1+ (1,0) [0|0] "" Vector__XXX
 SG_ RCM2_a564_seaTrkPosLeftOpen m7 : 33|1@1+ (1,0) [0|0] "" Vector__XXX
 SG_ RCM2_a638_comGTWodoMIA m8 : 33|1@1+ (1,0) [0|0] "" Vector__XXX
 SG_ RCM2_a698_comVCRIGHT2rRBuckle m9 : 33|1@1+ (1,0) [0|0] "" Vector__XXX
 SG_ RCM2_a854_ConfigParametersNotLearned m10 : 33|1@1+ (1,0) [0|0] "" Vector__XXX
 SG_ RCM2_a059_driverABStg2Short m0 : 34|1@1+ (1,0) [0|0] "" Vector__XXX
 SG_ RCM2_a119_kneeABDrvrShort m1 : 34|1@1+ (1,0) [0|0] "" Vector__XXX
 SG_ RCM2_a179_curAB2ndRowRShort m2 : 34|1@1+ (1,0) [0|0] "" Vector__XXX
 SG_ RCM2_a273_imuPtchR8OffCompNegFLDC m3 : 34|1@1+ (1,0) [0|0] "" Vector__XXX
 SG_ RCM2_a360_upFrntSnsrRSht2Gnd m4 : 34|1@1+ (1,0) [0|0] "" Vector__XXX
 SG_ RCM2_a426_sideAccelCPilRConfig m5 : 34|1@1+ (1,0) [0|0] "" Vector__XXX
 SG_ RCM2_a490_presRearLDoorSht2Gnd m6 : 34|1@1+ (1,0) [0|0] "" Vector__XXX
 SG_ RCM2_a565_seaTrkPosLeftUndefined m7 : 34|1@1+ (1,0) [0|0] "" Vector__XXX
 SG_ RCM2_a639_comGTWCarStateMIA m8 : 34|1@1+ (1,0) [0|0] "" Vector__XXX
 SG_ RCM2_a699_comVCRIGHTocs m9 : 34|1@1+ (1,0) [0|0] "" Vector__XXX
 SG_ RCM2_a857_comVCLEFT2rCBuckle m10 : 34|1@1+ (1,0) [0|0] "" Vector__XXX
 SG_ RCM2_a060_driverABStg2CrssCoup m0 : 35|1@1+ (1,0) [0|0] "" Vector__XXX
 SG_ RCM2_a120_kneeABDrvrCrssCoup m1 : 35|1@1+ (1,0) [0|0] "" Vector__XXX
 SG_ RCM2_a180_curAB2ndRowRCrssCoup m2 : 35|1@1+ (1,0) [0|0] "" Vector__XXX
 SG_ RCM2_a274_imuPtchR8OffCompPosSLDC m3 : 35|1@1+ (1,0) [0|0] "" Vector__XXX
 SG_ RCM2_a361_upFrntSnsrRSht2Bat m4 : 35|1@1+ (1,0) [0|0] "" Vector__XXX
 SG_ RCM2_a427_sideAccelCPilRDefect m5 : 35|1@1+ (1,0) [0|0] "" Vector__XXX
 SG_ RCM2_a491_presRearLDoorSht2Bat m6 : 35|1@1+ (1,0) [0|0] "" Vector__XXX
 SG_ RCM2_a566_seaTrkPosLeftCrssCoup m7 : 35|1@1+ (1,0) [0|0] "" Vector__XXX
 SG_ RCM2_a640_comTPMSStatusCMIA m8 : 35|1@1+ (1,0) [0|0] "" Vector__XXX
 SG_ RCM2_a700_comVCRIGHT1rRSTPS m9 : 35|1@1+ (1,0) [0|0] "" Vector__XXX
 SG_ RCM2_a858_comVCxLVPowerStateMIA m10 : 35|1@1+ (1,0) [0|0] "" Vector__XXX
 SG_ RCM2_a061_driverABStg2Config m0 : 36|1@1+ (1,0) [0|0] "" Vector__XXX
 SG_ RCM2_a121_kneeABDrvrConfig m1 : 36|1@1+ (1,0) [0|0] "" Vector__XXX
 SG_ RCM2_a181_curAB2ndRowRConfig m2 : 36|1@1+ (1,0) [0|0] "" Vector__XXX
 SG_ RCM2_a275_imuPtchR8OffCompNegSLDC m3 : 36|1@1+ (1,0) [0|0] "" Vector__XXX
 SG_ RCM2_a362_upFrntSnsrROpen m4 : 36|1@1+ (1,0) [0|0] "" Vector__XXX
 SG_ RCM2_a428_sideAccelCPilRSigMon m5 : 36|1@1+ (1,0) [0|0] "" Vector__XXX
 SG_ RCM2_a492_presRearLDoorOpen m6 : 36|1@1+ (1,0) [0|0] "" Vector__XXX
 SG_ RCM2_a567_seaTrkPosLeftConfig m7 : 36|1@1+ (1,0) [0|0] "" Vector__XXX
 SG_ RCM2_a641_comGTWCarConfigMIA m8 : 36|1@1+ (1,0) [0|0] "" Vector__XXX
 SG_ RCM2_a701_comVCSECtpmsStatusMIA m9 : 36|1@1+ (1,0) [0|0] "" Vector__XXX
 SG_ RCM2_a859_comVCxLVPowerStateChkSm m10 : 36|1@1+ (1,0) [0|0] "" Vector__XXX
 SG_ RCM2_a062_passABStg1Sht2Gnd m0 : 37|1@1+ (1,0) [0|0] "" Vector__XXX
 SG_ RCM2_a122_kneeABPassSht2Gnd m1 : 37|1@1+ (1,0) [0|0] "" Vector__XXX
 SG_ RCM2_a182_hoodActuatorRSht2Gnd m2 : 37|1@1+ (1,0) [0|0] "" Vector__XXX
 SG_ RCM2_a276_imuRollR8OffCompPosLife m3 : 37|1@1+ (1,0) [0|0] "" Vector__XXX
 SG_ RCM2_a363_upFrntSnsrRCrssCoup m4 : 37|1@1+ (1,0) [0|0] "" Vector__XXX
 SG_ RCM2_a430_presFrntLDoorSht2Gnd m5 : 37|1@1+ (1,0) [0|0] "" Vector__XXX
 SG_ RCM2_a493_presRearLDoorCrssCoup m6 : 37|1@1+ (1,0) [0|0] "" Vector__XXX
 SG_ RCM2_a568_occPROSSht2Gnd m7 : 37|1@1+ (1,0) [0|0] "" Vector__XXX
 SG_ RCM2_a642_comVINmessageMIA m8 : 37|1@1+ (1,0) [0|0] "" Vector__XXX
 SG_ RCM2_a750_linInternalTimeout m9 : 37|1@1+ (1,0) [0|0] "" Vector__XXX
 SG_ RCM2_a860_comVCxLVPowerStateCntr m10 : 37|1@1+ (1,0) [0|0] "" Vector__XXX
 SG_ RCM2_a063_passABStg1Sht2Bat m0 : 38|1@1+ (1,0) [0|0] "" Vector__XXX
 SG_ RCM2_a123_kneeABPassSht2Bat m1 : 38|1@1+ (1,0) [0|0] "" Vector__XXX
 SG_ RCM2_a183_hoodActuatorRSht2Bat m2 : 38|1@1+ (1,0) [0|0] "" Vector__XXX
 SG_ RCM2_a277_imuRollR8OffCompNegLife m3 : 38|1@1+ (1,0) [0|0] "" Vector__XXX
 SG_ RCM2_a364_upFrntSnsrRCommErr m4 : 38|1@1+ (1,0) [0|0] "" Vector__XXX
 SG_ RCM2_a431_presFrntLDoorSht2Bat m5 : 38|1@1+ (1,0) [0|0] "" Vector__XXX
 SG_ RCM2_a494_presRearLDoorCommErr m6 : 38|1@1+ (1,0) [0|0] "" Vector__XXX
 SG_ RCM2_a569_occPROSSht2Bat m7 : 38|1@1+ (1,0) [0|0] "" Vector__XXX
 SG_ RCM2_a643_comDASSafetyFrntMIA m8 : 38|1@1+ (1,0) [0|0] "" Vector__XXX
 SG_ RCM2_a799_internalFault m9 : 38|1@1+ (1,0) [0|0] "" Vector__XXX
 SG_ RCM2_a861_typeApprovalStringNotLearned m10 : 38|1@1+ (1,0) [0|0] "" Vector__XXX
 SG_ RCM2_a064_passABStg1Open m0 : 39|1@1+ (1,0) [0|0] "" Vector__XXX
 SG_ RCM2_a124_kneeABPassOpen m1 : 39|1@1+ (1,0) [0|0] "" Vector__XXX
 SG_ RCM2_a184_hoodActuatorROpen m2 : 39|1@1+ (1,0) [0|0] "" Vector__XXX
 SG_ RCM2_a278_imuRollR8OffCompPosFLDC m3 : 39|1@1+ (1,0) [0|0] "" Vector__XXX
 SG_ RCM2_a365_upFrntSnsrRInitTyp m4 : 39|1@1+ (1,0) [0|0] "" Vector__XXX
 SG_ RCM2_a432_presFrntLDoorOpen m5 : 39|1@1+ (1,0) [0|0] "" Vector__XXX
 SG_ RCM2_a495_presRearLDoorInitTyp m6 : 39|1@1+ (1,0) [0|0] "" Vector__XXX
 SG_ RCM2_a570_occPROSOpen m7 : 39|1@1+ (1,0) [0|0] "" Vector__XXX
 SG_ RCM2_a644_comDASSafetyFrntChkSm m8 : 39|1@1+ (1,0) [0|0] "" Vector__XXX
 SG_ RCM2_a800_crcFault m9 : 39|1@1+ (1,0) [0|0] "" Vector__XXX
 SG_ RCM2_a862_comPCSalertMatrixMIA m10 : 39|1@1+ (1,0) [0|0] "" Vector__XXX
 SG_ RCM2_a065_passABStg1Short m0 : 40|1@1+ (1,0) [0|0] "" Vector__XXX
 SG_ RCM2_a125_kneeABPassShort m1 : 40|1@1+ (1,0) [0|0] "" Vector__XXX
 SG_ RCM2_a185_hoodActuatorRShort m2 : 40|1@1+ (1,0) [0|0] "" Vector__XXX
 SG_ RCM2_a279_imuRollR8OffCompNegFLDC m3 : 40|1@1+ (1,0) [0|0] "" Vector__XXX
 SG_ RCM2_a366_upFrntSnsrRConfig m4 : 40|1@1+ (1,0) [0|0] "" Vector__XXX
 SG_ RCM2_a433_presFrntLDoorCrssCoup m5 : 40|1@1+ (1,0) [0|0] "" Vector__XXX
 SG_ RCM2_a496_presRearLDoorConfig m6 : 40|1@1+ (1,0) [0|0] "" Vector__XXX
 SG_ RCM2_a571_occPROSUndef m7 : 40|1@1+ (1,0) [0|0] "" Vector__XXX
 SG_ RCM2_a645_comDASSafetyFrntCntr m8 : 40|1@1+ (1,0) [0|0] "" Vector__XXX
 SG_ RCM2_a801_parameterLayoutID m9 : 40|1@1+ (1,0) [0|0] "" Vector__XXX
 SG_ RCM2_a863_comVCFRONTalertMatrixMIA m10 : 40|1@1+ (1,0) [0|0] "" Vector__XXX
 SG_ RCM2_a066_passABStg1CrssCoup m0 : 41|1@1+ (1,0) [0|0] "" Vector__XXX
 SG_ RCM2_a126_kneeABPassCrssCoup m1 : 41|1@1+ (1,0) [0|0] "" Vector__XXX
 SG_ RCM2_a186_hoodActuatorRCrssCoup m2 : 41|1@1+ (1,0) [0|0] "" Vector__XXX
 SG_ RCM2_a280_imuRollR8OffCompPosSLDC m3 : 41|1@1+ (1,0) [0|0] "" Vector__XXX
 SG_ RCM2_a367_upFrntSnsrRDefect m4 : 41|1@1+ (1,0) [0|0] "" Vector__XXX
 SG_ RCM2_a434_presFrntLDoorCommErr m5 : 41|1@1+ (1,0) [0|0] "" Vector__XXX
 SG_ RCM2_a497_presRearLDoorDefect m6 : 41|1@1+ (1,0) [0|0] "" Vector__XXX
 SG_ RCM2_a572_occPROSCrssCoup m7 : 41|1@1+ (1,0) [0|0] "" Vector__XXX
 SG_ RCM2_a646_comDIstateMIA m8 : 41|1@1+ (1,0) [0|0] "" Vector__XXX
 SG_ RCM2_a802_parameterTransferID m9 : 41|1@1+ (1,0) [0|0] "" Vector__XXX
 SG_ RCM2_a864_comGTWepochTimeMIA m10 : 41|1@1+ (1,0) [0|0] "" Vector__XXX
 SG_ RCM2_a067_passABStg1Config m0 : 42|1@1+ (1,0) [0|0] "" Vector__XXX
 SG_ RCM2_a127_kneeABPassConfig m1 : 42|1@1+ (1,0) [0|0] "" Vector__XXX
 SG_ RCM2_a187_hoodActuatorRConfig m2 : 42|1@1+ (1,0) [0|0] "" Vector__XXX
 SG_ RCM2_a281_imuRollR8OffCompNegSLDC m3 : 42|1@1+ (1,0) [0|0] "" Vector__XXX
 SG_ RCM2_a368_upFrntSnsrRSigMon m4 : 42|1@1+ (1,0) [0|0] "" Vector__XXX
 SG_ RCM2_a435_presFrntLDoorInitTyp m5 : 42|1@1+ (1,0) [0|0] "" Vector__XXX
 SG_ RCM2_a498_presRearLDoorSigMon m6 : 42|1@1+ (1,0) [0|0] "" Vector__XXX
 SG_ RCM2_a573_occPROSConfig m7 : 42|1@1+ (1,0) [0|0] "" Vector__XXX
 SG_ RCM2_a647_comDIstateChkSm m8 : 42|1@1+ (1,0) [0|0] "" Vector__XXX
 SG_ RCM2_a803_algoVerifySensorID m9 : 42|1@1+ (1,0) [0|0] "" Vector__XXX
 SG_ RCM2_a865_comVCLVBMSstatusHighMIA m10 : 42|1@1+ (1,0) [0|0] "" Vector__XXX
 SG_ RCM2_a068_passABStg2Sht2Gnd m0 : 43|1@1+ (1,0) [0|0] "" Vector__XXX
 SG_ RCM2_a128_sideAB1stRowLSht2Gnd m1 : 43|1@1+ (1,0) [0|0] "" Vector__XXX
 SG_ RCM2_a188_hoodActuatorLSht2Gnd m2 : 43|1@1+ (1,0) [0|0] "" Vector__XXX
 SG_ RCM2_a282_imuLongAOffCompPosLife m3 : 43|1@1+ (1,0) [0|0] "" Vector__XXX
 SG_ RCM2_a370_upFrntSnsrMidLSht2Gnd m4 : 43|1@1+ (1,0) [0|0] "" Vector__XXX
 SG_ RCM2_a436_presFrntLDoorConfig m5 : 43|1@1+ (1,0) [0|0] "" Vector__XXX
 SG_ RCM2_a500_presRearRDoorSht2Gnd m6 : 43|1@1+ (1,0) [0|0] "" Vector__XXX
 SG_ RCM2_a587_sbrRearNetworkSht2Gnd m7 : 43|1@1+ (1,0) [0|0] "" Vector__XXX
 SG_ RCM2_a648_comDIstateCntr m8 : 43|1@1+ (1,0) [0|0] "" Vector__XXX
 SG_ RCM2_a804_configDataInconsistent m9 : 43|1@1+ (1,0) [0|0] "" Vector__XXX
 SG_ RCM2_a866_comDASstatusMIA m10 : 43|1@1+ (1,0) [0|0] "" Vector__XXX
 SG_ RCM2_a069_passABStg2Sht2Bat m0 : 44|1@1+ (1,0) [0|0] "" Vector__XXX
 SG_ RCM2_a129_sideAB1stRowLSht2Bat m1 : 44|1@1+ (1,0) [0|0] "" Vector__XXX
 SG_ RCM2_a189_hoodActuatorLSht2Bat m2 : 44|1@1+ (1,0) [0|0] "" Vector__XXX
 SG_ RCM2_a283_imuLongAOffCompNegLife m3 : 44|1@1+ (1,0) [0|0] "" Vector__XXX
 SG_ RCM2_a371_upFrntSnsrMidLSht2Bat m4 : 44|1@1+ (1,0) [0|0] "" Vector__XXX
 SG_ RCM2_a437_presFrntLDoorDefect m5 : 44|1@1+ (1,0) [0|0] "" Vector__XXX
 SG_ RCM2_a501_presRearRDoorSht2Bat m6 : 44|1@1+ (1,0) [0|0] "" Vector__XXX
 SG_ RCM2_a588_sbrRearNetworkSht2Bat m7 : 44|1@1+ (1,0) [0|0] "" Vector__XXX
 SG_ RCM2_a649_comDIstate2MIA m8 : 44|1@1+ (1,0) [0|0] "" Vector__XXX
 SG_ RCM2_a805_swVersionWrong m9 : 44|1@1+ (1,0) [0|0] "" Vector__XXX
 SG_ RCM2_a868_headAB3rdRowRSht2Gnd m10 : 44|1@1+ (1,0) [0|0] "" Vector__XXX
 SG_ RCM2_a070_passABStg2Open m0 : 45|1@1+ (1,0) [0|0] "" Vector__XXX
 SG_ RCM2_a130_sideAB1stRowLOpen m1 : 45|1@1+ (1,0) [0|0] "" Vector__XXX
 SG_ RCM2_a190_hoodActuatorLOpen m2 : 45|1@1+ (1,0) [0|0] "" Vector__XXX
 SG_ RCM2_a284_imuLongAOffCompPosFLDC m3 : 45|1@1+ (1,0) [0|0] "" Vector__XXX
 SG_ RCM2_a372_upFrntSnsrMidLOpen m4 : 45|1@1+ (1,0) [0|0] "" Vector__XXX
 SG_ RCM2_a438_presFrntLDoorSigMon m5 : 45|1@1+ (1,0) [0|0] "" Vector__XXX
 SG_ RCM2_a502_presRearRDoorOpen m6 : 45|1@1+ (1,0) [0|0] "" Vector__XXX
 SG_ RCM2_a589_sbrRearNetworkOpen m7 : 45|1@1+ (1,0) [0|0] "" Vector__XXX
 SG_ RCM2_a650_comDIstate2ChkSm m8 : 45|1@1+ (1,0) [0|0] "" Vector__XXX
 SG_ RCM2_a806_configVINnotLearned m9 : 45|1@1+ (1,0) [0|0] "" Vector__XXX
 SG_ RCM2_a869_headAB3rdRowRSht2Bat m10 : 45|1@1+ (1,0) [0|0] "" Vector__XXX
 SG_ RCM2_a071_passABStg2Short m0 : 46|1@1+ (1,0) [0|0] "" Vector__XXX
 SG_ RCM2_a131_sideAB1stRowLShort m1 : 46|1@1+ (1,0) [0|0] "" Vector__XXX
 SG_ RCM2_a191_hoodActuatorLShort m2 : 46|1@1+ (1,0) [0|0] "" Vector__XXX
 SG_ RCM2_a285_imuLongAOffCompNegFLDC m3 : 46|1@1+ (1,0) [0|0] "" Vector__XXX
 SG_ RCM2_a373_upFrntSnsrMidLCrssCoup m4 : 46|1@1+ (1,0) [0|0] "" Vector__XXX
 SG_ RCM2_a439_presDoorAbsolute1 m5 : 46|1@1+ (1,0) [0|0] "" Vector__XXX
 SG_ RCM2_a503_presRearRDoorCrssCoup m6 : 46|1@1+ (1,0) [0|0] "" Vector__XXX
 SG_ RCM2_a590_sbrRearNetworkUndefined m7 : 46|1@1+ (1,0) [0|0] "" Vector__XXX
 SG_ RCM2_a651_comDIstate2Cntr m8 : 46|1@1+ (1,0) [0|0] "" Vector__XXX
 SG_ RCM2_a807_configVINmismatch m9 : 46|1@1+ (1,0) [0|0] "" Vector__XXX
 SG_ RCM2_a870_headAB3rdRowROpen m10 : 46|1@1+ (1,0) [0|0] "" Vector__XXX
 SG_ RCM2_a072_passABStg2CrssCoup m0 : 47|1@1+ (1,0) [0|0] "" Vector__XXX
 SG_ RCM2_a132_sideAB1stRowLCrssCoup m1 : 47|1@1+ (1,0) [0|0] "" Vector__XXX
 SG_ RCM2_a192_hoodActuatorLCrssCoup m2 : 47|1@1+ (1,0) [0|0] "" Vector__XXX
 SG_ RCM2_a286_imuLongAOffCompPosSLDC m3 : 47|1@1+ (1,0) [0|0] "" Vector__XXX
 SG_ RCM2_a374_upFrntSnsrMidLCommErr m4 : 47|1@1+ (1,0) [0|0] "" Vector__XXX
 SG_ RCM2_a440_presFrntRDoorSht2Gnd m5 : 47|1@1+ (1,0) [0|0] "" Vector__XXX
 SG_ RCM2_a504_presRearRDoorCommErr m6 : 47|1@1+ (1,0) [0|0] "" Vector__XXX
 SG_ RCM2_a591_sbrRearNetworkCrssCoup m7 : 47|1@1+ (1,0) [0|0] "" Vector__XXX
 SG_ RCM2_a652_ambientTempFaulted m8 : 47|1@1+ (1,0) [0|0] "" Vector__XXX
 SG_ RCM2_a808_configDriveNotLearned m9 : 47|1@1+ (1,0) [0|0] "" Vector__XXX
 SG_ RCM2_a871_headAB3rdRowRShort m10 : 47|1@1+ (1,0) [0|0] "" Vector__XXX
 SG_ RCM2_a073_passABStg2Config m0 : 48|1@1+ (1,0) [0|0] "" Vector__XXX
 SG_ RCM2_a133_sideAB1stRowLConfig m1 : 48|1@1+ (1,0) [0|0] "" Vector__XXX
 SG_ RCM2_a193_hoodActuatorLConfig m2 : 48|1@1+ (1,0) [0|0] "" Vector__XXX
 SG_ RCM2_a287_imuLongAOffCompNegSLDC m3 : 48|1@1+ (1,0) [0|0] "" Vector__XXX
 SG_ RCM2_a375_upFrntSnsrMidLInitTyp m4 : 48|1@1+ (1,0) [0|0] "" Vector__XXX
 SG_ RCM2_a441_presFrntRDoorSht2Bat m5 : 48|1@1+ (1,0) [0|0] "" Vector__XXX
 SG_ RCM2_a505_presRearRDoorInitTyp m6 : 48|1@1+ (1,0) [0|0] "" Vector__XXX
 SG_ RCM2_a592_sbrRearNetworkConfig m7 : 48|1@1+ (1,0) [0|0] "" Vector__XXX
 SG_ RCM2_a653_comGTWESP1MIA m8 : 48|1@1+ (1,0) [0|0] "" Vector__XXX
 SG_ RCM2_a809_configDriveMismatch m9 : 48|1@1+ (1,0) [0|0] "" Vector__XXX
 SG_ RCM2_a872_headAB3rdRowRCrossC m10 : 48|1@1+ (1,0) [0|0] "" Vector__XXX
 SG_ RCM2_a074_passActiveVentSht2Gnd m0 : 49|1@1+ (1,0) [0|0] "" Vector__XXX
 SG_ RCM2_a134_sideAB1stRowRSht2Gnd m1 : 49|1@1+ (1,0) [0|0] "" Vector__XXX
 SG_ RCM2_a194_driverABAVSht2Gnd m2 : 49|1@1+ (1,0) [0|0] "" Vector__XXX
 SG_ RCM2_a288_imuLatAcOffCompPosLife m3 : 49|1@1+ (1,0) [0|0] "" Vector__XXX
 SG_ RCM2_a376_upFrntSnsrMidLConfig m4 : 49|1@1+ (1,0) [0|0] "" Vector__XXX
 SG_ RCM2_a442_presFrntRDoorOpen m5 : 49|1@1+ (1,0) [0|0] "" Vector__XXX
 SG_ RCM2_a506_presRearRDoorConfig m6 : 49|1@1+ (1,0) [0|0] "" Vector__XXX
 SG_ RCM2_a593_driveOrientationSht2Gnd m7 : 49|1@1+ (1,0) [0|0] "" Vector__XXX
 SG_ RCM2_a654_comGTWESP1ChkSm m8 : 49|1@1+ (1,0) [0|0] "" Vector__XXX
 SG_ RCM2_a810_bootUpActionFailure m9 : 49|1@1+ (1,0) [0|0] "" Vector__XXX
 SG_ RCM2_a873_headAB3rdRowRConfig m10 : 49|1@1+ (1,0) [0|0] "" Vector__XXX
 SG_ RCM2_a075_passActiveVentSht2Bat m0 : 50|1@1+ (1,0) [0|0] "" Vector__XXX
 SG_ RCM2_a135_sideAB1stRowRSht2Bat m1 : 50|1@1+ (1,0) [0|0] "" Vector__XXX
 SG_ RCM2_a195_driverABAVSht2Bat m2 : 50|1@1+ (1,0) [0|0] "" Vector__XXX
 SG_ RCM2_a289_imuLatAcOffCompNegLife m3 : 50|1@1+ (1,0) [0|0] "" Vector__XXX
 SG_ RCM2_a377_upFrntSnsrMidLDefect m4 : 50|1@1+ (1,0) [0|0] "" Vector__XXX
 SG_ RCM2_a443_presFrntRDoorCrssCoup m5 : 50|1@1+ (1,0) [0|0] "" Vector__XXX
 SG_ RCM2_a507_presRearRDoorDefect m6 : 50|1@1+ (1,0) [0|0] "" Vector__XXX
 SG_ RCM2_a594_driveOrientationSht2Bat m7 : 50|1@1+ (1,0) [0|0] "" Vector__XXX
 SG_ RCM2_a655_comGTWESP1Cntr m8 : 50|1@1+ (1,0) [0|0] "" Vector__XXX
 SG_ RCM2_a811_comAxleSpeed m9 : 50|1@1+ (1,0) [0|0] "" Vector__XXX
 SG_ RCM2_a874_headAB3rdRowLSht2Gnd m10 : 50|1@1+ (1,0) [0|0] "" Vector__XXX
 SG_ RCM2_a076_passActiveVentOpen m0 : 51|1@1+ (1,0) [0|0] "" Vector__XXX
 SG_ RCM2_a136_sideAB1stRowROpen m1 : 51|1@1+ (1,0) [0|0] "" Vector__XXX
 SG_ RCM2_a196_driverABAVOpen m2 : 51|1@1+ (1,0) [0|0] "" Vector__XXX
 SG_ RCM2_a290_imuLatAcOffCompPosFLDC m3 : 51|1@1+ (1,0) [0|0] "" Vector__XXX
 SG_ RCM2_a378_upFrntSnsrMidLSigMon m4 : 51|1@1+ (1,0) [0|0] "" Vector__XXX
 SG_ RCM2_a444_presFrntRDoorCommErr m5 : 51|1@1+ (1,0) [0|0] "" Vector__XXX
 SG_ RCM2_a508_presRearRDoorSigMon m6 : 51|1@1+ (1,0) [0|0] "" Vector__XXX
 SG_ RCM2_a595_driveOrientationOpen m7 : 51|1@1+ (1,0) [0|0] "" Vector__XXX
 SG_ RCM2_a656_comVCSEATPrestMIA m8 : 51|1@1+ (1,0) [0|0] "" Vector__XXX
 SG_ RCM2_a812_idfMisuseMonitoringErr m9 : 51|1@1+ (1,0) [0|0] "" Vector__XXX
 SG_ RCM2_a875_headAB3rdRowLSht2Bat m10 : 51|1@1+ (1,0) [0|0] "" Vector__XXX
 SG_ RCM2_a077_passActiveVentShort m0 : 52|1@1+ (1,0) [0|0] "" Vector__XXX
 SG_ RCM2_a137_sideAB1stRowRShort m1 : 52|1@1+ (1,0) [0|0] "" Vector__XXX
 SG_ RCM2_a197_driverABAVShort m2 : 52|1@1+ (1,0) [0|0] "" Vector__XXX
 SG_ RCM2_a291_imuLatAcOffCompNegFLDC m3 : 52|1@1+ (1,0) [0|0] "" Vector__XXX
 SG_ RCM2_a380_upFrntSnsrMidRSht2Gnd m4 : 52|1@1+ (1,0) [0|0] "" Vector__XXX
 SG_ RCM2_a445_presFrntRDoorInitTyp m5 : 52|1@1+ (1,0) [0|0] "" Vector__XXX
 SG_ RCM2_a509_sideAccelDPilLSht2Gnd m6 : 52|1@1+ (1,0) [0|0] "" Vector__XXX
 SG_ RCM2_a596_driveOrientationUndefined m7 : 52|1@1+ (1,0) [0|0] "" Vector__XXX
 SG_ RCM2_a657_comVCSEATPrestChkSm m8 : 52|1@1+ (1,0) [0|0] "" Vector__XXX
 SG_ RCM2_a813_idfEnviMonitoringError m9 : 52|1@1+ (1,0) [0|0] "" Vector__XXX
 SG_ RCM2_a876_headAB3rdRowLOpen m10 : 52|1@1+ (1,0) [0|0] "" Vector__XXX
 SG_ RCM2_a078_passActiveVentCrssCoup m0 : 53|1@1+ (1,0) [0|0] "" Vector__XXX
 SG_ RCM2_a138_sideAB1stRowRCrssCoup m1 : 53|1@1+ (1,0) [0|0] "" Vector__XXX
 SG_ RCM2_a198_driverABAVCrossCoup m2 : 53|1@1+ (1,0) [0|0] "" Vector__XXX
 SG_ RCM2_a292_imuLatAcOffCompPosSLDC m3 : 53|1@1+ (1,0) [0|0] "" Vector__XXX
 SG_ RCM2_a381_upFrntSnsrMidRSht2Bat m4 : 53|1@1+ (1,0) [0|0] "" Vector__XXX
 SG_ RCM2_a446_presFrntRDoorConfig m5 : 53|1@1+ (1,0) [0|0] "" Vector__XXX
 SG_ RCM2_a510_sideAccelDPilLSht2Bat m6 : 53|1@1+ (1,0) [0|0] "" Vector__XXX
 SG_ RCM2_a597_driveOrientationCrssCoup m7 : 53|1@1+ (1,0) [0|0] "" Vector__XXX
 SG_ RCM2_a658_comVCSEATPrestCntr m8 : 53|1@1+ (1,0) [0|0] "" Vector__XXX
 SG_ RCM2_a814_idfEnviMonitoringEvent m9 : 53|1@1+ (1,0) [0|0] "" Vector__XXX
 SG_ RCM2_a877_headAB3rdRowLShort m10 : 53|1@1+ (1,0) [0|0] "" Vector__XXX
 SG_ RCM2_a079_passActiveVentConfig m0 : 54|1@1+ (1,0) [0|0] "" Vector__XXX
 SG_ RCM2_a139_sideAB1stRowRConfig m1 : 54|1@1+ (1,0) [0|0] "" Vector__XXX
 SG_ RCM2_a199_driverABAVConfig m2 : 54|1@1+ (1,0) [0|0] "" Vector__XXX
 SG_ RCM2_a293_imuLatAcOffCompNegSLDC m3 : 54|1@1+ (1,0) [0|0] "" Vector__XXX
 SG_ RCM2_a382_upFrntSnsrMidROpen m4 : 54|1@1+ (1,0) [0|0] "" Vector__XXX
 SG_ RCM2_a447_presFrntRDoorDefect m5 : 54|1@1+ (1,0) [0|0] "" Vector__XXX
 SG_ RCM2_a511_sideAccelDPilLOpen m6 : 54|1@1+ (1,0) [0|0] "" Vector__XXX
 SG_ RCM2_a598_driveOrientationConfig m7 : 54|1@1+ (1,0) [0|0] "" Vector__XXX
 SG_ RCM2_a659_comVCSEATPbuckle m8 : 54|1@1+ (1,0) [0|0] "" Vector__XXX
 SG_ RCM2_a815_upFrntPedProMLSht2Gnd m9 : 54|1@1+ (1,0) [0|0] "" Vector__XXX
 SG_ RCM2_a878_headAB3rdRowLCrossC m10 : 54|1@1+ (1,0) [0|0] "" Vector__XXX
 SG_ RCM2_a080_pretenShldLeftSht2Gnd m0 : 55|1@1+ (1,0) [0|0] "" Vector__XXX
 SG_ RCM2_a140_hvdPyroSht2Gnd m1 : 55|1@1+ (1,0) [0|0] "" Vector__XXX
 SG_ RCM2_a200_driverFSABSht2Gnd m2 : 55|1@1+ (1,0) [0|0] "" Vector__XXX
 SG_ RCM2_a294_imuVertAOffCompPosLife m3 : 55|1@1+ (1,0) [0|0] "" Vector__XXX
 SG_ RCM2_a383_upFrntSnsrMidRCrssCoup m4 : 55|1@1+ (1,0) [0|0] "" Vector__XXX
 SG_ RCM2_a448_presFrntRDoorSigMon m5 : 55|1@1+ (1,0) [0|0] "" Vector__XXX
 SG_ RCM2_a512_sideAccelDPilLCrssCoup m6 : 55|1@1+ (1,0) [0|0] "" Vector__XXX
 SG_ RCM2_a600_comCANinternalTimeout m7 : 55|1@1+ (1,0) [0|0] "" Vector__XXX
 SG_ RCM2_a660_comVCSEATPOccpy m8 : 55|1@1+ (1,0) [0|0] "" Vector__XXX
 SG_ RCM2_a816_upFrntPedProMLSht2Bat m9 : 55|1@1+ (1,0) [0|0] "" Vector__XXX
 SG_ RCM2_a879_headAB3rdRowLConfig m10 : 55|1@1+ (1,0) [0|0] "" Vector__XXX
 SG_ RCM2_a081_pretenShldLeftSht2Bat m0 : 56|1@1+ (1,0) [0|0] "" Vector__XXX
 SG_ RCM2_a141_hvdPyroSht2Bat m1 : 56|1@1+ (1,0) [0|0] "" Vector__XXX
 SG_ RCM2_a201_driverFSABSht2Bat m2 : 56|1@1+ (1,0) [0|0] "" Vector__XXX
 SG_ RCM2_a295_imuVertAOffCompNegLife m3 : 56|1@1+ (1,0) [0|0] "" Vector__XXX
 SG_ RCM2_a384_upFrntSnsrMidRCommErr m4 : 56|1@1+ (1,0) [0|0] "" Vector__XXX
 SG_ RCM2_a449_presDoorAbsolute2 m5 : 56|1@1+ (1,0) [0|0] "" Vector__XXX
 SG_ RCM2_a513_sideAccelDPilLCommErr m6 : 56|1@1+ (1,0) [0|0] "" Vector__XXX
 SG_ RCM2_a601_comChassisCANSilent m7 : 56|1@1+ (1,0) [0|0] "" Vector__XXX
 SG_ RCM2_a661_comVCSEATPocs m8 : 56|1@1+ (1,0) [0|0] "" Vector__XXX
 SG_ RCM2_a817_upFrntPedProMLOpen m9 : 56|1@1+ (1,0) [0|0] "" Vector__XXX
 SG_ RCM2_a880_comVCLEFT3rLBuckle m10 : 56|1@1+ (1,0) [0|0] "" Vector__XXX
 SG_ RCM2_a082_pretenShldLeftOpen m0 : 57|1@1+ (1,0) [0|0] "" Vector__XXX
 SG_ RCM2_a142_hvdPyroOpen m1 : 57|1@1+ (1,0) [0|0] "" Vector__XXX
 SG_ RCM2_a202_driverFSABOpen m2 : 57|1@1+ (1,0) [0|0] "" Vector__XXX
 SG_ RCM2_a296_imuVertAOffCompPosFLDC m3 : 57|1@1+ (1,0) [0|0] "" Vector__XXX
 SG_ RCM2_a385_upFrntSnsrMidRInitTyp m4 : 57|1@1+ (1,0) [0|0] "" Vector__XXX
 SG_ RCM2_a450_presPedProLSht2Gnd m5 : 57|1@1+ (1,0) [0|0] "" Vector__XXX
 SG_ RCM2_a514_sideAccelDPilLInitTyp m6 : 57|1@1+ (1,0) [0|0] "" Vector__XXX
 SG_ RCM2_a602_comChassisCANBusOff m7 : 57|1@1+ (1,0) [0|0] "" Vector__XXX
 SG_ RCM2_a662_comVCSEATPstps m8 : 57|1@1+ (1,0) [0|0] "" Vector__XXX
 SG_ RCM2_a818_upFrntPedProMLCrssCoup m9 : 57|1@1+ (1,0) [0|0] "" Vector__XXX
 SG_ RCM2_a881_comVCRIGHT3rRBuckle m10 : 57|1@1+ (1,0) [0|0] "" Vector__XXX
 SG_ RCM2_a083_pretenShldLeftShort m0 : 58|1@1+ (1,0) [0|0] "" Vector__XXX
 SG_ RCM2_a143_hvdPyroShort m1 : 58|1@1+ (1,0) [0|0] "" Vector__XXX
 SG_ RCM2_a203_driverFSABShort m2 : 58|1@1+ (1,0) [0|0] "" Vector__XXX
 SG_ RCM2_a297_imuVertAOffCompNegFLDC m3 : 58|1@1+ (1,0) [0|0] "" Vector__XXX
 SG_ RCM2_a386_upFrntSnsrMidRConfig m4 : 58|1@1+ (1,0) [0|0] "" Vector__XXX
 SG_ RCM2_a451_presPedProLSht2Bat m5 : 58|1@1+ (1,0) [0|0] "" Vector__XXX
 SG_ RCM2_a515_sideAccelDPilLConfig m6 : 58|1@1+ (1,0) [0|0] "" Vector__XXX
 SG_ RCM2_a603_comPARTYCANSilent m7 : 58|1@1+ (1,0) [0|0] "" Vector__XXX
 SG_ RCM2_a663_comVCSEATDrestMIA m8 : 58|1@1+ (1,0) [0|0] "" Vector__XXX
 SG_ RCM2_a819_upFrntPedProMLCommErr m9 : 58|1@1+ (1,0) [0|0] "" Vector__XXX
 SG_ RCM2_a084_pretenShldLeftCrossC m0 : 59|1@1+ (1,0) [0|0] "" Vector__XXX
 SG_ RCM2_a144_hvdPyroCrssCoup m1 : 59|1@1+ (1,0) [0|0] "" Vector__XXX
 SG_ RCM2_a204_driverFSABCrossCoup m2 : 59|1@1+ (1,0) [0|0] "" Vector__XXX
 SG_ RCM2_a298_imuVertAOffCompPosSLDC m3 : 59|1@1+ (1,0) [0|0] "" Vector__XXX
 SG_ RCM2_a387_upFrntSnsrMidRDefect m4 : 59|1@1+ (1,0) [0|0] "" Vector__XXX
 SG_ RCM2_a452_presPedProLOpen m5 : 59|1@1+ (1,0) [0|0] "" Vector__XXX
 SG_ RCM2_a516_sideAccelDPilLDefect m6 : 59|1@1+ (1,0) [0|0] "" Vector__XXX
 SG_ RCM2_a604_comPARTYCANBusOff m7 : 59|1@1+ (1,0) [0|0] "" Vector__XXX
 SG_ RCM2_a664_comVCSEATDrestChkSm m8 : 59|1@1+ (1,0) [0|0] "" Vector__XXX
 SG_ RCM2_a820_upFrntPedProMLIntTyp m9 : 59|1@1+ (1,0) [0|0] "" Vector__XXX
 SG_ RCM2_a085_pretenShldLeftConfig m0 : 60|1@1+ (1,0) [0|0] "" Vector__XXX
 SG_ RCM2_a145_hvdPyroConfig m1 : 60|1@1+ (1,0) [0|0] "" Vector__XXX
 SG_ RCM2_a205_driverFSABConfig m2 : 60|1@1+ (1,0) [0|0] "" Vector__XXX
 SG_ RCM2_a299_imuVertAOffCompNegSLDC m3 : 60|1@1+ (1,0) [0|0] "" Vector__XXX
 SG_ RCM2_a388_upFrntSnsrMidRSigMon m4 : 60|1@1+ (1,0) [0|0] "" Vector__XXX
 SG_ RCM2_a453_presPedProLCrssCoup m5 : 60|1@1+ (1,0) [0|0] "" Vector__XXX
 SG_ RCM2_a517_sideAccelDPilLSigMon m6 : 60|1@1+ (1,0) [0|0] "" Vector__XXX
 SG_ RCM2_a605_comStwAngStatMIA m7 : 60|1@1+ (1,0) [0|0] "" Vector__XXX
 SG_ RCM2_a665_comVCSEATDrestCntr m8 : 60|1@1+ (1,0) [0|0] "" Vector__XXX
 SG_ RCM2_a821_upFrntPedProMLConfig m9 : 60|1@1+ (1,0) [0|0] "" Vector__XXX
 SG_ RCM2_a086_pretenShldRightSht2Gnd m0 : 61|1@1+ (1,0) [0|0] "" Vector__XXX
 SG_ RCM2_a146_curABLeftSht2Gnd m1 : 61|1@1+ (1,0) [0|0] "" Vector__XXX
 SG_ RCM2_a206_sideAB2ndRowLSht2Gnd m2 : 61|1@1+ (1,0) [0|0] "" Vector__XXX
 SG_ RCM2_a300_imuAccXHgMonChlPerm m3 : 61|1@1+ (1,0) [0|0] "" Vector__XXX
 SG_ RCM2_a390_sideAccelBPilLSht2Gnd m4 : 61|1@1+ (1,0) [0|0] "" Vector__XXX
 SG_ RCM2_a454_presPedProLCommErr m5 : 61|1@1+ (1,0) [0|0] "" Vector__XXX
 SG_ RCM2_a518_sideAccelDPilRSht2Gnd m6 : 61|1@1+ (1,0) [0|0] "" Vector__XXX
 SG_ RCM2_a606_comStwAngStatChkSm m7 : 61|1@1+ (1,0) [0|0] "" Vector__XXX
 SG_ RCM2_a666_comVCSEATDbuckle m8 : 61|1@1+ (1,0) [0|0] "" Vector__XXX
 SG_ RCM2_a822_upFrntPedProMLDefect m9 : 61|1@1+ (1,0) [0|0] "" Vector__XXX
 SG_ RCM2_a087_pretenShldRightSht2Bat m0 : 62|1@1+ (1,0) [0|0] "" Vector__XXX
 SG_ RCM2_a147_curABLeftSht2Bat m1 : 62|1@1+ (1,0) [0|0] "" Vector__XXX
 SG_ RCM2_a207_sideAB2ndRowLSht2Bat m2 : 62|1@1+ (1,0) [0|0] "" Vector__XXX
 SG_ RCM2_a301_imuAccXHgMonChlTemp m3 : 62|1@1+ (1,0) [0|0] "" Vector__XXX
 SG_ RCM2_a391_sideAccelBPilLSht2Bat m4 : 62|1@1+ (1,0) [0|0] "" Vector__XXX
 SG_ RCM2_a455_presPedProLInitTyp m5 : 62|1@1+ (1,0) [0|0] "" Vector__XXX
 SG_ RCM2_a519_sideAccelDPilRSht2Bat m6 : 62|1@1+ (1,0) [0|0] "" Vector__XXX
 SG_ RCM2_a607_comStwAngStatCntr m7 : 62|1@1+ (1,0) [0|0] "" Vector__XXX
 SG_ RCM2_a667_comVCSEATDOccpy m8 : 62|1@1+ (1,0) [0|0] "" Vector__XXX
 SG_ RCM2_a823_upFrntPedProMLSigMon m9 : 62|1@1+ (1,0) [0|0] "" Vector__XXX
 SG_ RCM2_a088_pretenShldRightOpen m0 : 63|1@1+ (1,0) [0|0] "" Vector__XXX
 SG_ RCM2_a148_curABLeftOpen m1 : 63|1@1+ (1,0) [0|0] "" Vector__XXX
 SG_ RCM2_a208_sideAB2ndRowLOpen m2 : 63|1@1+ (1,0) [0|0] "" Vector__XXX
 SG_ RCM2_a302_imuAccYHgMonChlPerm m3 : 63|1@1+ (1,0) [0|0] "" Vector__XXX
 SG_ RCM2_a392_sideAccelBPilLOpen m4 : 63|1@1+ (1,0) [0|0] "" Vector__XXX
 SG_ RCM2_a456_presPedProLConfig m5 : 63|1@1+ (1,0) [0|0] "" Vector__XXX
 SG_ RCM2_a520_sideAccelDPilROpen m6 : 63|1@1+ (1,0) [0|0] "" Vector__XXX
 SG_ RCM2_a608_comDItorque1MIA m7 : 63|1@1+ (1,0) [0|0] "" Vector__XXX
 SG_ RCM2_a668_comVCSEATDstps m8 : 63|1@1+ (1,0) [0|0] "" Vector__XXX
 SG_ RCM2_a824_upFrntPedProMRSht2Gnd m9 : 63|1@1+ (1,0) [0|0] "" Vector__XXX

BO_ 1010 RCM3_alertMatrix: 8 Vector__XXX
 SG_ RCM3_matrixIndex M : 0|4@1+ (1,0) [0|0] "" Vector__XXX
 SG_ RCM3_a001_LVPowerLossDetected m0 : 4|1@1+ (1,0) [0|0] "" Vector__XXX

BO_ 1011 UI_odo: 8 Vector__XXX
 SG_ UI_odometer : 0|24@1+ (0.1,0) [0|0] "" Vector__XXX

BO_ 1012 APP_camCalibrationStatus: 8 Vector__XXX
 SG_ APP_cameraPosition M : 0|4@1+ (1,0) [0|0] "" Vector__XXX
 SG_ APP_backupCamExtPitchCal m8 : 8|9@1+ (0.05,-12.5) [0|0] "" Vector__XXX
 SG_ APP_fisheyeCamExtPitchCal m3 : 8|9@1+ (0.05,-12.5) [0|0] "" Vector__XXX
 SG_ APP_lPillarCamExtPitchCal m4 : 8|9@1+ (0.05,-12.5) [0|0] "" Vector__XXX
 SG_ APP_lRepeatCamExtPitchCal m6 : 8|9@1+ (0.05,-12.5) [0|0] "" Vector__XXX
 SG_ APP_mainCamExtPitchCal m1 : 8|9@1+ (0.05,-12.5) [0|0] "" Vector__XXX
 SG_ APP_narrowCamExtPitchCal m2 : 8|9@1+ (0.05,-12.5) [0|0] "" Vector__XXX
 SG_ APP_rPillarCamExtPitchCal m5 : 8|9@1+ (0.05,-12.5) [0|0] "" Vector__XXX
 SG_ APP_rRepeatCamExtPitchCal m7 : 8|9@1+ (0.05,-12.5) [0|0] "" Vector__XXX
 SG_ APP_backupCamExtYawCal m8 : 17|9@1+ (0.05,-12.5) [0|0] "" Vector__XXX
 SG_ APP_fisheyeCamExtYawCal m3 : 17|9@1+ (0.05,-12.5) [0|0] "" Vector__XXX
 SG_ APP_lPillarCamExtYawCal m4 : 17|9@1+ (0.05,-12.5) [0|0] "" Vector__XXX
 SG_ APP_lRepeatCamExtYawCal m6 : 17|9@1+ (0.05,-12.5) [0|0] "" Vector__XXX
 SG_ APP_mainCamExtYawCal m1 : 17|9@1+ (0.05,-12.5) [0|0] "" Vector__XXX
 SG_ APP_narrowCamExtYawCal m2 : 17|9@1+ (0.05,-12.5) [0|0] "" Vector__XXX
 SG_ APP_rPillarCamExtYawCal m5 : 17|9@1+ (0.05,-12.5) [0|0] "" Vector__XXX
 SG_ APP_rRepeatCamExtYawCal m7 : 17|9@1+ (0.05,-12.5) [0|0] "" Vector__XXX
 SG_ APP_backupCalibTime m8 : 26|7@1+ (1,0) [0|0] "" Vector__XXX
 SG_ APP_fisheyeCalibTime m3 : 26|7@1+ (1,0) [0|0] "" Vector__XXX
 SG_ APP_lPillarCalibTime m4 : 26|7@1+ (1,0) [0|0] "" Vector__XXX
 SG_ APP_lRepeatCalibTime m6 : 26|7@1+ (1,0) [0|0] "" Vector__XXX
 SG_ APP_mainCalibTime m1 : 26|7@1+ (1,0) [0|0] "" Vector__XXX
 SG_ APP_narrowCalibTime m2 : 26|7@1+ (1,0) [0|0] "" Vector__XXX
 SG_ APP_rPillarCalibTime m5 : 26|7@1+ (1,0) [0|0] "" Vector__XXX
 SG_ APP_rRepeatCalibTime m7 : 26|7@1+ (1,0) [0|0] "" Vector__XXX
 SG_ APP_backupCalibProgress m8 : 33|7@1+ (1,0) [0|0] "" Vector__XXX
 SG_ APP_fisheyeCalibProgress m3 : 33|7@1+ (1,0) [0|0] "" Vector__XXX
 SG_ APP_lPillarCalibProgress m4 : 33|7@1+ (1,0) [0|0] "" Vector__XXX
 SG_ APP_lRepeatCalibProgress m6 : 33|7@1+ (1,0) [0|0] "" Vector__XXX
 SG_ APP_mainCalibProgress m1 : 33|7@1+ (1,0) [0|0] "" Vector__XXX
 SG_ APP_narrowCalibProgress m2 : 33|7@1+ (1,0) [0|0] "" Vector__XXX
 SG_ APP_rPillarCalibProgress m5 : 33|7@1+ (1,0) [0|0] "" Vector__XXX
 SG_ APP_rRepeatCalibProgress m7 : 33|7@1+ (1,0) [0|0] "" Vector__XXX
 SG_ APP_backupCalibrated m8 : 40|1@1+ (1,0) [0|0] "" Vector__XXX
 SG_ APP_fisheyeCalibrated m3 : 40|1@1+ (1,0) [0|0] "" Vector__XXX
 SG_ APP_lPillarCalibrated m4 : 40|1@1+ (1,0) [0|0] "" Vector__XXX
 SG_ APP_lRepeatCalibrated m6 : 40|1@1+ (1,0) [0|0] "" Vector__XXX
 SG_ APP_mainCalibrated m1 : 40|1@1+ (1,0) [0|0] "" Vector__XXX
 SG_ APP_narrowCalibrated m2 : 40|1@1+ (1,0) [0|0] "" Vector__XXX
 SG_ APP_rPillarCalibrated m5 : 40|1@1+ (1,0) [0|0] "" Vector__XXX
 SG_ APP_rRepeatCalibrated m7 : 40|1@1+ (1,0) [0|0] "" Vector__XXX

BO_ 1013 VCFRONT_lighting: 8 Vector__XXX
 SG_ VCFRONT_indicatorLeftRequest : 0|2@1+ (1,0) [0|0] "" Vector__XXX
 SG_ VCFRONT_indicatorRightRequest : 2|2@1+ (1,0) [0|0] "" Vector__XXX
 SG_ VCFRONT_hazardLightRequest : 4|4@1+ (1,0) [0|0] "" Vector__XXX
 SG_ VCFRONT_ambientLightingBrightnes : 8|8@1+ (0.5,0) [0|0] "" Vector__XXX
 SG_ VCFRONT_switchLightingBrightness : 16|8@1+ (0.5,0) [0|0] "" Vector__XXX
 SG_ VCFRONT_courtesyLightingRequest : 24|1@1+ (1,0) [0|0] "" Vector__XXX
 SG_ VCFRONT_hazardSwitchBacklight : 27|1@1+ (1,0) [0|0] "" Vector__XXX
 SG_ VCFRONT_highBeamControlState : 28|2@1+ (1,0) [0|0] "" Vector__XXX
 SG_ VCFRONT_dynamicBrakeLightState : 30|2@1+ (1,0) [0|0] "" Vector__XXX
 SG_ VCFRONT_lightingCoreState : 32|4@1+ (1,0) [0|0] "" Vector__XXX
 SG_ VCFRONT_intHighBeamsFunctionState : 36|1@1+ (1,0) [0|0] "" Vector__XXX
 SG_ VCFRONT_latchedHighBeamsFunctionState : 37|1@1+ (1,0) [0|0] "" Vector__XXX
 SG_ VCFRONT_frontFogFunctionState : 38|1@1+ (1,0) [0|0] "" Vector__XXX
 SG_ VCFRONT_headlightsReadyOrTimedOut : 39|1@1+ (1,0) [0|0] "" Vector__XXX
 SG_ VCFRONT_turnIndicatorStalk : 40|2@1+ (1,0) [0|0] "" Vector__XXX
 SG_ VCFRONT_highBeamLatchingState : 42|2@1+ (1,0) [0|0] "" Vector__XXX
 SG_ VCFRONT_lightingCustomState : 44|5@1+ (1,0) [0|0] "" Vector__XXX
 SG_ VC_fastFlashHazardsActive : 49|1@1+ (1,0) [0|0] "" Vector__XXX
 SG_ VCFRONT_indicatorLeftInternal : 50|2@1+ (1,0) [0|0] "" Vector__XXX
 SG_ VCFRONT_indicatorRightInternal : 52|2@1+ (1,0) [0|0] "" Vector__XXX

BO_ 1014 APP_ussParamsControl: 8 Vector__XXX
 SG_ APP_ussSequenceEnum : 0|4@1+ (1,0) [0|0] "" Vector__XXX
 SG_ APP_ussExtParamWrite : 4|1@1+ (1,0) [0|0] "" Vector__XXX
 SG_ APP_ussExtParamReset : 5|1@1+ (1,0) [0|0] "" Vector__XXX
 SG_ APP_ussExtForceSequence : 6|1@1+ (1,0) [0|0] "" Vector__XXX
 SG_ APP_ussExtSendRawData : 7|1@1+ (1,0) [0|0] "" Vector__XXX

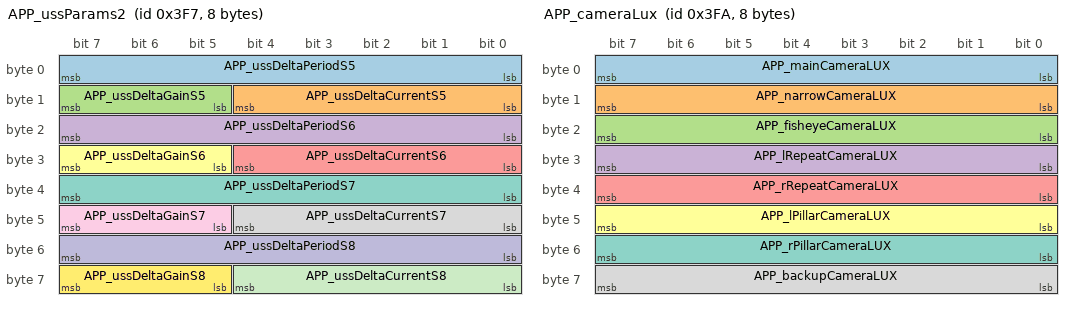
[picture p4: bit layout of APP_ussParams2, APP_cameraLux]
BO_ 1015 APP_ussParams2: 8 Vector__XXX
 SG_ APP_ussDeltaPeriodS5 : 0|8@1- (1,0) [0|0] "" Vector__XXX
 SG_ APP_ussDeltaCurrentS5 : 8|5@1- (1,0) [0|0] "" Vector__XXX
 SG_ APP_ussDeltaGainS5 : 13|3@1- (1,0) [0|0] "" Vector__XXX
 SG_ APP_ussDeltaPeriodS6 : 16|8@1- (1,0) [0|0] "" Vector__XXX
 SG_ APP_ussDeltaCurrentS6 : 24|5@1- (1,0) [0|0] "" Vector__XXX
 SG_ APP_ussDeltaGainS6 : 29|3@1- (1,0) [0|0] "" Vector__XXX
 SG_ APP_ussDeltaPeriodS7 : 32|8@1- (1,0) [0|0] "" Vector__XXX
 SG_ APP_ussDeltaCurrentS7 : 40|5@1- (1,0) [0|0] "" Vector__XXX
 SG_ APP_ussDeltaGainS7 : 45|3@1- (1,0) [0|0] "" Vector__XXX
 SG_ APP_ussDeltaPeriodS8 : 48|8@1- (1,0) [0|0] "" Vector__XXX
 SG_ APP_ussDeltaCurrentS8 : 56|5@1- (1,0) [0|0] "" Vector__XXX
 SG_ APP_ussDeltaGainS8 : 61|3@1- (1,0) [0|0] "" Vector__XXX

BO_ 1016 UI_driverAssistControl: 8 Vector__XXX
 SG_ UI_autopilotControlRequest : 0|1@1+ (1,0) [0|0] "" Vector__XXX
 SG_ UI_ulcStalkConfirm : 1|1@1+ (1,0) [0|0] "" Vector__XXX
 SG_ UI_summonHeartbeat : 2|2@1+ (1,0) [0|0] "" Vector__XXX
 SG_ UI_curvSpeedAdaptDisable : 4|1@1+ (1,0) [0|0] "" Vector__XXX
 SG_ UI_dasDeveloper : 5|1@1+ (1,0) [0|0] "" Vector__XXX
 SG_ UI_enableVinAssociation : 6|1@1+ (1,0) [0|0] "" Vector__XXX
 SG_ UI_lssLkaEnabled : 7|1@1+ (1,0) [0|0] "" Vector__XXX
 SG_ UI_lssLdwEnabled : 8|1@1+ (1,0) [0|0] "" Vector__XXX
 SG_ UI_coastToCoast : 9|1@1+ (1,0) [0|0] "" Vector__XXX
 SG_ UI_autoSummonEnable : 10|1@1+ (1,0) [0|0] "" Vector__XXX
 SG_ UI_exceptionListEnable : 11|1@1+ (1,0) [0|0] "" Vector__XXX
 SG_ UI_roadCheckDisable : 12|1@1+ (1,0) [0|0] "" Vector__XXX
 SG_ UI_driveOnMapsEnable : 13|1@1+ (1,0) [0|0] "" Vector__XXX
 SG_ UI_handsOnRequirementDisable : 14|1@1+ (1,0) [0|0] "" Vector__XXX
 SG_ UI_ulcOffHighway : 15|1@1+ (1,0) [0|0] "" Vector__XXX
 SG_ UI_fuseLanesDisable : 16|1@1+ (1,0) [0|0] "" Vector__XXX
 SG_ UI_fuseHPPDisable : 17|1@1+ (1,0) [0|0] "" Vector__XXX
 SG_ UI_fuseVehiclesDisable : 18|1@1+ (1,0) [0|0] "" Vector__XXX
 SG_ UI_enableClipParkedTelemetry : 19|1@1+ (1,0) [0|0] "" Vector__XXX
 SG_ UI_visionSpeedType : 20|2@1+ (1,0) [0|0] "" Vector__XXX
 SG_ UI_curvatureDatabaseOnly : 22|1@1+ (1,0) [0|0] "" Vector__XXX
 SG_ UI_lssElkEnabled : 23|1@1+ (1,0) [0|0] "" Vector__XXX
 SG_ UI_summonExitType : 24|2@1+ (1,0) [0|0] "" Vector__XXX
 SG_ UI_summonEntryType : 26|2@1+ (1,0) [0|0] "" Vector__XXX
 SG_ UI_selfParkRequest : 28|4@1+ (1,0) [0|0] "" Vector__XXX
 SG_ UI_summonReverseDist : 32|6@1+ (1,0) [0|0] "" Vector__XXX
 SG_ UI_undertakeAssistEnable : 38|1@1+ (1,0) [0|0] "" Vector__XXX
 SG_ UI_adaptiveSetSpeedEnable : 39|1@1+ (1,0) [0|0] "" Vector__XXX
 SG_ UI_drivingSide : 40|2@1+ (1,0) [0|0] "" Vector__XXX
 SG_ UI_enableClipTelemetry : 42|1@1+ (1,0) [0|0] "" Vector__XXX
 SG_ UI_enableTripTelemetry : 43|1@1+ (1,0) [0|0] "" Vector__XXX
 SG_ UI_enableRoadSegmentTelemetry : 44|1@1+ (1,0) [0|0] "" Vector__XXX
 SG_ UI_accFollowDistanceSetting : 45|3@1+ (1,0) [0|0] "" Vector__XXX
 SG_ UI_hasDriveOnNav : 48|1@1+ (1,0) [0|0] "" Vector__XXX
 SG_ UI_followNavRouteEnable : 49|1@1+ (1,0) [0|0] "" Vector__XXX
 SG_ UI_ulcSpeedConfig : 50|2@1+ (1,0) [0|0] "" Vector__XXX
 SG_ UI_ulcBlindSpotConfig : 52|2@1+ (1,0) [0|0] "" Vector__XXX
 SG_ UI_suppressExitPassingLane : 54|1@1+ (1,0) [0|0] "" Vector__XXX
 SG_ UI_enableClipStartStopTelemetry : 55|1@1+ (1,0) [0|0] "" Vector__XXX
 SG_ UI_alcOffHighwayEnable : 56|1@1+ (1,0) [0|0] "" Vector__XXX
 SG_ UI_validationLoop : 57|1@1+ (1,0) [0|0] "" Vector__XXX
 SG_ UI_smartSummonType : 58|2@1+ (1,0) [0|0] "" Vector__XXX
 SG_ UI_enableVisionOnlyStops : 60|1@1+ (1,0) [0|0] "" Vector__XXX
 SG_ UI_source3D : 61|2@1+ (1,0) [0|0] "" Vector__XXX
 SG_ UI_isaSpeedingChimeMuted : 63|1@1+ (1,0) [0|0] "" Vector__XXX

BO_ 1018 APP_cameraLux: 8 Vector__XXX
 SG_ APP_mainCameraLUX : 0|8@1+ (0.5,0) [0|0] "" Vector__XXX
 SG_ APP_narrowCameraLUX : 8|8@1+ (0.5,0) [0|0] "" Vector__XXX
 SG_ APP_fisheyeCameraLUX : 16|8@1+ (0.5,0) [0|0] "" Vector__XXX
 SG_ APP_lRepeatCameraLUX : 24|8@1+ (0.5,0) [0|0] "" Vector__XXX
 SG_ APP_rRepeatCameraLUX : 32|8@1+ (0.5,0) [0|0] "" Vector__XXX
 SG_ APP_lPillarCameraLUX : 40|8@1+ (0.5,0) [0|0] "" Vector__XXX
 SG_ APP_rPillarCameraLUX : 48|8@1+ (0.5,0) [0|0] "" Vector__XXX
 SG_ APP_backupCameraLUX : 56|8@1+ (0.5,0) [0|0] "" Vector__XXX

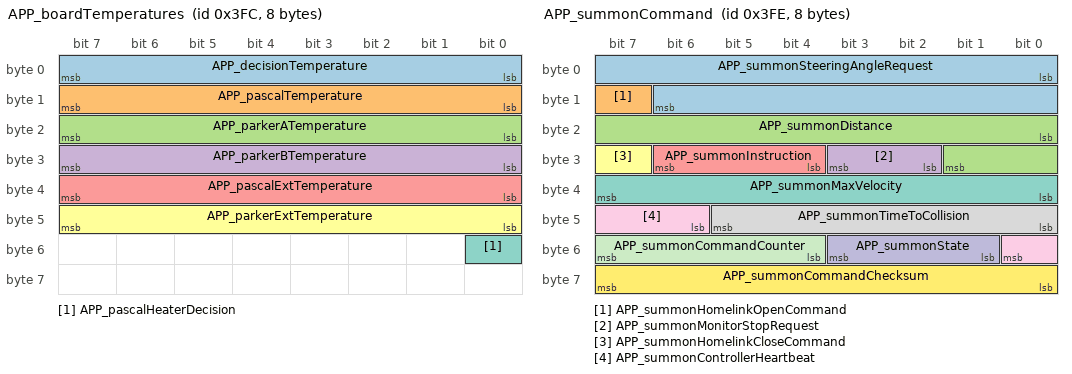
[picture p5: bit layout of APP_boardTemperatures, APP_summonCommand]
BO_ 1020 APP_boardTemperatures: 8 Vector__XXX
 SG_ APP_decisionTemperature : 0|8@1+ (1,-128) [0|0] "" Vector__XXX
 SG_ APP_pascalTemperature : 8|8@1+ (1,-128) [0|0] "" Vector__XXX
 SG_ APP_parkerATemperature : 16|8@1+ (1,-128) [0|0] "" Vector__XXX
 SG_ APP_parkerBTemperature : 24|8@1+ (1,-128) [0|0] "" Vector__XXX
 SG_ APP_pascalExtTemperature : 32|8@1+ (1,-128) [0|0] "" Vector__XXX
 SG_ APP_parkerExtTemperature : 40|8@1+ (1,-128) [0|0] "" Vector__XXX
 SG_ APP_pascalHeaterDecision : 48|1@1+ (1,0) [0|0] "" Vector__XXX

BO_ 1021 UI_autopilotControl: 8 Vector__XXX
 SG_ UI_autopilotControlIndex M : 0|3@1+ (1,0) [0|0] "" Vector__XXX
 SG_ UI_hovEnabled m0 : 3|1@1+ (1,0) [0|0] "" Vector__XXX
 SG_ UI_donDisableAutoWiperDuration m0 : 4|3@1+ (1,0) [0|0] "" Vector__XXX
 SG_ UI_enableApproachingEmergencyVehicleDetection m2 : 5|1@1+ (1,0) [0|0] "" Vector__XXX
 SG_ UI_enableStartFsdFromParkBrakeConfirmation m2 : 6|1@1+ (1,0) [0|0] "" Vector__XXX
 SG_ UI_donDisableOnAutoWiperSpeed m0 : 7|4@1+ (1,0) [0|0] "" Vector__XXX
 SG_ UI_enableStartFsdFromPark m2 : 7|1@1+ (1,0) [0|0] "" Vector__XXX
 SG_ UI_fsdMaxSpeedOffsetPercentage m2 : 8|6@1+ (1,0) [0|0] "" Vector__XXX
 SG_ UI_selectableCameraRequest m1 : 8|4@1+ (1,0) [0|0] "" Vector__XXX
 SG_ UI_blindspotMinSpeed m0 : 11|4@1+ (1,0) [0|0] "" Vector__XXX
 SG_ UI_blindspotDistance m0 : 15|3@1+ (1,0) [0|0] "" Vector__XXX
 SG_ UI_calibrationReadyInFactory m2 : 15|1@1+ (1,0) [0|0] "" Vector__XXX
 SG_ UI_coldStartMonarchInFactory m2 : 16|1@1+ (1,0) [0|0] "" Vector__XXX
 SG_ UI_overrideSleepWithSuspend m1 : 16|1@1+ (1,0) [0|0] "" Vector__XXX
 SG_ UI_driverMonitorConfirmation m1 : 17|1@1+ (1,0) [0|0] "" Vector__XXX
 SG_ UI_navMinutesToArrival m2 : 17|10@1+ (1,0) [0|0] "" Vector__XXX
 SG_ UI_blindspotTTC m0 : 18|3@1+ (1,0) [0|0] "" Vector__XXX
 SG_ UI_parkAssistUseVision m1 : 18|1@1+ (1,0) [0|0] "" Vector__XXX
 SG_ UI_applyEceR79 m1 : 19|1@1+ (1,0) [0|0] "" Vector__XXX
 SG_ UI_enableMapStops m1 : 20|1@1+ (1,0) [0|0] "" Vector__XXX
 SG_ UI_donStopEndOfRampBuffer m0 : 21|3@1+ (1,0) [0|0] "" Vector__XXX
 SG_ UI_disableMain m1 : 23|1@1+ (1,0) [0|0] "" Vector__XXX
 SG_ UI_disableNarrow m1 : 24|1@1+ (1,0) [0|0] "" Vector__XXX
 SG_ UI_donDisableCutin m0 : 24|1@1+ (1,0) [0|0] "" Vector__XXX
 SG_ UI_disableFisheye m1 : 25|1@1+ (1,0) [0|0] "" Vector__XXX
 SG_ UI_smartSetSpeedOffset m0 : 25|6@1+ (1,-30) [0|0] "" Vector__XXX
 SG_ UI_disableLeftPillar m1 : 26|1@1+ (1,0) [0|0] "" Vector__XXX
 SG_ UI_disableRightPillar m1 : 27|1@1+ (1,0) [0|0] "" Vector__XXX
 SG_ UI_fsdQuizRequired m2 : 27|1@1+ (1,0) [0|0] "" Vector__XXX
 SG_ UI_disableLeftRepeater m1 : 28|1@1+ (1,0) [0|0] "" Vector__XXX
 SG_ UI_fsdQuizPassed m2 : 28|1@1+ (1,0) [0|0] "" Vector__XXX
 SG_ UI_disableRightRepeater m1 : 29|1@1+ (1,0) [0|0] "" Vector__XXX
 SG_ UI_fsdAllowedInLocalizedRegion m2 : 29|1@1+ (1,0) [0|0] "" Vector__XXX
 SG_ UI_disableBackup m1 : 30|1@1+ (1,0) [0|0] "" Vector__XXX
 SG_ UI_disableRadar m1 : 31|1@1+ (1,0) [0|0] "" Vector__XXX
 SG_ UI_smartSetSpeedOffsetType m0 : 31|1@1+ (1,0) [0|0] "" Vector__XXX
 SG_ UI_autopilotMonarchBackup m0 : 32|1@1+ (1,0) [0|0] "" Vector__XXX
 SG_ UI_noStalkConfirmAlertHaptic m1 : 32|1@1+ (1,0) [0|0] "" Vector__XXX
 SG_ UI_regulatoryLKA m1 : 33|1@1+ (1,0) [0|0] "" Vector__XXX
 SG_ UI_regulatoryLaneAssistLevel m1 : 34|1@1+ (1,0) [0|0] "" Vector__XXX
 SG_ UI_ulcSnooze m1 : 36|1@1+ (1,0) [0|0] "" Vector__XXX
 SG_ UI_fsdVisualizationEnabled m0 : 37|1@1+ (1,0) [0|0] "" Vector__XXX
 SG_ UI_noStalkConfirmAlertChime m1 : 37|1@1+ (1,0) [0|0] "" Vector__XXX
 SG_ UI_fsdStopsControlEnabled m0 : 38|1@1+ (1,0) [0|0] "" Vector__XXX
 SG_ UI_factorySummonEnable m1 : 39|1@1+ (1,0) [0|0] "" Vector__XXX
 SG_ UI_fsdContinueOnGreenWithCIPV m0 : 39|1@1+ (1,0) [0|0] "" Vector__XXX
 SG_ UI_apmv3Branch m1 : 40|3@1+ (1,0) [0|0] "" Vector__XXX
 SG_ UI_smartSetSpeed m0 : 40|1@1+ (1,0) [0|0] "" Vector__XXX
 SG_ UI_automaticSetSpeedOffset m0 : 41|1@1+ (1,0) [0|0] "" Vector__XXX
 SG_ UI_apply2021_1958_ISA m0 : 42|1@1+ (1,0) [0|0] "" Vector__XXX
 SG_ UI_apply2021_646_ELKS m0 : 43|1@1+ (1,0) [0|0] "" Vector__XXX
 SG_ UI_enableCabinCamera m1 : 43|1@1+ (1,0) [0|0] "" Vector__XXX
 SG_ UI_apply2021_1341_DDAW m0 : 44|1@1+ (1,0) [0|0] "" Vector__XXX
 SG_ UI_enableAutopilotStopWarning m1 : 44|1@1+ (1,0) [0|0] "" Vector__XXX
 SG_ UI_homelinkNearby m0 : 45|1@1+ (1,0) [0|0] "" Vector__XXX
 SG_ UI_showLaneGraph m1 : 45|1@1+ (1,0) [0|0] "" Vector__XXX
 SG_ UI_enableFullSelfDriving m0 : 46|1@1+ (1,0) [0|0] "" Vector__XXX
 SG_ UI_showTrackLabels m1 : 46|1@1+ (1,0) [0|0] "" Vector__XXX
 SG_ UI_hardCoreSummon m1 : 47|1@1+ (1,0) [0|0] "" Vector__XXX
 SG_ UI_hasFullSelfDriving m0 : 47|1@1+ (1,0) [0|0] "" Vector__XXX
 SG_ UI_autosteerActivation m0 : 48|1@1+ (1,0) [0|0] "" Vector__XXX
 SG_ UI_enableCabinCameraTelemetry m1 : 48|1@1+ (1,0) [0|0] "" Vector__XXX
 SG_ UI_enableVisionSpeedControl m1 : 49|1@1+ (1,0) [0|0] "" Vector__XXX
 SG_ UI_autopilotTelemetryInChina m1 : 50|1@1+ (1,0) [0|0] "" Vector__XXX
 SG_ UI_enableTeslaAutopark m1 : 51|1@1+ (1,0) [0|0] "" Vector__XXX
 SG_ UI_fsdBetaRequest m0 : 51|1@1+ (1,0) [0|0] "" Vector__XXX
 SG_ UI_autoTurnSignalMode m1 : 52|1@1+ (1,0) [0|0] "" Vector__XXX
 SG_ UI_fullSelfDrivingSuspended m0 : 52|1@1+ (1,0) [0|0] "" Vector__XXX
 SG_ UI_disableOptionalLaneChanges m0 : 53|1@1+ (1,0) [0|0] "" Vector__XXX
 SG_ UI_enableCautionLightControl m1 : 54|1@1+ (1,0) [0|0] "" Vector__XXX
 SG_ UI_applyEceR79SmartSummonOnly m1 : 55|1@1+ (1,0) [0|0] "" Vector__XXX
 SG_ UI_autopilotMonarchEnabled m1 : 56|1@1+ (1,0) [0|0] "" Vector__XXX
 SG_ UI_autopilotEphemerisEnabled m1 : 57|1@1+ (1,0) [0|0] "" Vector__XXX
 SG_ UI_applyR152_AEBS m0 : 59|1@1+ (1,0) [0|0] "" Vector__XXX
 SG_ UI_enableCabinAudioRecording m1 : 59|1@1+ (1,0) [0|0] "" Vector__XXX
 SG_ UI_applyDCASBehavior m0 : 60|1@1+ (1,0) [0|0] "" Vector__XXX
 SG_ UI_autopilotDrivingProfile m2 : 60|3@1+ (1,0) [0|0] "" Vector__XXX
 SG_ UI_applyDCASBehaviorLegacy m0 : 61|1@1+ (1,0) [0|0] "" Vector__XXX
 SG_ UI_autopilotControlMux0Valid m0 : 63|1@1+ (1,0) [0|0] "" Vector__XXX
 SG_ UI_autopilotControlMux1Valid m1 : 63|1@1+ (1,0) [0|0] "" Vector__XXX
 SG_ UI_autopilotControlMux2Valid m2 : 63|1@1+ (1,0) [0|0] "" Vector__XXX

BO_ 1022 APP_summonCommand: 8 Vector__XXX
 SG_ APP_summonSteeringAngleRequest : 0|15@1+ (0.1,-1638.35) [0|0] "" Vector__XXX
 SG_ APP_summonHomelinkOpenCommand : 15|1@1+ (1,0) [0|0] "" Vector__XXX
 SG_ APP_summonDistance : 16|10@1+ (0.02,0) [0|0] "" Vector__XXX
 SG_ APP_summonMonitorStopRequest : 26|2@1+ (1,0) [0|0] "" Vector__XXX
 SG_ APP_summonInstruction : 28|3@1+ (1,0) [0|0] "" Vector__XXX
 SG_ APP_summonHomelinkCloseCommand : 31|1@1+ (1,0) [0|0] "" Vector__XXX
 SG_ APP_summonMaxVelocity : 32|8@1+ (0.05,0) [0|0] "" Vector__XXX
 SG_ APP_summonTimeToCollision : 40|6@1+ (0.1,0) [0|0] "" Vector__XXX
 SG_ APP_summonControllerHeartbeat : 46|3@1+ (1,0) [0|0] "" Vector__XXX
 SG_ APP_summonState : 49|3@1+ (1,0) [0|0] "" Vector__XXX
 SG_ APP_summonCommandCounter : 52|4@1+ (1,0) [0|0] "" Vector__XXX
 SG_ APP_summonCommandChecksum : 56|8@1+ (1,0) [0|0] "" Vector__XXX

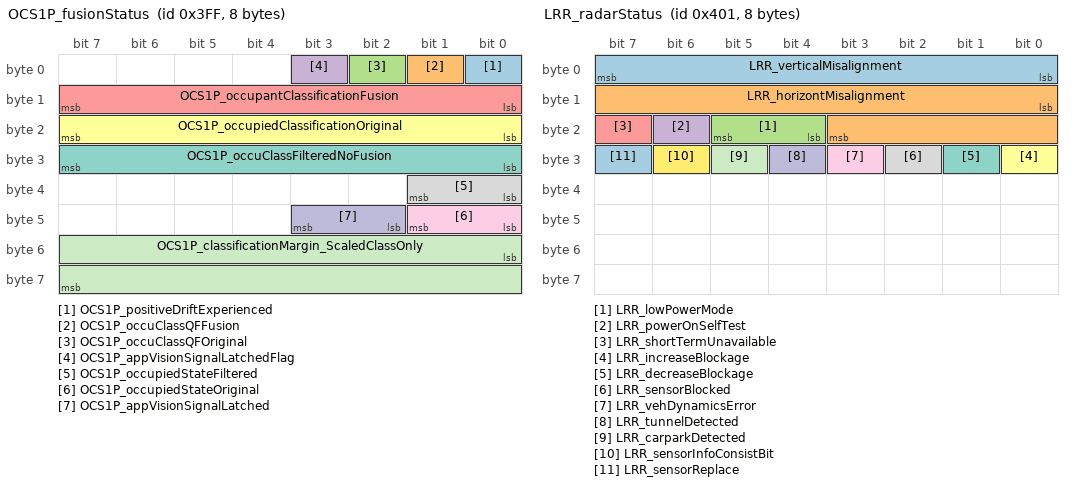
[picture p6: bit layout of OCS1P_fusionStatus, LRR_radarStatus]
BO_ 1023 OCS1P_fusionStatus: 8 Vector__XXX
 SG_ OCS1P_positiveDriftExperienced : 0|1@1+ (1,0) [0|0] "" Vector__XXX
 SG_ OCS1P_occuClassQFFusion : 1|1@1+ (1,0) [0|0] "" Vector__XXX
 SG_ OCS1P_occuClassQFOriginal : 2|1@1+ (1,0) [0|0] "" Vector__XXX
 SG_ OCS1P_appVisionSignalLatchedFlag : 3|1@1+ (1,0) [0|0] "" Vector__XXX
 SG_ OCS1P_occupantClassificationFusion : 8|8@1+ (1,0) [0|0] "" Vector__XXX
 SG_ OCS1P_occupiedClassificationOriginal : 16|8@1+ (1,0) [0|0] "" Vector__XXX
 SG_ OCS1P_occuClassFilteredNoFusion : 24|8@1+ (1,0) [0|0] "" Vector__XXX
 SG_ OCS1P_occupiedStateFiltered : 32|2@1+ (1,0) [0|0] "" Vector__XXX
 SG_ OCS1P_occupiedStateOriginal : 40|2@1+ (1,0) [0|0] "" Vector__XXX
 SG_ OCS1P_appVisionSignalLatched : 42|2@1+ (1,0) [0|0] "" Vector__XXX
 SG_ OCS1P_classificationMargin_ScaledClassOnly : 48|16@1- (2,0) [0|0] "" Vector__XXX

BO_ 1025 LRR_radarStatus: 8 Vector__XXX
 SG_ LRR_verticalMisalignment : 0|8@1+ (0.001953125,-0.25) [0|0] "" Vector__XXX
 SG_ LRR_horizontMisalignment : 8|12@1+ (0.0001220703125,-0.25) [0|0] "" Vector__XXX
 SG_ LRR_lowPowerMode : 20|2@1+ (1,0) [0|0] "" Vector__XXX
 SG_ LRR_powerOnSelfTest : 22|1@1+ (1,0) [0|0] "" Vector__XXX
 SG_ LRR_shortTermUnavailable : 23|1@1+ (1,0) [0|0] "" Vector__XXX
 SG_ LRR_increaseBlockage : 24|1@1+ (1,0) [0|0] "" Vector__XXX
 SG_ LRR_decreaseBlockage : 25|1@1+ (1,0) [0|0] "" Vector__XXX
 SG_ LRR_sensorBlocked : 26|1@1+ (1,0) [0|0] "" Vector__XXX
 SG_ LRR_vehDynamicsError : 27|1@1+ (1,0) [0|0] "" Vector__XXX
 SG_ LRR_tunnelDetected : 28|1@1+ (1,0) [0|0] "" Vector__XXX
 SG_ LRR_carparkDetected : 29|1@1+ (1,0) [0|0] "" Vector__XXX
 SG_ LRR_sensorInfoConsistBit : 30|1@1+ (1,0) [0|0] "" Vector__XXX
 SG_ LRR_sensorReplace : 31|1@1+ (1,0) [0|0] "" Vector__XXX

BO_ 1029 GTW_vin: 12 Vector__XXX
 SG_ GTW_vinIndex M : 7|8@0+ (1,0) [0|0] "" Vector__XXX
 SG_ GTW_vinLow m18 : 15|56@0+ (1,0) [0|0] "" Vector__XXX
 SG_ GTW_vinMid m17 : 15|56@0+ (1,0) [0|0] "" Vector__XXX
 SG_ GTW_vinHigh m16 : 47|24@0+ (1,0) [0|0] "" Vector__XXX

BO_ 1030 DAS_robDebug: 8 Vector__XXX
 SG_ DAS_eObjMultiplexer M : 0|4@1+ (1,0) [0|0] "" Vector__XXX
 SG_ DAS_eObj00Valid m0 : 4|1@1+ (1,0) [0|0] "" Vector__XXX
 SG_ DAS_eObj01Valid m1 : 4|1@1+ (1,0) [0|0] "" Vector__XXX
 SG_ DAS_eObj02Valid m2 : 4|1@1+ (1,0) [0|0] "" Vector__XXX
 SG_ DAS_eObj03Valid m3 : 4|1@1+ (1,0) [0|0] "" Vector__XXX
 SG_ DAS_eObj00Age m0 : 5|3@1+ (1,0) [0|0] "" Vector__XXX
 SG_ DAS_eObj01Age m1 : 5|3@1+ (1,0) [0|0] "" Vector__XXX
 SG_ DAS_eObj02Age m2 : 5|3@1+ (1,0) [0|0] "" Vector__XXX
 SG_ DAS_eObj03Age m3 : 5|3@1+ (1,0) [0|0] "" Vector__XXX
 SG_ DAS_eObj00PositionX m0 : 8|8@1+ (0.5,0) [0|0] "" Vector__XXX
 SG_ DAS_eObj01PositionX m1 : 8|8@1+ (0.5,0) [0|0] "" Vector__XXX
 SG_ DAS_eObj02PositionX m2 : 8|8@1+ (0.5,0) [0|0] "" Vector__XXX
 SG_ DAS_eObj03PositionX m3 : 8|8@1+ (0.5,0) [0|0] "" Vector__XXX
 SG_ DAS_robClusterStart m5 : 8|8@1+ (1,-95) [0|0] "" Vector__XXX
 SG_ DAS_robPossibleCollision m4 : 8|1@1+ (1,0) [0|0] "" Vector__XXX
 SG_ DAS_robActiveBraking m4 : 9|1@1+ (1,0) [0|0] "" Vector__XXX
 SG_ DAS_robRequestEventRecorder m4 : 10|1@1+ (1,0) [0|0] "" Vector__XXX
 SG_ DAS_robInfrastructure m4 : 11|1@1+ (1,0) [0|0] "" Vector__XXX
 SG_ DAS_robAEBAlertLatch m4 : 12|1@1+ (1,0) [0|0] "" Vector__XXX
 SG_ DAS_robMapTrusted m4 : 13|1@1+ (1,0) [0|0] "" Vector__XXX
 SG_ DAS_eObj00PositionY m0 : 16|8@1+ (0.25,-31.875) [0|0] "" Vector__XXX
 SG_ DAS_eObj01PositionY m1 : 16|8@1+ (0.25,-31.875) [0|0] "" Vector__XXX
 SG_ DAS_eObj02PositionY m2 : 16|8@1+ (0.25,-31.875) [0|0] "" Vector__XXX
 SG_ DAS_eObj03PositionY m3 : 16|8@1+ (0.25,-31.875) [0|0] "" Vector__XXX
 SG_ DAS_robClusterEnd m5 : 16|8@1+ (1,0) [0|0] "" Vector__XXX
 SG_ DAS_robCollisionConf m4 : 16|4@1+ (1,0) [0|0] "" Vector__XXX
 SG_ DAS_robCriticalObjAge m4 : 20|4@1+ (1,0) [0|0] "" Vector__XXX
 SG_ DAS_eObj00Moment0 m0 : 24|8@1+ (0.25,-31.875) [0|0] "" Vector__XXX
 SG_ DAS_eObj01Moment0 m1 : 24|8@1+ (0.25,-31.875) [0|0] "" Vector__XXX
 SG_ DAS_eObj02Moment0 m2 : 24|8@1+ (0.25,-31.875) [0|0] "" Vector__XXX
 SG_ DAS_eObj03Moment0 m3 : 24|8@1+ (0.25,-31.875) [0|0] "" Vector__XXX
 SG_ DAS_robCriticalObjIndex m4 : 24|4@1+ (1,0) [0|0] "" Vector__XXX
 SG_ DAS_robMapTrust m5 : 24|1@1+ (1,0) [0|0] "" Vector__XXX
 SG_ DAS_robEnableBraking m5 : 25|1@1+ (1,0) [0|0] "" Vector__XXX
 SG_ DAS_robGPSHealthy m5 : 26|1@1+ (1,0) [0|0] "" Vector__XXX
 SG_ DAS_robRadarFault m5 : 27|1@1+ (1,0) [0|0] "" Vector__XXX
 SG_ DAS_robRadarBlind m5 : 28|1@1+ (1,0) [0|0] "" Vector__XXX
 SG_ DAS_robActiveLogging m5 : 29|1@1+ (1,0) [0|0] "" Vector__XXX
 SG_ DAS_eObj00Moment1 m0 : 32|8@1+ (0.25,-31.875) [0|0] "" Vector__XXX
 SG_ DAS_eObj01Moment1 m1 : 32|8@1+ (0.25,-31.875) [0|0] "" Vector__XXX
 SG_ DAS_eObj02Moment1 m2 : 32|8@1+ (0.25,-31.875) [0|0] "" Vector__XXX
 SG_ DAS_eObj03Moment1 m3 : 32|8@1+ (0.25,-31.875) [0|0] "" Vector__XXX
 SG_ DAS_robDistanceObstacle m4 : 32|8@1+ (1,0) [0|0] "" Vector__XXX
 SG_ DAS_eObj00Moment2 m0 : 40|8@1+ (0.25,-31.875) [0|0] "" Vector__XXX
 SG_ DAS_eObj01Moment2 m1 : 40|8@1+ (0.25,-31.875) [0|0] "" Vector__XXX
 SG_ DAS_eObj02Moment2 m2 : 40|8@1+ (0.25,-31.875) [0|0] "" Vector__XXX
 SG_ DAS_eObj03Moment2 m3 : 40|8@1+ (0.25,-31.875) [0|0] "" Vector__XXX
 SG_ DAS_robWidthObstacle m4 : 40|8@1+ (0.1,0) [0|0] "" Vector__XXX
 SG_ DAS_eObj00Moment3 m0 : 48|8@1+ (0.25,-31.875) [0|0] "" Vector__XXX
 SG_ DAS_eObj01Moment3 m1 : 48|8@1+ (0.25,-31.875) [0|0] "" Vector__XXX
 SG_ DAS_eObj02Moment3 m2 : 48|8@1+ (0.25,-31.875) [0|0] "" Vector__XXX
 SG_ DAS_eObj03Moment3 m3 : 48|8@1+ (0.25,-31.875) [0|0] "" Vector__XXX
 SG_ DAS_robOverlapObstacle m4 : 48|8@1+ (0.1,0) [0|0] "" Vector__XXX
 SG_ DAS_eObj00InPath m0 : 56|1@1+ (1,0) [0|0] "" Vector__XXX
 SG_ DAS_eObj01InPath m1 : 56|1@1+ (1,0) [0|0] "" Vector__XXX
 SG_ DAS_eObj02InPath m2 : 56|1@1+ (1,0) [0|0] "" Vector__XXX
 SG_ DAS_eObj03InPath m3 : 56|1@1+ (1,0) [0|0] "" Vector__XXX
 SG_ DAS_robTimeCollision m4 : 56|8@1+ (0.05,0) [0|0] "" Vector__XXX
 SG_ DAS_eObj00Blacklist m0 : 57|1@1+ (1,0) [0|0] "" Vector__XXX
 SG_ DAS_eObj01Blacklist m1 : 57|1@1+ (1,0) [0|0] "" Vector__XXX
 SG_ DAS_eObj02Blacklist m2 : 57|1@1+ (1,0) [0|0] "" Vector__XXX
 SG_ DAS_eObj03Blacklist m3 : 57|1@1+ (1,0) [0|0] "" Vector__XXX
 SG_ DAS_eObj00Elevated m0 : 58|1@1+ (1,0) [0|0] "" Vector__XXX
 SG_ DAS_eObj01Elevated m1 : 58|1@1+ (1,0) [0|0] "" Vector__XXX
 SG_ DAS_eObj02Elevated m2 : 58|1@1+ (1,0) [0|0] "" Vector__XXX
 SG_ DAS_eObj03Elevated m3 : 58|1@1+ (1,0) [0|0] "" Vector__XXX

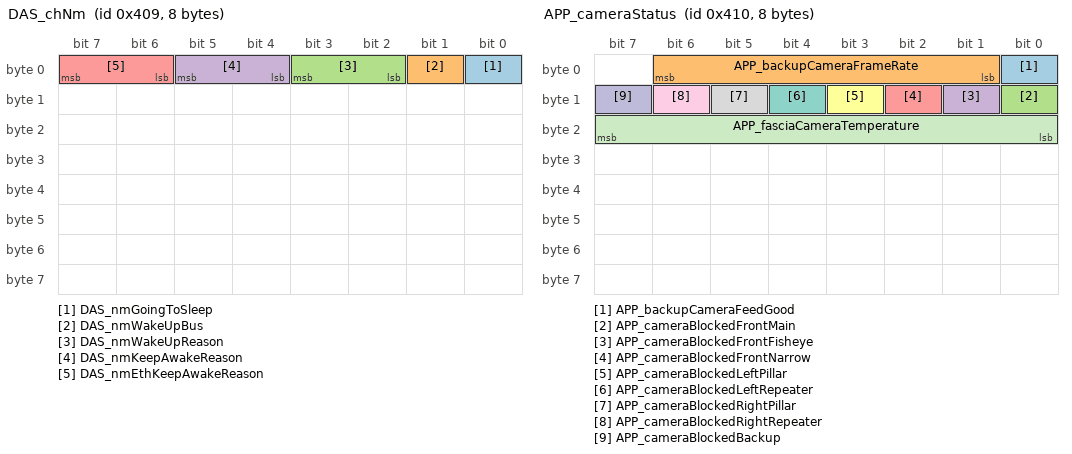
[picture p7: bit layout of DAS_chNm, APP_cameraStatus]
BO_ 1033 DAS_chNm: 8 Vector__XXX
 SG_ DAS_nmGoingToSleep : 0|1@1+ (1,0) [0|0] "" Vector__XXX
 SG_ DAS_nmWakeUpBus : 1|1@1+ (1,0) [0|0] "" Vector__XXX
 SG_ DAS_nmWakeUpReason : 2|2@1+ (1,0) [0|0] "" Vector__XXX
 SG_ DAS_nmKeepAwakeReason : 4|2@1+ (1,0) [0|0] "" Vector__XXX
 SG_ DAS_nmEthKeepAwakeReason : 6|2@1+ (1,0) [0|0] "" Vector__XXX

BO_ 1040 APP_cameraStatus: 8 Vector__XXX
 SG_ APP_backupCameraFeedGood : 0|1@1+ (1,0) [0|0] "" Vector__XXX
 SG_ APP_backupCameraFrameRate : 1|6@1+ (1,0) [0|0] "" Vector__XXX
 SG_ APP_cameraBlockedFrontMain : 8|1@1+ (1,0) [0|0] "" Vector__XXX
 SG_ APP_cameraBlockedFrontFisheye : 9|1@1+ (1,0) [0|0] "" Vector__XXX
 SG_ APP_cameraBlockedFrontNarrow : 10|1@1+ (1,0) [0|0] "" Vector__XXX
 SG_ APP_cameraBlockedLeftPillar : 11|1@1+ (1,0) [0|0] "" Vector__XXX
 SG_ APP_cameraBlockedLeftRepeater : 12|1@1+ (1,0) [0|0] "" Vector__XXX
 SG_ APP_cameraBlockedRightPillar : 13|1@1+ (1,0) [0|0] "" Vector__XXX
 SG_ APP_cameraBlockedRightRepeater : 14|1@1+ (1,0) [0|0] "" Vector__XXX
 SG_ APP_cameraBlockedBackup : 15|1@1+ (1,0) [0|0] "" Vector__XXX
 SG_ APP_fasciaCameraTemperature : 16|8@1+ (1,-60) [0|0] "" Vector__XXX

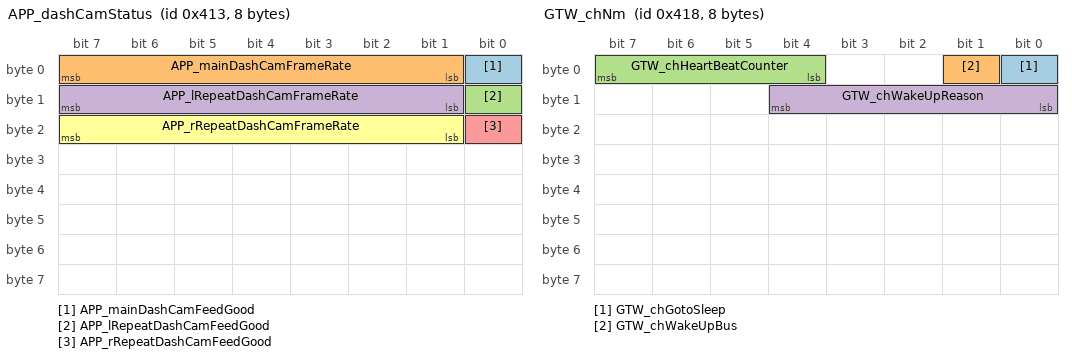
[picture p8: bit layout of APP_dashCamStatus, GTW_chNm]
BO_ 1043 APP_dashCamStatus: 8 Vector__XXX
 SG_ APP_mainDashCamFeedGood : 0|1@1+ (1,0) [0|0] "" Vector__XXX
 SG_ APP_mainDashCamFrameRate : 1|7@1+ (1,0) [0|0] "" Vector__XXX
 SG_ APP_lRepeatDashCamFeedGood : 8|1@1+ (1,0) [0|0] "" Vector__XXX
 SG_ APP_lRepeatDashCamFrameRate : 9|7@1+ (1,0) [0|0] "" Vector__XXX
 SG_ APP_rRepeatDashCamFeedGood : 16|1@1+ (1,0) [0|0] "" Vector__XXX
 SG_ APP_rRepeatDashCamFrameRate : 17|7@1+ (1,0) [0|0] "" Vector__XXX

BO_ 1045 APP_backupDashCamStatus: 8 Vector__XXX
 SG_ APP_backupDashCamFeedGood : 0|1@1+ (1,0) [0|0] "" Vector__XXX
 SG_ APP_backupDashCamFrameRate : 1|7@1+ (1,0) [0|0] "" Vector__XXX

BO_ 1048 GTW_chNm: 8 Vector__XXX
 SG_ GTW_chGotoSleep : 0|1@1+ (1,0) [0|0] "" Vector__XXX
 SG_ GTW_chWakeUpBus : 1|1@1+ (1,0) [0|0] "" Vector__XXX
 SG_ GTW_chHeartBeatCounter : 4|4@1+ (1,0) [0|0] "" Vector__XXX
 SG_ GTW_chWakeUpReason : 8|5@1+ (1,0) [0|0] "" Vector__XXX

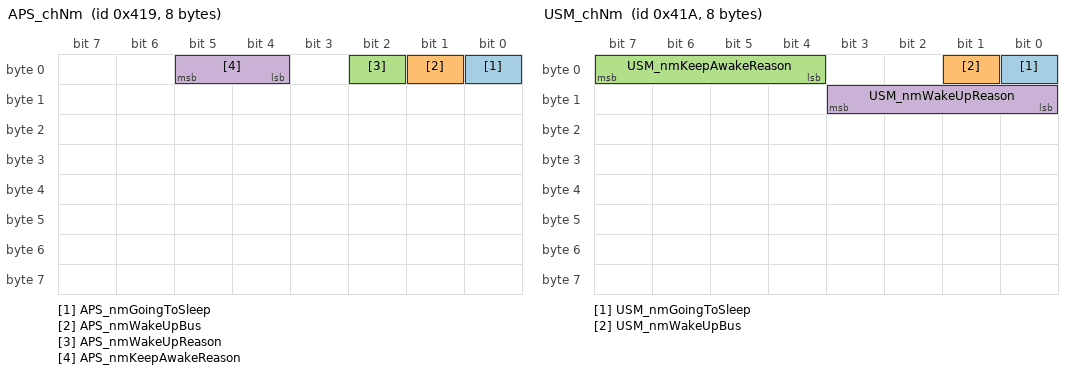
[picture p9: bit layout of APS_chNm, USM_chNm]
BO_ 1049 APS_chNm: 8 Vector__XXX
 SG_ APS_nmGoingToSleep : 0|1@1+ (1,0) [0|0] "" Vector__XXX
 SG_ APS_nmWakeUpBus : 1|1@1+ (1,0) [0|0] "" Vector__XXX
 SG_ APS_nmWakeUpReason : 2|1@1+ (1,0) [0|0] "" Vector__XXX
 SG_ APS_nmKeepAwakeReason : 4|2@1+ (1,0) [0|0] "" Vector__XXX

BO_ 1050 USM_chNm: 8 Vector__XXX
 SG_ USM_nmGoingToSleep : 0|1@1+ (1,0) [0|0] "" Vector__XXX
 SG_ USM_nmWakeUpBus : 1|1@1+ (1,0) [0|0] "" Vector__XXX
 SG_ USM_nmKeepAwakeReason : 4|4@1+ (1,0) [0|0] "" Vector__XXX
 SG_ USM_nmWakeUpReason : 8|4@1+ (1,0) [0|0] "" Vector__XXX

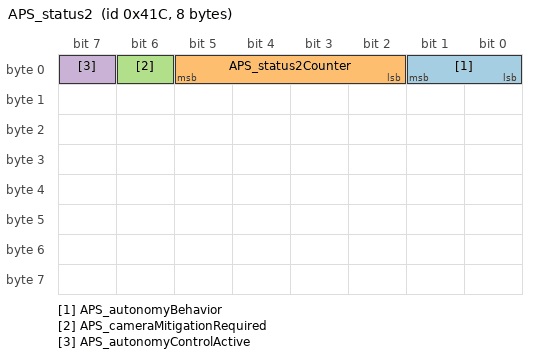
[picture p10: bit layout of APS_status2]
BO_ 1052 APS_status2: 8 Vector__XXX
 SG_ APS_autonomyBehavior : 0|2@1+ (1,0) [0|0] "" Vector__XXX
 SG_ APS_status2Counter : 2|4@1+ (1,0) [0|0] "" Vector__XXX
 SG_ APS_cameraMitigationRequired : 6|1@1+ (1,0) [0|0] "" Vector__XXX
 SG_ APS_autonomyControlActive : 7|1@1+ (1,0) [0|0] "" Vector__XXX

BO_ 1056 APS_state: 8 Vector__XXX
 SG_ APS_primaryTurbo : 0|2@1+ (1,0) [0|0] "" Vector__XXX
 SG_ APS_A_arbState : 2|3@1+ (1,0) [0|0] "" Vector__XXX
 SG_ APS_A_powerState : 5|5@1+ (1,0) [0|0] "" Vector__XXX
 SG_ APS_A_sleepState : 10|4@1+ (1,0) [0|0] "" Vector__XXX
 SG_ APS_A_resetState : 14|3@1+ (1,0) [0|0] "" Vector__XXX
 SG_ APS_A_faultState : 17|5@1+ (1,0) [0|0] "" Vector__XXX
 SG_ APS_secondaryTurbo : 22|2@1+ (1,0) [0|0] "" Vector__XXX
 SG_ APS_B_arbState : 24|3@1+ (1,0) [0|0] "" Vector__XXX
 SG_ APS_B_powerState : 27|5@1+ (1,0) [0|0] "" Vector__XXX
 SG_ APS_B_sleepState : 32|4@1+ (1,0) [0|0] "" Vector__XXX
 SG_ APS_B_resetState : 36|3@1+ (1,0) [0|0] "" Vector__XXX
 SG_ APS_B_faultState : 39|5@1+ (1,0) [0|0] "" Vector__XXX
 SG_ APS_A_autosteerMonitorState : 44|3@1+ (1,0) [0|0] "" Vector__XXX
 SG_ APS_B_autosteerMonitorState : 47|3@1+ (1,0) [0|0] "" Vector__XXX
 SG_ APS_eplannerState : 50|3@1+ (1,0) [0|0] "" Vector__XXX
 SG_ APS_A_faultInduced : 53|1@1+ (1,0) [0|0] "" Vector__XXX
 SG_ APS_B_faultInduced : 54|1@1+ (1,0) [0|0] "" Vector__XXX
 SG_ APS_stateCounter : 55|4@1+ (1,0) [0|0] "" Vector__XXX

VAL_ 945 DAS_TF_multiplexer 0 "Mux0" 1 "Mux1" 2 "Mux2" ;
VAL_ 945 DAS_TF_llType 0 "UNDECIDED" 1 "SOLID" 2 "ROAD_EDGE" 3 "DASHED" 4 "DOUBLE_LANE" 5 "BOTTS_DOTS" 6 "BARRIER" 7 "INVALID" ;
VAL_ 945 DAS_TF_rlType 0 "UNDECIDED" 1 "SOLID" 2 "ROAD_EDGE" 3 "DASHED" 4 "DOUBLE_LANE" 5 "BOTTS_DOTS" 6 "BARRIER" 7 "INVALID" ;
VAL_ 947 UI_trunkRequest 0 "NONE" 1 "MOVE" 2 "STOP" 3 "SNA" ;
VAL_ 947 UI_lightSwitch 0 "AUTO" 1 "ON" 2 "PARKING" 3 "OFF" 4 "SNA" ;
VAL_ 947 UI_summonState 0 "SNA" 1 "IDLE" 2 "PRE_PRIMED" 3 "ACTIVE" ;
VAL_ 947 UI_autopilotPowerStateRequest 0 "NOMINAL" 1 "SENTRY" 2 "SUSPEND" ;
VAL_ 947 UI_shorted12VCellTestMode 0 "DISABLED" 1 "SHADOW" 2 "ACTIVE" ;
VAL_ 947 UI_dcr12VThreshold 0 "OFF" 1 "40_MILLIOHMS" 2 "35_MILLIOHMS" 3 "30_MILLIOHMS" 4 "27_MILLIOHMS" 5 "24_MILLIOHMS" 6 "22_MILLIOHMS" 7 "20_MILLIOHMS" ;
VAL_ 954 USM_matrixIndex 0 "AlertMatrix0" 1 "AlertMatrix1" 2 "AlertMatrix2" 3 "AlertMatrix3" 4 "AlertMatrix4" ;
VAL_ 962 VCLEFT_switchStatusIndex 0 "0" 1 "1" ;
VAL_ 962 VCLEFT_swcLeftTiltRight 0 "SNA" 1 "OFF" 2 "ON" 3 "FAULT" ;
VAL_ 962 VCLEFT_rightMirrorTilt 0 "STOP" 1 "DOWN" 2 "UP" 3 "RIGHT" 4 "LEFT" ;
VAL_ 962 VCLEFT_swcLeftPressed 0 "SNA" 1 "OFF" 2 "ON" 3 "FAULT" ;
VAL_ 962 VCLEFT_frontSeatTrackBack 0 "SNA" 1 "OFF" 2 "ON" 3 "FAULT" ;
VAL_ 962 VCLEFT_swcRightTiltLeft 0 "SNA" 1 "OFF" 2 "ON" 3 "FAULT" ;
VAL_ 962 VCLEFT_frontSeatTrackForward 0 "SNA" 1 "OFF" 2 "ON" 3 "FAULT" ;
VAL_ 962 VCLEFT_swcRightTiltRight 0 "SNA" 1 "OFF" 2 "ON" 3 "FAULT" ;
VAL_ 962 VCLEFT_frontSeatTiltDown 0 "SNA" 1 "OFF" 2 "ON" 3 "FAULT" ;
VAL_ 962 VCLEFT_swcRightPressed 0 "SNA" 1 "OFF" 2 "ON" 3 "FAULT" ;
VAL_ 962 VCLEFT_frontSeatTiltUp 0 "SNA" 1 "OFF" 2 "ON" 3 "FAULT" ;
VAL_ 962 VCLEFT_swcLeftTiltLeft 0 "SNA" 1 "OFF" 2 "ON" 3 "FAULT" ;
VAL_ 962 VCLEFT_frontSeatLiftDown 0 "SNA" 1 "OFF" 2 "ON" 3 "FAULT" ;
VAL_ 962 VCLEFT_frontSeatLiftUp 0 "SNA" 1 "OFF" 2 "ON" 3 "FAULT" ;
VAL_ 962 VCLEFT_frontSeatBackrestBack 0 "SNA" 1 "OFF" 2 "ON" 3 "FAULT" ;
VAL_ 962 VCLEFT_frontSeatBackrestForward 0 "SNA" 1 "OFF" 2 "ON" 3 "FAULT" ;
VAL_ 962 VCLEFT_frontSeatLumbarDown 0 "SNA" 1 "OFF" 2 "ON" 3 "FAULT" ;
VAL_ 962 VCLEFT_frontSeatLumbarUp 0 "SNA" 1 "OFF" 2 "ON" 3 "FAULT" ;
VAL_ 962 VCLEFT_frontSeatLumbarIn 0 "SNA" 1 "OFF" 2 "ON" 3 "FAULT" ;
VAL_ 962 VCLEFT_frontSeatLumbarOut 0 "SNA" 1 "OFF" 2 "ON" 3 "FAULT" ;
VAL_ 962 VCLEFT_frontBuckleSwitch 0 "SNA" 1 "OFF" 2 "ON" 3 "FAULT" ;
VAL_ 962 VCLEFT_frontOccupancySwitch 0 "SNA" 1 "OFF" 2 "ON" 3 "FAULT" ;
VAL_ 962 VCLEFT_rearLeftBuckleSwitch 0 "SNA" 1 "OFF" 2 "ON" 3 "FAULT" ;
VAL_ 962 VCLEFT_rearCenterOccupancySwitch 0 "SNA" 1 "OFF" 2 "ON" 3 "FAULT" ;
VAL_ 962 VCLEFT_rearLeftOccupancySwitch 0 "SNA" 1 "OFF" 2 "ON" 3 "FAULT" ;
VAL_ 962 VCLEFT_rearRightOccupancySwitch 0 "SNA" 1 "OFF" 2 "ON" 3 "FAULT" ;
VAL_ 962 VCLEFT_rearCenterBuckleSwitch 0 "SNA" 1 "OFF" 2 "ON" 3 "FAULT" ;
VAL_ 963 VCRIGHT_switchStatusIndex 0 "0" 1 "1" 2 "INVALID" ;
VAL_ 963 VCRIGHT_frontSeatTrackBack 0 "SNA" 1 "OFF" 2 "ON" 3 "FAULT" ;
VAL_ 963 VCRIGHT_frontSeatTrackForward 0 "SNA" 1 "OFF" 2 "ON" 3 "FAULT" ;
VAL_ 963 VCRIGHT_frontSeatTiltDown 0 "SNA" 1 "OFF" 2 "ON" 3 "FAULT" ;
VAL_ 963 VCRIGHT_frontSeatTiltUp 0 "SNA" 1 "OFF" 2 "ON" 3 "FAULT" ;
VAL_ 963 VCRIGHT_frontSeatLiftDown 0 "SNA" 1 "OFF" 2 "ON" 3 "FAULT" ;
VAL_ 963 VCRIGHT_frontSeatLiftUp 0 "SNA" 1 "OFF" 2 "ON" 3 "FAULT" ;
VAL_ 963 VCRIGHT_frontSeatBackrestBack 0 "SNA" 1 "OFF" 2 "ON" 3 "FAULT" ;
VAL_ 963 VCRIGHT_frontSeatBackrestForward 0 "SNA" 1 "OFF" 2 "ON" 3 "FAULT" ;
VAL_ 963 VCRIGHT_frontSeatLumbarDown 0 "SNA" 1 "OFF" 2 "ON" 3 "FAULT" ;
VAL_ 963 VCRIGHT_frontSeatLumbarUp 0 "SNA" 1 "OFF" 2 "ON" 3 "FAULT" ;
VAL_ 963 VCRIGHT_frontSeatLumbarIn 0 "SNA" 1 "OFF" 2 "ON" 3 "FAULT" ;
VAL_ 963 VCRIGHT_frontSeatLumbarOut 0 "SNA" 1 "OFF" 2 "ON" 3 "FAULT" ;
VAL_ 963 VCRIGHT_frontBuckleSwitch 0 "SNA" 1 "OFF" 2 "ON" 3 "FAULT" ;
VAL_ 963 VCRIGHT_frontOccupancySwitch 0 "SNA" 1 "OFF" 2 "ON" 3 "FAULT" ;
VAL_ 963 VCRIGHT_rearCenterBuckleSwitch 0 "SNA" 1 "OFF" 2 "ON" 3 "FAULT" ;
VAL_ 963 VCRIGHT_rearRightOccupancySwitch 0 "SNA" 1 "OFF" 2 "ON" 3 "FAULT" ;
VAL_ 969 APS_appStatusMonitorState 0 "STATE_UNKNOWN" 1 "STATE_PWR_OFF" 2 "STATE_INIT" 3 "STATE_NOMINAL" 4 "STATE_CRITICAL" 5 "STATE_SHUTTING_DOWN" 6 "STATE_RECOVERY" 7 "NUM_STATES" ;
VAL_ 969 APS_vehBehaviorState 0 "STATE_UNKNOWN" 1 "STATE_APS_AVAILABLE" 2 "STATE_APS_CONTROL" 3 "STATE_APS_BRIDGE_APP" 4 "STATE_APS_BRIDGE_APB" 5 "STATE_APS_FAIL_SAFE" 6 "STATE_APS_OVERRIDE" 7 "STATE_SYSTEM_FAULT" 8 "NUM_STATES" ;
VAL_ 969 APS_canMaster 0 "APS" 1 "APP" 2 "APB" 3 "SNA" ;
VAL_ 969 APS_appGpioState 0 "PWR_DOWN_REBOOT" 1 "DISABLED" 2 "CRITICAL" 3 "HEALTHY" ;
VAL_ 969 APS_eacInternalState 0 "STATE_INIT" 1 "STATE_MOMENTARY" 2 "STATE_CONTINUOUS" 3 "STATE_AUTOPARK" 4 "STATE_INHIBIT" 5 "STATE_OVERRIDE" 6 "STATE_LSS" 7 "NUM_STATES" ;
VAL_ 969 APS_apbStatusMonitorState 0 "STATE_UNKNOWN" 1 "STATE_PWR_OFF" 2 "STATE_INIT" 3 "STATE_NOMINAL" 4 "STATE_CRITICAL" 5 "STATE_SHUTTING_DOWN" 6 "STATE_RECOVERY" 7 "NUM_STATES" ;
VAL_ 969 APS_apbGpioState 0 "PWR_DOWN_REBOOT" 1 "DISABLED" 2 "CRITICAL" 3 "HEALTHY" ;
VAL_ 969 APS_locLimitReason 0 "NOMINAL_DEFAULT" 1 "NOT_IN_DRIVE" 2 "ACC_AND_AEB_UNAVAILABLE" 3 "PRIMARY_AP_NOT_HEALTHY" 4 "RADAR_NOT_HEALTHY" 5 "NO_RADAR_TARGET" 6 "LOC_MONITOR_UNAVAILABLE" 7 "LOC_LIMITS_EXTENDED" ;
VAL_ 969 APS_appPowerStateRequest 0 "NOMINAL" 1 "SENTRY" 2 "SUSPEND" 3 "SLEEP" ;
VAL_ 969 APS_appPowerStateReason 0 "UI_POWER_STATE_REQUEST" 1 "AP_WDOG_UNHEALTHY" 2 "AP_NM_REASON_SET" 3 "AP_NOT_IN_PARK" 4 "GTW_GOTO_FULL_POWER" 5 "AP_POWER_REQUEST_HYSTERESIS" 6 "AP_POWER_REQUEST_OVERHEATING" 7 "AP_POWER_REQUEST_OVERRIDE" 8 "VC_POWER_REQUEST" 9 "LOADSHED_POWER_REQUEST_PENDING" ;
VAL_ 969 APS_apbPowerStateRequest 0 "NOMINAL" 1 "SENTRY" 2 "SUSPEND" 3 "SLEEP" ;
VAL_ 969 APS_apbPowerStateReason 0 "UI_POWER_STATE_REQUEST" 1 "AP_WDOG_UNHEALTHY" 2 "AP_NM_REASON_SET" 3 "AP_NOT_IN_PARK" 4 "GTW_GOTO_FULL_POWER" 5 "AP_POWER_REQUEST_HYSTERESIS" 6 "AP_POWER_REQUEST_OVERHEATING" 7 "AP_POWER_REQUEST_OVERRIDE" 8 "VC_POWER_REQUEST" 9 "LOADSHED_POWER_REQUEST_PENDING" ;
VAL_ 969 APS_heaterStateDebug 0 "OFF" 1 "ON_HEATING" 2 "ON_NOT_HEATING" 3 "FAULT_OPEN" 4 "FAULT_SHORT" 7 "SNA" ;
VAL_ 969 APS_arbState 0 "INIT" 1 "IDLE" 2 "PRIMARY" 3 "SECONDARY" 4 "FAULT" 5 "MIA" 6 "UNKNOWN" 7 "COUNT" ;
VAL_ 977 EPAS3S_resyncStatus 0 "PENDING" 1 "COMPLETE" ;
VAL_ 981 ESP_matrixIndex 0 "AlertMatrix0" 1 "AlertMatrix1" 2 "AlertMatrix2" 3 "AlertMatrix3" 4 "AlertMatrix4" ;
VAL_ 981 ESP_a111_absActive 0 "NOT_ACTIVE" 1 "ACTIVE" ;
VAL_ 986 DAS_TE_multiplexer 0 "START" 1 "LEFT_LANE" 2 "RIGHT_LANE" 3 "HPP" 4 "NAV" 5 "VL" 6 "ACC" 7 "FCM" 8 "IPSO" 9 "END" ;
VAL_ 986 DAS_TE_eventType 0 "NONE" 1 "DRIVER_INTERVENTION" 2 "AUTOSTEER_ABORT" 3 "ANGLE_SATURATION" 4 "ANGLE_RATE_SATURATION" 5 "LDW_LEFT" 6 "LDW_RIGHT" 7 "ALC_ABORT_LEFT" 8 "ALC_ABORT_RIGHT" 9 "SCA_LEFT" 10 "SCA_RIGHT" 11 "TM_EVENT_IPSO" 12 "TM_EVENT_CRASH" 13 "TM_EVENT_AEB" 14 "TM_EVENT_ROB" ;
VAL_ 986 DAS_TE_lcAbortReason 0 "HM_LANE_VIEW_RANGE" 1 "HM_VIRTUAL_LANE_NO_INPUTS" 16 "CAM_MSG_MIA" 17 "CAM_WATCHDOG" 18 "TRAILER_MODE" 19 "SIDE_COLLISION_IMMINENT" 20 "EPAS_EAC_DENIED" 21 "COMPONENT_MIA" 22 "CRUISE_FAULT" 23 "CID_SWITCH_DISABLED" 24 "DRIVING_OFF_NAV" 25 "VEHICLE_SPEED_ABOVE_MAX" 26 "FOLLOWER_OUTPUT_INVALID" 27 "PLANNER_OUTPUT_INVALID" 28 "EPAS_ERROR_CODE" 29 "ACC_CANCEL" 30 "CAMERA_FAILSAFES" 31 "NO_ABORT" ;
VAL_ 987 UI_phoneGpsAccuracy 127 "SNA" ;
VAL_ 991 UI_linkState 0 "NONE" 1 "CELL" 2 "WIFI" ;
VAL_ 991 UI_sentryModeState 0 "OFF" 1 "IDLE" 2 "ARMED" 3 "AWARE" 4 "PANIC" 5 "QUIET" 6 "SNA" ;
VAL_ 1009 RCM2_matrixIndex 0 "AlertMatrix0" 1 "AlertMatrix1" 2 "AlertMatrix2" 3 "AlertMatrix3" 4 "AlertMatrix4" 5 "AlertMatrix5" 6 "AlertMatrix6" 7 "AlertMatrix7" 8 "AlertMatrix8" 9 "AlertMatrix9" 10 "AlertMatrix10" ;
VAL_ 1009 RCM2_a004_crashAlgoWakeup 0 "INACTIVE" 1 "ACTIVE" 3 "SNA" ;
VAL_ 1009 RCM2_a008_factoryMode 0 "DISABLED" 1 "ENABLED" ;
VAL_ 1010 RCM3_matrixIndex 0 "AlertMatrix0" 1 "AlertMatrix1" 2 "AlertMatrix2" ;
VAL_ 1011 UI_odometer 16777215 "SNA" ;
VAL_ 1012 APP_cameraPosition 0 "INVALID" 1 "MAIN" 2 "NARROW" 3 "FISHEYE" 4 "L_PILLAR" 5 "R_PILLAR" 6 "L_REPEATER" 7 "R_REPEATER" 8 "BACKUP" 9 "SELFIE" ;
VAL_ 1012 APP_backupCamExtPitchCal 511 "SNA" ;
VAL_ 1012 APP_fisheyeCamExtPitchCal 511 "SNA" ;
VAL_ 1012 APP_lPillarCamExtPitchCal 511 "SNA" ;
VAL_ 1012 APP_lRepeatCamExtPitchCal 511 "SNA" ;
VAL_ 1012 APP_mainCamExtPitchCal 511 "SNA" ;
VAL_ 1012 APP_narrowCamExtPitchCal 511 "SNA" ;
VAL_ 1012 APP_rPillarCamExtPitchCal 511 "SNA" ;
VAL_ 1012 APP_rRepeatCamExtPitchCal 511 "SNA" ;
VAL_ 1012 APP_backupCamExtYawCal 511 "SNA" ;
VAL_ 1012 APP_fisheyeCamExtYawCal 511 "SNA" ;
VAL_ 1012 APP_lPillarCamExtYawCal 511 "SNA" ;
VAL_ 1012 APP_lRepeatCamExtYawCal 511 "SNA" ;
VAL_ 1012 APP_mainCamExtYawCal 511 "SNA" ;
VAL_ 1012 APP_narrowCamExtYawCal 511 "SNA" ;
VAL_ 1012 APP_rPillarCamExtYawCal 511 "SNA" ;
VAL_ 1012 APP_rRepeatCamExtYawCal 511 "SNA" ;
VAL_ 1012 APP_backupCalibTime 127 "SNA" ;
VAL_ 1012 APP_fisheyeCalibTime 127 "SNA" ;
VAL_ 1012 APP_lPillarCalibTime 127 "SNA" ;
VAL_ 1012 APP_lRepeatCalibTime 127 "SNA" ;
VAL_ 1012 APP_mainCalibTime 127 "SNA" ;
VAL_ 1012 APP_narrowCalibTime 127 "SNA" ;
VAL_ 1012 APP_rPillarCalibTime 127 "SNA" ;
VAL_ 1012 APP_rRepeatCalibTime 127 "SNA" ;
VAL_ 1012 APP_backupCalibProgress 127 "SNA" ;
VAL_ 1012 APP_fisheyeCalibProgress 127 "SNA" ;
VAL_ 1012 APP_lPillarCalibProgress 127 "SNA" ;
VAL_ 1012 APP_lRepeatCalibProgress 127 "SNA" ;
VAL_ 1012 APP_mainCalibProgress 127 "SNA" ;
VAL_ 1012 APP_narrowCalibProgress 127 "SNA" ;
VAL_ 1012 APP_rPillarCalibProgress 127 "SNA" ;
VAL_ 1012 APP_rRepeatCalibProgress 127 "SNA" ;
VAL_ 1013 VCFRONT_indicatorLeftRequest 0 "OFF" 1 "ACTIVE_LOW" 2 "ACTIVE_HIGH" ;
VAL_ 1013 VCFRONT_indicatorRightRequest 0 "OFF" 1 "ACTIVE_LOW" 2 "ACTIVE_HIGH" ;
VAL_ 1013 VCFRONT_hazardLightRequest 0 "NONE" 1 "BUTTON" 2 "LOCK" 3 "UNLOCK" 4 "MISLOCK" 5 "CRASH" 6 "CAR_ALARM" 7 "DAS" 8 "UDS" ;
VAL_ 1013 VCFRONT_ambientLightingBrightnes 255 "SNA" ;
VAL_ 1013 VCFRONT_switchLightingBrightness 255 "SNA" ;
VAL_ 1013 VCFRONT_lightingCoreState 0 "OFF" 1 "POS_PARK" 2 "DRL" 3 "DRL_PLUS_REAR_POS_PARK" 4 "LOW_BEAMS" 15 "SNA" ;
VAL_ 1013 VCFRONT_highBeamLatchingState 0 "SNA" 1 "UNLATCHED" 2 "LATCHING" 3 "LATCHED" ;
VAL_ 1016 UI_autopilotControlRequest 0 "LEGACY_LAT_CTRL" 1 "NEXT_GEN_CTRL" ;
VAL_ 1016 UI_curvSpeedAdaptDisable 0 "ON" 1 "OFF" ;
VAL_ 1016 UI_lssLkaEnabled 0 "OFF" 1 "ON" ;
VAL_ 1016 UI_lssLdwEnabled 0 "OFF" 1 "ON" ;
VAL_ 1016 UI_exceptionListEnable 0 "OFF" 1 "ON" ;
VAL_ 1016 UI_roadCheckDisable 0 "ON" 1 "OFF" ;
VAL_ 1016 UI_driveOnMapsEnable 0 "OFF" 1 "ON" ;
VAL_ 1016 UI_handsOnRequirementDisable 0 "ON" 1 "OFF" ;
VAL_ 1016 UI_fuseLanesDisable 0 "ON" 1 "OFF" ;
VAL_ 1016 UI_fuseHPPDisable 0 "ON" 1 "OFF" ;
VAL_ 1016 UI_fuseVehiclesDisable 0 "ON" 1 "OFF" ;
VAL_ 1016 UI_visionSpeedType 0 "DISABLED" 1 "ONE_SECOND" 2 "TWO_SECOND" 3 "OPTIMIZED" ;
VAL_ 1016 UI_curvatureDatabaseOnly 0 "OFF" 1 "ON" ;
VAL_ 1016 UI_lssElkEnabled 0 "OFF" 1 "ON" ;
VAL_ 1016 UI_summonExitType 0 "STRAIGHT" 1 "TURN_RIGHT" 2 "TURN_LEFT" 3 "SNA" ;
VAL_ 1016 UI_summonEntryType 0 "STRAIGHT" 1 "TURN_RIGHT" 2 "TURN_LEFT" 3 "SNA" ;
VAL_ 1016 UI_selfParkRequest 0 "NONE" 1 "SELF_PARK_FORWARD" 2 "SELF_PARK_REVERSE" 3 "ABORT" 4 "PRIME" 5 "PAUSE" 6 "RESUME" 7 "AUTO_SUMMON_FORWARD" 8 "AUTO_SUMMON_REVERSE" 9 "AUTO_SUMMON_CANCEL" 10 "AUTO_SUMMON_PRIMED" 11 "SMART_SUMMON" 12 "SMART_SUMMON_NO_OP" 15 "SNA" ;
VAL_ 1016 UI_summonReverseDist 63 "SNA" ;
VAL_ 1016 UI_drivingSide 0 "LEFT" 1 "RIGHT" 2 "UNKNOWN" ;
VAL_ 1016 UI_accFollowDistanceSetting 0 "1" 1 "2" 2 "3" 3 "4" 4 "5" 5 "6" 6 "7" 7 "SNA" ;
VAL_ 1016 UI_followNavRouteEnable 0 "OFF" 1 "ON" ;
VAL_ 1016 UI_ulcSpeedConfig 0 "DISABLED" 1 "MILD" 2 "AVERAGE" 3 "MAD_MAX" ;
VAL_ 1016 UI_ulcBlindSpotConfig 0 "STANDARD" 1 "AGGRESSIVE" 2 "MAD_MAX" ;
VAL_ 1016 UI_smartSummonType 0 "PIN_DROP" 1 "FIND_ME" 2 "SMART_AUTOPARK" ;
VAL_ 1016 UI_source3D 0 "Z_FROM_MAP" 1 "Z_FROM_PATH_PREDICTION" 2 "XYZ_PREDICTION" ;
VAL_ 1018 APP_mainCameraLUX 254 "SATURATED" 255 "SNA" ;
VAL_ 1018 APP_narrowCameraLUX 254 "SATURATED" 255 "SNA" ;
VAL_ 1018 APP_fisheyeCameraLUX 254 "SATURATED" 255 "SNA" ;
VAL_ 1018 APP_lRepeatCameraLUX 254 "SATURATED" 255 "SNA" ;
VAL_ 1018 APP_rRepeatCameraLUX 254 "SATURATED" 255 "SNA" ;
VAL_ 1018 APP_lPillarCameraLUX 254 "SATURATED" 255 "SNA" ;
VAL_ 1018 APP_rPillarCameraLUX 254 "SATURATED" 255 "SNA" ;
VAL_ 1018 APP_backupCameraLUX 254 "SATURATED" 255 "SNA" ;
VAL_ 1020 APP_decisionTemperature 0 "UNKNOWN" ;
VAL_ 1020 APP_pascalTemperature 0 "UNKNOWN" ;
VAL_ 1020 APP_parkerATemperature 0 "UNKNOWN" ;
VAL_ 1020 APP_parkerBTemperature 0 "UNKNOWN" ;
VAL_ 1020 APP_pascalExtTemperature 0 "UNKNOWN" ;
VAL_ 1020 APP_parkerExtTemperature 0 "UNKNOWN" ;
VAL_ 1020 APP_pascalHeaterDecision 0 "OFF" 1 "ON" ;
VAL_ 1021 UI_autopilotControlIndex 0 "0" 1 "1" 2 "2" 3 "3" 4 "4" 5 "5" 6 "6" 7 "7" ;
VAL_ 1021 UI_hovEnabled 0 "OFF" 1 "ON" ;
VAL_ 1021 UI_donDisableAutoWiperDuration 0 "DEFAULT" 1 "5_S" 2 "15_S" 3 "30_S" 4 "60_S" 5 "120_S" 6 "OFF" ;
VAL_ 1021 UI_donDisableOnAutoWiperSpeed 0 "OFF" 1 "1" 2 "2" 3 "3" 4 "4" 5 "5" 6 "6" 7 "7" 8 "8" 9 "9" 10 "10" 11 "11" 12 "12" 13 "13" 14 "14" 15 "INVALID" ;
VAL_ 1021 UI_blindspotMinSpeed 0 "DEFAULT" 1 "5_KPH" 2 "10_KPH" 3 "15_KPH" 4 "20_KPH" 5 "25_KPH" 6 "30_KPH" 7 "35_KPH" 8 "40_KPH" 9 "45_KPH" 10 "OFF" ;
VAL_ 1021 UI_blindspotDistance 0 "DEFAULT" 1 "0P5_M" 2 "1_M" 3 "2_M" 4 "4_M" 5 "OFF" ;
VAL_ 1021 UI_blindspotTTC 0 "DEFAULT" 1 "0P5_S" 2 "1_S" 3 "2_S" 4 "4_S" 5 "3_S" 6 "5_S" 7 "OFF" ;
VAL_ 1021 UI_donStopEndOfRampBuffer 0 "DEFAULT" 1 "15_M" 2 "30_M" 3 "45_M" 4 "OFF" ;
VAL_ 1021 UI_donDisableCutin 0 "OFF" 1 "ON" ;
VAL_ 1021 UI_smartSetSpeedOffsetType 0 "FIXED_OFFSET" 1 "PERCENTAGE_OFFSET" ;
VAL_ 1021 UI_apmv3Branch 0 "LIVE" 1 "STAGE" 2 "DEV" 3 "STAGE2" 4 "EAP" 5 "DEMO" ;
VAL_ 1021 UI_homelinkNearby 0 "NOT_NEARBY" 1 "NEARBY" ;
VAL_ 1021 UI_autosteerActivation 0 "SINGLE_CLICK" 1 "DOUBLE_CLICK" ;
VAL_ 1021 UI_fsdBetaRequest 0 "NOT_ACTIVE" 1 "ACTIVE" ;
VAL_ 1021 UI_autoTurnSignalMode 0 "OFF" 1 "AUTO_CANCEL" ;
VAL_ 1021 UI_autopilotDrivingProfile 0 "CHILL" 1 "NORMAL" 2 "ASSERTIVE" ;
VAL_ 1022 APP_summonState 0 "INIT" 1 "IDLE" 2 "ARMED" 3 "ACTIVE" 4 "COMPLETE" 5 "FAULT" 6 "UNAVAILABLE" ;
VAL_ 1033 DAS_nmWakeUpReason 0 "NONE" 1 "CAN_VEH" 2 "CAN_HVS" 3 "WANTTOCHARGE" 4 "CRITICALALERT" 5 "WANTTOWARM" ;
VAL_ 1033 DAS_nmKeepAwakeReason 0 "NONE_SNA" 1 "CTRS_CLOSED" 2 "CRITICAL_ALERT" 3 "FC_CTR_CLEANING" 4 "HVP_ACTIVE" 5 "BMS_ACTIVE" 6 "CP_ACTIVE" ;
VAL_ 1049 APS_nmWakeUpReason 0 "NONE" 1 "CAN_VEH" 2 "CAN_HVS" 3 "WANTTOCHARGE" 4 "CRITICALALERT" 5 "WANTTOWARM" ;
VAL_ 1049 APS_nmKeepAwakeReason 0 "NONE_SNA" 1 "CTRS_CLOSED" 2 "CRITICAL_ALERT" 3 "FC_CTR_CLEANING" 4 "HVP_ACTIVE" 5 "BMS_ACTIVE" 6 "CP_ACTIVE" ;
VAL_ 1050 USM_nmKeepAwakeReason 0 "NONE_SNA" 1 "CTRS_CLOSED" 2 "CRITICAL_ALERT" 3 "FC_CTR_CLEANING" 4 "HVP_ACTIVE" 5 "BMS_ACTIVE" 6 "CP_ACTIVE" ;
VAL_ 1050 USM_nmWakeUpReason 0 "NONE" 1 "CAN_VEH" 2 "CAN_HVS" 3 "WANTTOCHARGE" 4 "CRITICALALERT" 5 "WANTTOWARM" ;
VAL_ 1056 APS_primaryTurbo 0 "A" 1 "B" 2 "UNKNOWN" ;
VAL_ 1056 APS_A_arbState 0 "INIT" 1 "IDLE" 2 "PRIMARY" 3 "SECONDARY" 4 "FAULT" 5 "MIA" 6 "UNKNOWN" 7 "COUNT" ;
VAL_ 1056 APS_A_powerState 0 "IDLE" 1 "AP_ON_PREPARE" 2 "AP_ON_PREPARE_WAIT_FOR_ACK" 3 "AP_ON_PREPARE_WAIT_FOR_RESPONSE" 4 "AP_ON_READY" 5 "AP_ON_READY_WAIT_FOR_ACK" 6 "AP_ON_READY_WAIT_FOR_RESPONSE" 7 "AP_BOOTING" 8 "AP_IN_COREBOOT" 9 "AP_ON" 10 "AP_WAIT_FOR_SHUTDOWN" 11 "AP_OFF_PREPARE" 12 "AP_OFF_READY" 13 "AP_OFF_READY_WAIT_FOR_ACK" 14 "AP_OFF_READY_WAIT_FOR_RESPONSE" 15 "AP_OFF_ABORT" 16 "AP_OFF_ABORT_WAIT_FOR_ACK" 17 "AP_SUSPENDED" 18 "SOC_OFF_READY" 19 "SOC_OFF" 20 "SOC_OFF_ABORT" 21 "FAULT" 22 "MIA" 23 "UNKNOWN" 24 "COUNT" ;
VAL_ 1056 APS_A_sleepState 0 "IDLE" 1 "WAIT_FOR_BUS_SILENCE" 2 "READY" 3 "GOING_TO_SLEEP" 4 "SLEEPING" 5 "ABORT" 6 "FAULT" 7 "MIA" 8 "UNKNOWN" 9 "COUNT" ;
VAL_ 1056 APS_A_resetState 0 "NOT_RESETTING" 1 "RESETTING" 2 "FAULT" 3 "MIA" 4 "UNKNOWN" 5 "COUNT" ;
VAL_ 1056 APS_A_faultState 0 "NONE" 1 "GIC" 2 "MIF_ECC_CORRECTED" 3 "MIF_ECC_UNCORRECTED" 4 "MIF0_DFI_ALERT" 5 "MIF1_DFI_ALERT" 6 "MIF2_DFI_ALERT" 7 "MIF3_DFI_ALERT" 8 "MIF4_DFI_ALERT" 9 "MIF5_DFI_ALERT" 10 "MIF6_DFI_ALERT" 11 "MIF7_DFI_ALERT" 12 "MIF_ECC_AP" 13 "DROOP_CPUCL0" 14 "DROOP_CPUCL1" 15 "DROOP_CPUCL2" 16 "DROOP_GPU" 17 "DROOP_TRIP" 18 "CPU_FAULT" 19 "WDT" 20 "TRIP0_FAULT" 21 "TRIP1_FAULT" 22 "SOFTWARE_FAULT" 23 "SCS" 24 "UNEXPECTED" 25 "MIA" 26 "UNKNOWN" 27 "COUNT" ;
VAL_ 1056 APS_secondaryTurbo 0 "A" 1 "B" 2 "UNKNOWN" ;
VAL_ 1056 APS_B_arbState 0 "INIT" 1 "IDLE" 2 "PRIMARY" 3 "SECONDARY" 4 "FAULT" 5 "MIA" 6 "UNKNOWN" 7 "COUNT" ;
VAL_ 1056 APS_B_powerState 0 "IDLE" 1 "AP_ON_PREPARE" 2 "AP_ON_PREPARE_WAIT_FOR_ACK" 3 "AP_ON_PREPARE_WAIT_FOR_RESPONSE" 4 "AP_ON_READY" 5 "AP_ON_READY_WAIT_FOR_ACK" 6 "AP_ON_READY_WAIT_FOR_RESPONSE" 7 "AP_BOOTING" 8 "AP_IN_COREBOOT" 9 "AP_ON" 10 "AP_WAIT_FOR_SHUTDOWN" 11 "AP_OFF_PREPARE" 12 "AP_OFF_READY" 13 "AP_OFF_READY_WAIT_FOR_ACK" 14 "AP_OFF_READY_WAIT_FOR_RESPONSE" 15 "AP_OFF_ABORT" 16 "AP_OFF_ABORT_WAIT_FOR_ACK" 17 "AP_SUSPENDED" 18 "SOC_OFF_READY" 19 "SOC_OFF" 20 "SOC_OFF_ABORT" 21 "FAULT" 22 "MIA" 23 "UNKNOWN" 24 "COUNT" ;
VAL_ 1056 APS_B_sleepState 0 "IDLE" 1 "WAIT_FOR_BUS_SILENCE" 2 "READY" 3 "GOING_TO_SLEEP" 4 "SLEEPING" 5 "ABORT" 6 "FAULT" 7 "MIA" 8 "UNKNOWN" 9 "COUNT" ;
VAL_ 1056 APS_B_resetState 0 "NOT_RESETTING" 1 "RESETTING" 2 "FAULT" 3 "MIA" 4 "UNKNOWN" 5 "COUNT" ;
VAL_ 1056 APS_B_faultState 0 "NONE" 1 "GIC" 2 "MIF_ECC_CORRECTED" 3 "MIF_ECC_UNCORRECTED" 4 "MIF0_DFI_ALERT" 5 "MIF1_DFI_ALERT" 6 "MIF2_DFI_ALERT" 7 "MIF3_DFI_ALERT" 8 "MIF4_DFI_ALERT" 9 "MIF5_DFI_ALERT" 10 "MIF6_DFI_ALERT" 11 "MIF7_DFI_ALERT" 12 "MIF_ECC_AP" 13 "DROOP_CPUCL0" 14 "DROOP_CPUCL1" 15 "DROOP_CPUCL2" 16 "DROOP_GPU" 17 "DROOP_TRIP" 18 "CPU_FAULT" 19 "WDT" 20 "TRIP0_FAULT" 21 "TRIP1_FAULT" 22 "SOFTWARE_FAULT" 23 "SCS" 24 "UNEXPECTED" 25 "MIA" 26 "UNKNOWN" 27 "COUNT" ;
